VERSION "10.9.1"

NS_ :

BS_:

BU_: ADAS_Info AMP CPD DUMMY_DEBUG DUMMY_ECU EASC HUD MHU XGW_Info

BO_ 18 MHU_Climate_control: 8 CPD
  SG_ CPD_MHU_Climate_control : 7|2@0+ (1,0) [0|3] "" MHU

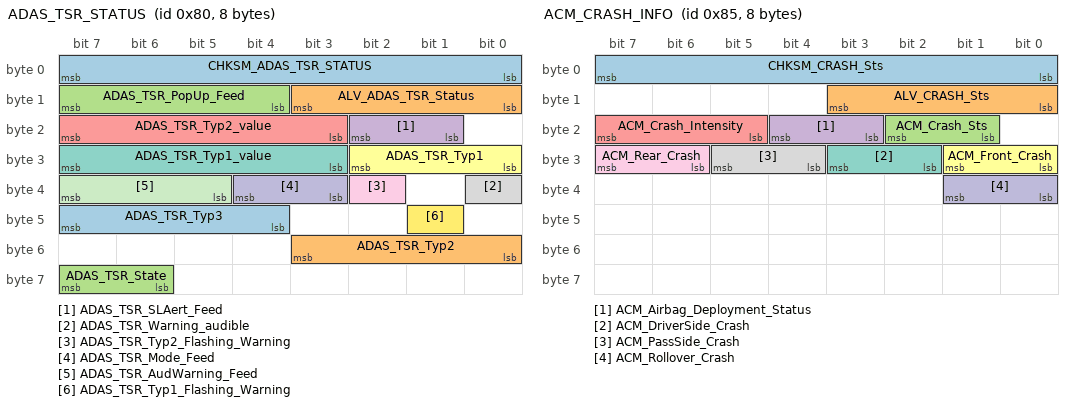
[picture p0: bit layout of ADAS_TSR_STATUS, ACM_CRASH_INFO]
BO_ 128 ADAS_TSR_STATUS: 8 ADAS_Info
  SG_ CHKSM_ADAS_TSR_STATUS : 7|8@0+ (1,0) [0|255] "" HUD,MHU
  SG_ ALV_ADAS_TSR_Status : 11|4@0+ (1,0) [0|14] "" HUD,MHU
  SG_ ADAS_TSR_PopUp_Feed : 15|4@0+ (1,0) [0|15] "-" MHU
  SG_ ADAS_TSR_SLAert_Feed : 18|2@0+ (1,0) [0|3] "-" HUD,MHU
  SG_ ADAS_TSR_Typ2_value : 23|5@0+ (1,0) [0|31] "-" HUD,MHU
  SG_ ADAS_TSR_Typ1 : 26|3@0+ (1,0) [0|7] "-" HUD,MHU
  SG_ ADAS_TSR_Typ1_value : 31|5@0+ (1,0) [0|31] "-" HUD,MHU
  SG_ ADAS_TSR_Warning_audible : 32|1@0+ (1,0) [0|1] "-" HUD,MHU
  SG_ ADAS_TSR_Typ2_Flashing_Warning : 34|1@0+ (1,0) [0|1] "-" HUD,MHU
  SG_ ADAS_TSR_Mode_Feed : 36|2@0+ (1,0) [0|3] "-" HUD,MHU
  SG_ ADAS_TSR_AudWarning_Feed : 39|3@0+ (1,0) [0|1] "-" HUD,MHU
  SG_ ADAS_TSR_Typ1_Flashing_Warning : 41|1@0+ (1,0) [0|1] "-" HUD,MHU
  SG_ ADAS_TSR_Typ3 : 47|4@0+ (1,0) [0|15] "-" HUD,MHU
  SG_ ADAS_TSR_Typ2 : 51|4@0+ (1,0) [0|15] "-" HUD,MHU
  SG_ ADAS_TSR_State : 63|2@0+ (1,0) [0|3] "-" HUD,MHU

BO_ 130 ADAS_CMP_MHU: 8 ADAS_Info
  SG_ CHKSM_ADAS_CMP_MHU : 7|8@0+ (1,0) [0|255] "" MHU
  SG_ ALV_ADAS_CMP_MHU : 11|4@0+ (1,0) [0|14] "" MHU
  SG_ ADAS_TakeOver_Request : 23|5@0+ (1,0) [0|31] "-" MHU
  SG_ ADAS_Sounds_Feed : 28|5@0+ (1,0) [0|31] "-" MHU
  SG_ SECCAN_ADAS_CMP_MHU : 63|8@0+ (1,0) [0|255] "" MHU

BO_ 133 ACM_CRASH_INFO: 8 XGW_Info
  SG_ CHKSM_CRASH_Sts : 7|8@0+ (1,0) [0|255] "" MHU
  SG_ ALV_CRASH_Sts : 11|4@0+ (1,0) [0|14] "" MHU
  SG_ ACM_Crash_Sts : 18|2@0+ (1,0) [0|3] "" MHU
  SG_ ACM_Airbag_Deployment_Status : 20|2@0+ (1,0) [0|3] "-" MHU
  SG_ ACM_Crash_Intensity : 23|3@0+ (1,0) [0|7] "" MHU
  SG_ ACM_Front_Crash : 25|2@0+ (1,0) [0|3] "-" MHU
  SG_ ACM_DriverSide_Crash : 27|2@0+ (1,0) [0|3] "" MHU
  SG_ ACM_PassSide_Crash : 29|2@0+ (1,0) [0|3] "-" MHU
  SG_ ACM_Rear_Crash : 31|2@0+ (1,0) [0|3] "-" MHU
  SG_ ACM_Rollover_Crash : 33|2@0+ (1,0) [0|3] "-" MHU

BO_ 134 ACM_CRASH_DELTA_V_INFO: 8 XGW_Info
 SG_ ACM_CrashDeltaV_PackID : 7|8@0+ (1,0) [1|9] ""  MHU
 SG_ ACM_DeltaVx_01 : 15|9@0+ (1,-250) [-250|250] "Km/h"  MHU
 SG_ ACM_DeltaVx_02 : 22|9@0+ (1,-250) [-250|250] "Km/h"  MHU
 SG_ ACM_DeltaVx_03 : 29|9@0+ (1,-250) [-250|250] "Km/h"  MHU
 SG_ ACM_DeltaVy_01 : 36|9@0+ (1,-250) [-250|250] "Km/h"  MHU
 SG_ ACM_DeltaVy_02 : 43|9@0+ (1,-250) [-250|250] "Km/h"  MHU
 SG_ ACM_DeltaVy_03 : 50|9@0+ (1,-250) [-250|250] "Km/h"  MHU

BO_ 147 IDB_MILEAGE: 4 XGW_Info
  SG_ CHKSM_MILEAGE : 7|8@0+ (1,0) [0|255] "" MHU
  SG_ ALIVE_MILEAGE : 11|4@0+ (1,0) [0|14] "" MHU
  SG_ Mileage : 23|16@0+ (1,0) [0|65535] "cm" MHU

BO_ 149 IDB_FUNCTION: 8 XGW_Info
  SG_ CHKSM_IDB_FUNCTION : 7|8@0+ (1,0) [0|255] "" MHU
  SG_ ALV_IDB_FUNCTION : 11|4@0+ (1,0) [0|14] "" MHU
  SG_ STAT_ABS : 13|2@0+ (1,0) [0|3] "" MHU
  SG_ AYC_Active : 17|2@0+ (1,0) [0|3] "Bit" MHU
  SG_ ASR_Active : 19|2@0+ (1,0) [0|3] "-" MHU
  SG_ STAT_DSC : 21|2@0+ (1,0) [0|3] "-" MHU
  SG_ DSC_Active : 23|2@0+ (1,0) [0|3] "" MHU
  SG_ HBA_ActiveSignal : 25|2@0+ (1,0) [0|3] "" MHU
  SG_ ARM_ActiveSignal : 27|2@0+ (1,0) [0|3] "-" MHU
  SG_ STAT_AutoHazardBlinking : 29|2@0+ (1,0) [0|3] "Bit" MHU
  SG_ MSR_Active : 31|2@0+ (1,0) [0|3] "-" MHU
  SG_ HSA_ActiveSignal : 33|2@0+ (1,0) [0|3] "" MHU
  SG_ EPBi_ECD_ActiveSignal : 35|2@0+ (1,0) [0|3] "" MHU
  SG_ TSM_Active : 37|2@0+ (1,0) [0|3] "-" MHU
  SG_ HAS_Available : 41|2@0+ (1,0) [0|3] "" MHU
  SG_ STAT_EBD : 43|2@0+ (1,0) [0|3] "" MHU
  SG_ EBD_Active : 45|2@0+ (1,0) [0|3] "" MHU
  SG_ ST_BRG_MSA : 55|4@0+ (1,0) [0|15] "" MHU

BO_ 150 MHU_IDB_Mode_Select: 2 MHU
  SG_ CHKSM_MHU_IDB_Mode_Select : 7|8@0+ (1,0) [0|255] "" XGW_Info
  SG_ ALV_MHU_IDB_Mode_Select : 11|4@0+ (1,0) [0|14] "" XGW_Info
  SG_ MHU_IDB_Mode_Select_Signal : 15|2@0+ (1,0) [0|3] "" XGW_Info

BO_ 200 ESC_FUNCTION: 8 XGW_Info
 SG_ CHKSM_ESC_FUNCTION : 7|8@0+ (1,0) [0|255] "" MHU
 SG_ ALV_ESC_FUNCTION : 11|4@0+ (1,0) [0|14] "" MHU
 SG_ AVH_ActiveStatus : 17|2@0+ (1,0) [0|3] "" MHU
 SG_ AVH_DispMSG : 19|2@0+ (1,0) [0|3] "" MHU
 SG_ AVH_LampReq : 21|2@0+ (1,0) [0|3] "" MHU

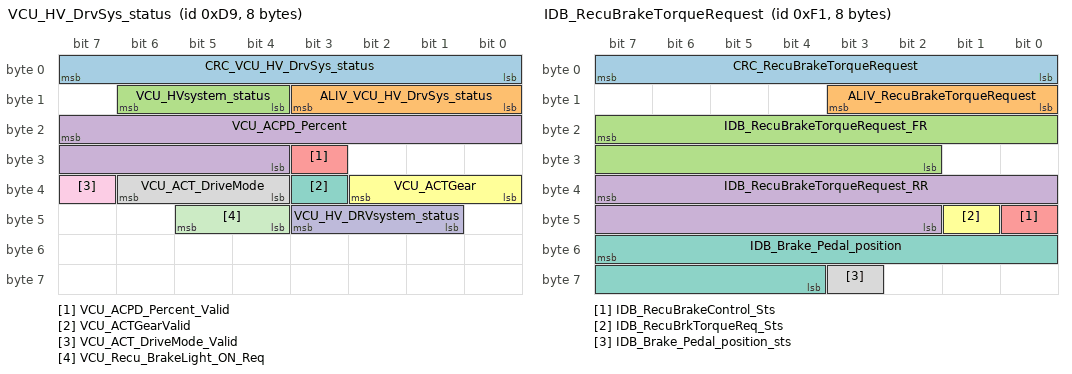
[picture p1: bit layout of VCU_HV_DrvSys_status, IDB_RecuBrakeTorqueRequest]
BO_ 217 VCU_HV_DrvSys_status: 8 XGW_Info
  SG_ CRC_VCU_HV_DrvSys_status : 7|8@0+ (1,0) [0|255] "" CPD,MHU
  SG_ ALIV_VCU_HV_DrvSys_status : 11|4@0+ (1,0) [0|14] "" CPD,MHU
  SG_ VCU_HVsystem_status : 14|3@0+ (1,0) [0|7] "-" CPD,MHU
  SG_ VCU_ACPD_Percent : 23|12@0+ (0.0625,0) [0|100] "%" CPD,MHU
  SG_ VCU_ACPD_Percent_Valid : 27|1@0+ (1,0) [0|1] "" CPD,MHU
  SG_ VCU_ACTGear : 34|3@0+ (1,0) [0|7] "" CPD,HUD,MHU
  SG_ VCU_ACTGearValid : 35|1@0+ (1,0) [0|1] "" CPD,HUD,MHU
  SG_ VCU_ACT_DriveMode : 38|3@0+ (1,0) [0|7] "" CPD,HUD,MHU
  SG_ VCU_ACT_DriveMode_Valid : 39|1@0+ (1,0) [0|1] "-" CPD,HUD,MHU
  SG_ VCU_HV_DRVsystem_status : 43|3@0+ (1,0) [0|7] "" CPD,MHU
  SG_ VCU_Recu_BrakeLight_ON_Req : 45|2@0+ (1,0) [0|3] "-" CPD,MHU

BO_ 241 IDB_RecuBrakeTorqueRequest: 8 XGW_Info
  SG_ CRC_RecuBrakeTorqueRequest : 7|8@0+ (1,0) [0|255] "" DUMMY_ECU,MHU
  SG_ ALIV_RecuBrakeTorqueRequest : 11|4@0+ (1,0) [0|14] "" DUMMY_ECU,MHU
  SG_ IDB_RecuBrakeTorqueRequest_FR : 23|14@0+ (1,0) [0|8000] "Nm" DUMMY_ECU
  SG_ IDB_RecuBrakeTorqueRequest_RR : 39|14@0+ (1,0) [0|8000] "Nm" DUMMY_ECU
  SG_ IDB_RecuBrakeControl_Sts : 40|1@0+ (1,0) [0|1] "" DUMMY_ECU
  SG_ IDB_RecuBrkTorqueReq_Sts : 41|1@0+ (1,0) [0|1] "" DUMMY_ECU
  SG_ IDB_Brake_Pedal_position : 55|12@0+ (0.0625,0) [0|100] "%" MHU
  SG_ IDB_Brake_Pedal_position_sts : 59|1@0+ (1,0) [0|1] "" MHU

BO_ 256 MHU_Vehicle_Info: 8 MHU
  SG_ CHKSM_MHU_VEH_INFO : 7|8@0+ (1,0) [0|255] "" ADAS_Info,HUD,XGW_Info
  SG_ ALV_MHU_VEH_INFO : 11|4@0+ (1,0) [0|14] "" ADAS_Info,HUD,XGW_Info
  SG_ MHU_UserProfileId : 23|4@0+ (1,0) [0|15] "-" HUD,XGW_Info
  SG_ MHU_Connectivity_Status : 47|3@0+ (1,0) [0|7] "" ADAS_Info,XGW_Info

BO_ 257 MHU_DMS_STATUS: 8 MHU
  SG_ DMS_Setting : 1|2@0+ (1,0) [0|3] "-" ADAS_Info
  SG_ DMS_Driver_registration_request : 3|2@0+ (1,0) [0|3] "-" ADAS_Info
  SG_ DMS_Driver_ID_request : 7|4@0+ (1,0) [0|15] "-" ADAS_Info
  SG_ DMS_Status : 11|2@0+ (1,0) [0|3] "-" ADAS_Info
  SG_ DMS_Image_processing : 15|3@0+ (1,0) [0|7] "-" ADAS_Info
  SG_ DMS_DriverConfirmDMSWarning : 23|1@0+ (1,0) [0|1] "" ADAS_Info
  SG_ SECCAN_DMS : 63|8@0+ (1,0) [0|255] "" ADAS_Info

BO_ 258 BCM_LOGICAL_CLAMP: 3 XGW_Info
  SG_ CHKSM_BCM_LOGICAL_CLAMP : 7|8@0+ (1,0) [0|255] "" HUD,MHU
  SG_ ALIVE_BCM_LOGICAL_CLAMP : 11|4@0+ (1,0) [0|14] "" HUD,MHU
  SG_ STAT_CL30s_Light_L : 13|2@0+ (1,0) [0|3] "" MHU
  SG_ STAT_CL30s_L : 15|2@0+ (1,0) [0|3] "Bit" HUD,MHU
  SG_ STAT_CL15Wup_L : 17|2@0+ (1,0) [0|3] "Bit" MHU
  SG_ STAT_CrankRelayHW_BCM : 19|2@0+ (1,0) [0|3] "Bit" MHU

BO_ 259 BCM_ENERGY_MANAGEMENT: 8 XGW_Info
  SG_ REQ_ConsumerControlSeatMassage : 13|2@0+ (1,0) [0|3] "" MHU
  SG_ REQ_ConsumerControlWirelessCharg : 15|2@0+ (1,0) [0|3] "-" MHU
  SG_ REQ_ConsumerControlAudioVolumeCo : 18|3@0+ (1,0) [0|7] "-" MHU
  SG_ REQ_ConsumerControlRearDefrost : 23|2@0+ (1,0) [0|3] "-" MHU
  SG_ REQ_ConsumerControlSeatHeatingRe : 31|8@0+ (1,0) [0|100] "%" MHU
  SG_ REQ_ConsumerControlSeatVentilati : 39|8@0+ (1,0) [0|100] "%" MHU
  SG_ REQ_ConsumerControlSeatHeatingFr : 47|8@0+ (1,0) [0|100] "%" MHU
  SG_ DriverIdealTimerCount : 55|8@0+ (5,0) [0|1275] "s" MHU
  SG_ REQ_ConsumerControlVentilationCl : 63|8@0+ (1,0) [0|100] "%" MHU

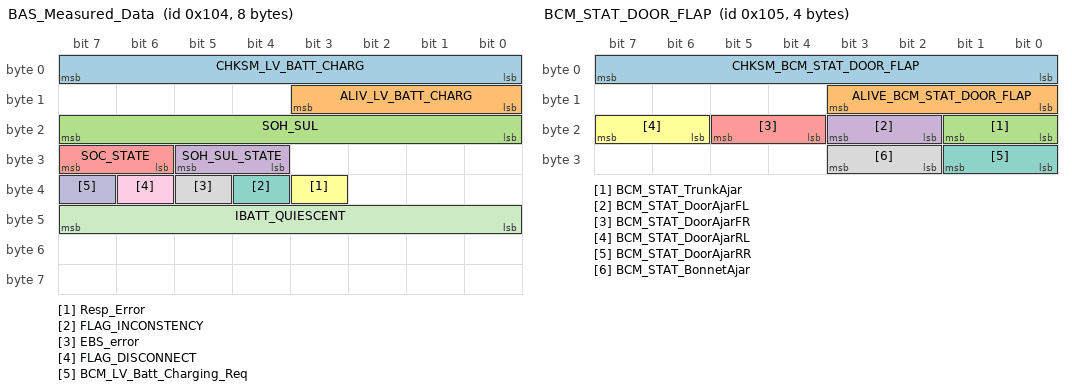
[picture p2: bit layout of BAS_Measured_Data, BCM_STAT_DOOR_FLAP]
BO_ 260 BAS_Measured_Data: 8 XGW_Info
  SG_ CHKSM_LV_BATT_CHARG : 7|8@0+ (1,0) [0|255] "" MHU
  SG_ ALIV_LV_BATT_CHARG : 11|4@0+ (1,0) [0|14] "" MHU
  SG_ SOH_SUL : 23|8@0+ (1,0) [0|100] "%" MHU
  SG_ SOH_SUL_STATE : 29|2@0+ (1,0) [0|3] "" MHU
  SG_ SOC_STATE : 31|2@0+ (1,0) [0|3] "%" MHU
  SG_ Resp_Error : 35|1@0+ (1,0) [0|1] "" MHU
  SG_ FLAG_INCONSTENCY : 36|1@0+ (1,0) [0|1] "%" MHU
  SG_ EBS_error : 37|1@0+ (1,0) [0|1] "" MHU
  SG_ FLAG_DISCONNECT : 38|1@0+ (1,0) [0|1] "" MHU
  SG_ BCM_LV_Batt_Charging_Req : 39|1@0+ (1,0) [0|1] "" MHU
  SG_ IBATT_QUIESCENT : 47|8@0+ (0.00390625,0) [0|0.984375] "" MHU

BO_ 261 BCM_STAT_DOOR_FLAP: 4 XGW_Info
  SG_ CHKSM_BCM_STAT_DOOR_FLAP : 7|8@0+ (1,0) [0|255] "" CPD,MHU
  SG_ ALIVE_BCM_STAT_DOOR_FLAP : 11|4@0+ (1,0) [0|14] "" CPD,MHU
  SG_ BCM_STAT_TrunkAjar : 17|2@0+ (1,0) [0|3] "Bit" CPD,MHU
  SG_ BCM_STAT_DoorAjarFL : 19|2@0+ (1,0) [0|3] "Bit" CPD,MHU
  SG_ BCM_STAT_DoorAjarFR : 21|2@0+ (1,0) [0|3] "Bit" CPD,MHU
  SG_ BCM_STAT_DoorAjarRL : 23|2@0+ (1,0) [0|3] "Bit" CPD,MHU
  SG_ BCM_STAT_DoorAjarRR : 25|2@0+ (1,0) [0|3] "Bit" CPD,MHU
  SG_ BCM_STAT_BonnetAjar : 27|2@0+ (1,0) [0|3] "Bit" CPD,MHU

BO_ 262 BCM_LIGHT: 8 XGW_Info
  SG_ CHKSM_BCM_LIGHT : 7|8@0+ (1,0) [0|255] "" HUD,MHU
  SG_ ALIVE_BCM_LIGHT : 11|4@0+ (1,0) [0|14] "" HUD,MHU
  SG_ BCM_DayRunningLampSts : 13|2@0+ (1,0) [0|3] "" HUD,MHU
  SG_ BCM_ReverseLightSts : 15|2@0+ (1,0) [0|3] "" HUD,MHU
  SG_ BCM_StopLightSts : 17|2@0+ (1,0) [0|3] "" HUD,MHU
  SG_ BCM_LicensePlateLightSts : 19|2@0+ (1,0) [0|3] "" HUD,MHU
  SG_ BCM_Fr_Dimming_dome_lampSts : 21|2@0+ (1,0) [0|3] "" HUD,MHU
  SG_ BCM_Rr_Dimming_dome_lampSts : 23|2@0+ (1,0) [0|3] "" HUD,MHU
  SG_ BCM_STAT_InteriorLight : 25|2@0+ (1,0) [0|3] "Bit" HUD,MHU
  SG_ BCM_STAT_LightActivation : 28|3@0+ (1,0) [0|7] "-" HUD,MHU
  SG_ BCM_HighBeamSts : 31|2@0+ (1,0) [0|3] "" HUD,MHU
  SG_ BCM_STAT_SwitchLightBrightness : 39|7@0+ (1,0) [0|100] "%" HUD,MHU
  SG_ BCM_LowBeamSts : 41|2@0+ (1,0) [0|3] "-" HUD,MHU
  SG_ BCM_RearFogLmpSts : 43|2@0+ (1,0) [0|3] "-" HUD,MHU
  SG_ BCM_FrntFogLmpSts : 45|2@0+ (1,0) [0|3] "" HUD,MHU
  SG_ BCM_PosLmpSts : 47|2@0+ (1,0) [0|3] "-" HUD,MHU
  SG_ BCM_HornSts : 53|2@0+ (1,0) [0|3] "" MHU
  SG_ BCM_TurnIndicatorSts : 55|2@0+ (1,0) [0|3] "" HUD,MHU

BO_ 263 BCM_STAT_CENTRAL_LOCK: 3 XGW_Info
  SG_ CHKSM_BCM_CENTRAL_LOCK : 7|8@0+ (1,0) [0|255] "" CPD,MHU
  SG_ ALV_BCM_CENTRAL_LOCK : 11|4@0+ (1,0) [0|14] "" CPD,MHU
  SG_ STAT_CDL_LED : 15|2@0+ (1,0) [0|3] "-" CPD,MHU
  SG_ STAT_DoorUnlockFL : 17|2@0+ (1,0) [0|3] "Bit" CPD,MHU
  SG_ STAT_ATWS : 20|3@0+ (1,0) [0|7] "Bit" CPD,MHU
  SG_ STAT_DoorLockFL : 23|2@0+ (1,0) [0|3] "Bit" CPD,MHU

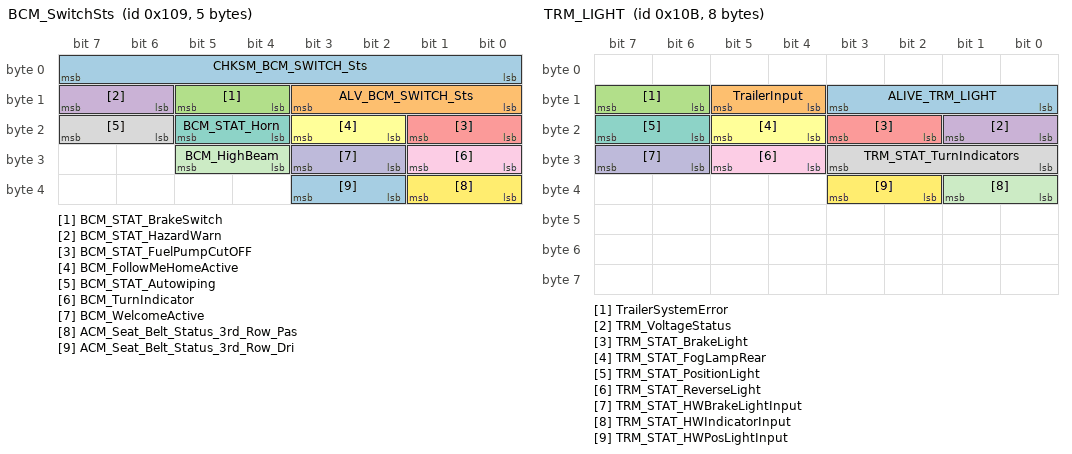
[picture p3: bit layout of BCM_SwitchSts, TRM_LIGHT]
BO_ 265 BCM_SwitchSts: 5 XGW_Info
  SG_ CHKSM_BCM_SWITCH_Sts : 7|8@0+ (1,0) [0|255] "" MHU
  SG_ ALV_BCM_SWITCH_Sts : 11|4@0+ (1,0) [0|14] "" MHU
  SG_ BCM_STAT_BrakeSwitch : 13|2@0+ (1,0) [0|3] "" MHU
  SG_ BCM_STAT_HazardWarn : 15|2@0+ (1,0) [0|3] "-" MHU
  SG_ BCM_STAT_FuelPumpCutOFF : 17|2@0+ (1,0) [0|3] "" MHU
  SG_ BCM_FollowMeHomeActive : 19|2@0+ (1,0) [0|3] "" MHU
  SG_ BCM_STAT_Horn : 21|2@0+ (1,0) [0|3] "-" MHU
  SG_ BCM_STAT_Autowiping : 23|2@0+ (1,0) [0|3] "" MHU
  SG_ BCM_TurnIndicator : 25|2@0+ (1,0) [0|3] "" MHU
  SG_ BCM_WelcomeActive : 27|2@0+ (1,0) [0|3] "-" MHU
  SG_ BCM_HighBeam : 29|2@0+ (1,0) [0|3] "" MHU
  SG_ ACM_Seat_Belt_Status_3rd_Row_Pas : 33|2@0+ (1,0) [0|3] "" MHU
  SG_ ACM_Seat_Belt_Status_3rd_Row_Dri : 35|2@0+ (1,0) [0|3] "-" MHU

BO_ 266 BCM_VOLTAGE: 8 XGW_Info
  SG_ CHKSM_BCM_VOLTAGE : 7|8@0+ (1,0) [0|255] "" ADAS_Info,AMP,CPD,EASC,HUD,MHU
  SG_ ALIVE_BCM_VOLTAGE : 11|4@0+ (1,0) [0|14] "" ADAS_Info,AMP,CPD,EASC,HUD,MHU
  SG_ LV_BatteryType : 13|2@0+ (1,0) [0|3] "Number" MHU
  SG_ UBatt : 23|14@0+ (0.0009777,3) [3|18] "V" ADAS_Info,AMP,CPD,EASC,HUD,MHU
  SG_ LV_Batt_Temp : 39|8@0+ (1,-40) [-40|105] "Degree C" ADAS_Info,AMP,CPD,EASC,HUD,MHU
  SG_ LV_SOC : 47|8@0+ (1,0) [0|100] "%" ADAS_Info,AMP,CPD,EASC,HUD,MHU
  SG_ LV_Batt_Current : 55|16@0+ (0.03125,-1536) [-1536|511.90625] "A" ADAS_Info,AMP,CPD,EASC,HUD,MHU

BO_ 267 TRM_LIGHT: 8 XGW_Info
  SG_ ALIVE_TRM_LIGHT : 11|4@0+ (1,0) [0|14] "" MHU
  SG_ TrailerInput : 13|2@0+ (1,0) [0|3] "" MHU
  SG_ TrailerSystemError : 15|2@0+ (1,0) [0|3] "" MHU
  SG_ TRM_VoltageStatus : 17|2@0+ (1,0) [0|3] "" MHU
  SG_ TRM_STAT_BrakeLight : 19|2@0+ (1,0) [0|3] "" MHU
  SG_ TRM_STAT_FogLampRear : 21|2@0+ (1,0) [0|3] "" MHU
  SG_ TRM_STAT_PositionLight : 23|2@0+ (1,0) [0|3] "" MHU
  SG_ TRM_STAT_TurnIndicators : 27|4@0+ (1,0) [0|15] "" MHU
  SG_ TRM_STAT_ReverseLight : 29|2@0+ (1,0) [0|3] "" MHU
  SG_ TRM_STAT_HWBrakeLightInput : 31|2@0+ (1,0) [0|3] "" MHU
  SG_ TRM_STAT_HWIndicatorInput : 33|2@0+ (1,0) [0|3] "" MHU
  SG_ TRM_STAT_HWPosLightInput : 35|2@0+ (1,0) [0|3] "" MHU

BO_ 268 BCM_RemoteCtrlSts: 8 XGW_Info
  SG_ Checksum_0x10C : 7|8@0+ (1,0) [0|255] "" MHU
  SG_ Rolling_Counter_0x10C : 11|4@0+ (1,0) [0|14] "" MHU
  SG_ BCM_TboxAuthStatus : 23|2@0+ (1,0) [0|3] "-" MHU
  SG_ BCM_RandomNum32bit : 31|32@0+ (1,0) [0|4294967295] "-" MHU

BO_ 269 MHU_BCM_DoorsCtrl: 8 MHU
  SG_ MHU_APM_ReqWindow : 3|2@0+ (1,0) [0|3] "-" XGW_Info
  SG_ MHU_BCM_RemoteDoorCtrl : 5|2@0+ (1,0) [0|3] "-" XGW_Info
  SG_ MHU_BCM_reqTrunk : 7|2@0+ (1,0) [0|3] "-" XGW_Info
  SG_ MHU_BCM_reqFrunk : 9|2@0+ (1,0) [0|3] "-" XGW_Info
  SG_ MHU_BCM_ReqSunroof : 23|8@0+ (1,0) [0|255] "%" XGW_Info
  SG_ TBOX_AuthCode_0x10D : 55|16@0+ (1,0) [0|65535] "-" XGW_Info

BO_ 270 BCM_ENTRY_CONTROL: 3 XGW_Info
  SG_ RemoteAccessKey : 7|4@0+ (1,0) [0|15] "-" CPD,MHU
  SG_ PassiveAccessTrunk : 9|2@0+ (1,0) [0|3] "-" CPD,MHU
  SG_ ComfortOpen : 11|2@0+ (1,0) [0|3] "-" CPD,MHU
  SG_ PassiveAccessDoor : 13|2@0+ (1,0) [0|3] "-" CPD,MHU
  SG_ FksOpen : 15|2@0+ (1,0) [0|3] "" CPD,MHU

BO_ 271 MHU_BCM_HornLightControl: 8 MHU
  SG_ MHU_SetHornOnOff : 3|2@0+ (1,0) [0|3] "-" XGW_Info
  SG_ MHU_SetLowBeam : 5|2@0+ (1,0) [0|3] "" XGW_Info
  SG_ MHU_SetHighBeam : 7|2@0+ (1,0) [0|3] "" XGW_Info
  SG_ TBOX_AuthCode_0x10F : 55|16@0+ (1,0) [0|65535] "-" XGW_Info

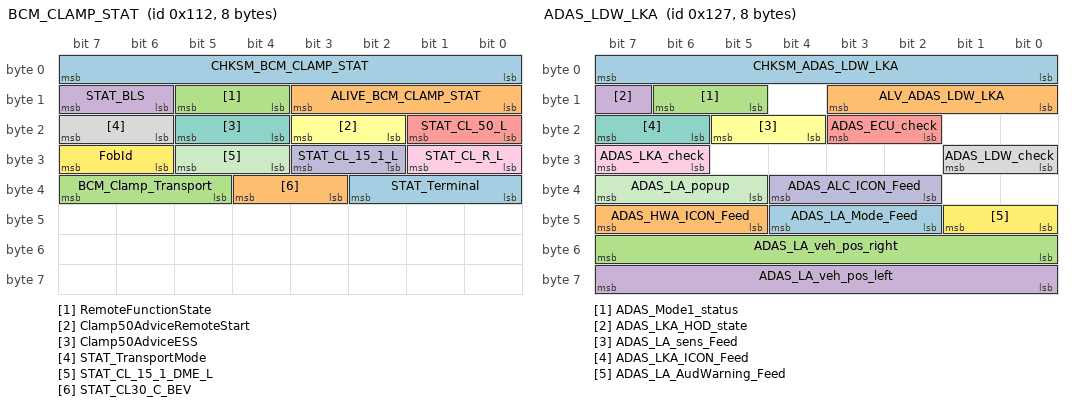
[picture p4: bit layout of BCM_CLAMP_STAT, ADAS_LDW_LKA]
BO_ 274 BCM_CLAMP_STAT: 8 XGW_Info
  SG_ CHKSM_BCM_CLAMP_STAT : 7|8@0+ (1,0) [0|255] "" ADAS_Info,AMP,EASC,HUD,MHU
  SG_ ALIVE_BCM_CLAMP_STAT : 11|4@0+ (1,0) [0|14] "" ADAS_Info,AMP,EASC,HUD,MHU
  SG_ RemoteFunctionState : 13|2@0+ (1,0) [0|3] "" ADAS_Info,AMP,EASC,HUD,MHU
  SG_ STAT_BLS : 15|2@0+ (1,0) [0|3] "-" ADAS_Info,AMP,EASC,HUD,MHU
  SG_ STAT_CL_50_L : 17|2@0+ (1,0) [0|3] "" ADAS_Info,AMP,EASC,HUD,MHU
  SG_ Clamp50AdviceRemoteStart : 19|2@0+ (1,0) [0|3] "-" ADAS_Info,AMP,EASC,HUD,MHU
  SG_ Clamp50AdviceESS : 21|2@0+ (1,0) [0|3] "-" ADAS_Info,AMP,EASC,HUD,MHU
  SG_ STAT_TransportMode : 23|2@0+ (1,0) [0|3] "" MHU
  SG_ STAT_CL_R_L : 25|2@0+ (1,0) [0|3] "" ADAS_Info,AMP,EASC,HUD,MHU
  SG_ STAT_CL_15_1_L : 27|2@0+ (1,0) [0|3] "-" ADAS_Info,AMP,EASC,HUD,MHU
  SG_ STAT_CL_15_1_DME_L : 29|2@0+ (1,0) [0|3] "" ADAS_Info,AMP,EASC,HUD,MHU
  SG_ FobId : 31|2@0+ (1,0) [0|3] "Bit" ADAS_Info,AMP,EASC,HUD,MHU
  SG_ STAT_Terminal : 34|3@0+ (1,0) [0|7] "Bit" ADAS_Info,AMP,CPD,EASC,HUD,MHU
  SG_ STAT_CL30_C_BEV : 36|2@0+ (1,0) [0|3] "Bit" ADAS_Info,AMP,EASC,HUD,MHU
  SG_ BCM_Clamp_Transport : 39|3@0+ (1,0) [0|7] "" ADAS_Info,AMP,EASC,HUD,MHU

BO_ 276 BCM_LVBAT_Data: 8 XGW_Info
  SG_ CHKSM_LVBAT_DATA : 7|8@0+ (1,0) [0|255] ""  MHU
  SG_ ALIV_LVBAT_DATA : 11|4@0+ (1,0) [0|14] ""  MHU
  SG_ LV_ErrorSts : 14|3@0+ (1,0) [0|7] ""  MHU
  SG_ LV_MinCellVolt : 23|8@0+ (0.015625,1) [1|5] "V"  MHU
  SG_ LV_MaxCellVolt : 31|8@0+ (0.015625,1) [1|5] "V"  MHU
  SG_ LV_MinCellTemp : 39|8@0+ (1,-40) [-40|215] "Degree C"  MHU
  SG_ LV_MaxCellTemp : 47|8@0+ (1,-40) [-40|215] "Degree C"  MHU
  SG_ LV_Discharger_Err : 48|1@0+ (1,0) [0|1] ""  MHU
  SG_ LV_Discharger_Sts : 49|1@0+ (1,0) [0|1] ""  MHU
  SG_ LV_Charger_Err : 50|1@0+ (1,0) [0|1] ""  MHU
  SG_ LV_Charger_Sts : 51|1@0+ (1,0) [0|1] ""  MHU
  SG_ LV_OverVoltage : 52|1@0+ (1,0) [0|1] ""  MHU
  SG_ LV_UnderVoltage : 53|1@0+ (1,0) [0|1] ""  MHU
  SG_ LV_OverCurrent : 54|1@0+ (1,0) [0|1] ""  MHU
  SG_ LV_UnderTemp : 55|1@0+ (1,0) [0|1] ""  MHU
  SG_ LV_OverTemp : 56|1@0+ (1,0) [0|1] ""  MHU
  SG_ LV_OverCharge : 57|1@0+ (1,0) [0|1] ""  MHU
  SG_ LV_OverDischarge : 58|1@0+ (1,0) [0|1] ""  MHU
  SG_ LV_CellBalance_Sts : 59|1@0+ (1,0) [0|1] ""  MHU
  SG_ LV_CellBalance_Error : 60|1@0+ (1,0) [0|1] ""  MHU
  SG_ LV_ThermalRunaway : 61|1@0+ (1,0) [0|1] ""  MHU
  SG_ LV_WarmupRequest : 63|2@0+ (1,0) [0|3] "" MHU

BO_ 277 BCM_Childlock: 8 XGW_Info
  SG_ BCM_ChildLock_Feedback : 7|2@0+ (1,0) [0|3] "" MHU

BO_ 282 MHU_ServiceMode_Setting: 8 MHU
  SG_ MHU_SET_WiperServicePositionMod : 5|2@0+ (1,0) [0|3] "" XGW_Info
  SG_ MHU_Read_KeyFobOnCenterConsole : 7|2@0+ (1,0) [0|3] "" XGW_Info

BO_ 283 MHU_BCM_RemoteClampCtrl: 8 MHU
  SG_ TBOX_STAT_TerminalReq : 7|3@0+ (1,0) [0|7] "-" XGW_Info
  SG_ TBOX_AuthCode_0x11B : 55|16@0+ (1,0) [0|65535] "" XGW_Info

BO_ 284 MHU_BCM_FOTAClampCtrl: 8 MHU
  SG_ TBOX_FOTA_STAT_TerminalReq : 7|3@0+ (1,0) [0|7] "-" XGW_Info

BO_ 288 BMS_AllowChargeCurr: 8 XGW_Info
  SG_ Checksum_0x126 : 7|8@0+ (1,0) [0|255] "" MHU
  SG_ Rolling_Counter_0x126 : 11|4@0+ (1,0) [0|14] "" MHU
  SG_ BMS_AllowChgCurr : 23|16@0+ (0.1,0) [0|1500] "A" MHU
  SG_ BMS_AllowChgCurrPeak : 39|16@0+ (0.1,0) [0|1500] "A" DUMMY_ECU
  SG_ SECCAN_BMS_AllowChargeCurr : 63|8@0+ (1,0) [0|255] "" DUMMY_ECU

BO_ 291 VCU_ACCharging_Info: 8 XGW_Info
  SG_ CHKSM_ACChargingInfo : 7|8@0+ (1,0) [0|255] "" MHU
  SG_ ALIVE_ACChargingInfo : 11|4@0+ (1,0) [0|14] "" MHU
  SG_ ACCharging_MaxChargingPower : 23|10@0+ (0.1,0) [0|102.2] "kW" MHU
  SG_ CurrentACChargingPower : 39|16@0+ (0.1,0) [0|6553.5] "kW" MHU
  SG_ ACCharging_MaxCurrent : 55|16@0+ (0.1,0) [0|3276.7] "A" MHU

BO_ 292 VCU_DCCharging_Info: 8 XGW_Info
  SG_ CHKSM_DCChargingInfo : 7|8@0+ (1,0) [0|255] "" MHU
  SG_ ALIVE_DCChargingInfo : 11|4@0+ (1,0) [0|14] "" MHU
  SG_ DCCharging_MaxChargingPower : 23|16@0+ (0.1,0) [0|6553.5] "kW" MHU
  SG_ CurrentDCChargingPower : 39|16@0+ (0.1,0) [0|6553.5] "kW" MHU
  SG_ DCCharging_MaxCurrent : 55|16@0+ (0.1,0) [0|3276.7] "A" MHU

BO_ 293 BMS_AllowDischargeCurr: 8 XGW_Info
  SG_ Checksum_0x125 : 7|8@0+ (1,0) [0|255] "" MHU
  SG_ Rolling_Counter_0x125 : 11|4@0+ (1,0) [0|14] "" MHU
  SG_ BMS_AllowDischgCurr : 23|16@0+ (0.1,0) [0|1500] "A" MHU
  SG_ BMS_AllowDischgCurrPeak : 39|16@0+ (0.1,0) [0|1500] "A" DUMMY_ECU
  SG_ SECCAN_BMS_AllowDischargeCurr : 63|8@0+ (1,0) [0|255] "" DUMMY_ECU

BO_ 294 MHU_ISA_Speed: 1 MHU
  SG_ MHU_ISA_SpeedLimitCon_Percent : 3|3@0+ (1,0) [0|7] "-" ADAS_Info
  SG_ MHU_ISA_Speed_Setting : 7|4@0+ (1,0) [0|15] "-" ADAS_Info

BO_ 295 ADAS_LDW_LKA: 8 ADAS_Info
  SG_ CHKSM_ADAS_LDW_LKA : 7|8@0+ (1,0) [0|255] "" HUD,MHU
  SG_ ALV_ADAS_LDW_LKA : 11|4@0+ (1,0) [0|14] "" HUD,MHU
  SG_ ADAS_Mode1_status : 14|2@0+ (1,0) [0|3] "-" HUD,MHU
  SG_ ADAS_LKA_HOD_state : 15|1@0+ (1,0) [0|1] "-" HUD,MHU
  SG_ ADAS_ECU_check : 19|2@0+ (1,0) [0|3] "-" HUD,MHU
  SG_ ADAS_LA_sens_Feed : 21|2@0+ (1,0) [0|3] "-" HUD,MHU
  SG_ ADAS_LKA_ICON_Feed : 23|2@0+ (1,0) [0|3] "-" HUD,MHU
  SG_ ADAS_LDW_check : 25|2@0+ (1,0) [0|3] "-" HUD,MHU
  SG_ ADAS_LKA_check : 31|2@0+ (1,0) [0|3] "-" HUD,MHU
  SG_ ADAS_ALC_ICON_Feed : 36|3@0+ (1,0) [0|7] "-" HUD,MHU
  SG_ ADAS_LA_popup : 39|3@0+ (1,0) [0|7] "-" HUD,MHU
  SG_ ADAS_LA_AudWarning_Feed : 41|2@0+ (1,0) [0|3] "-" HUD,MHU
  SG_ ADAS_LA_Mode_Feed : 44|3@0+ (1,0) [0|7] "-" HUD,MHU
  SG_ ADAS_HWA_ICON_Feed : 47|3@0+ (1,0) [0|7] "-" HUD,MHU
  SG_ ADAS_LA_veh_pos_right : 55|8@0- (0.1,0) [-12.8|12.7] "m" HUD,MHU
  SG_ ADAS_LA_veh_pos_left : 63|8@0- (0.1,0) [-12.8|12.7] "m" HUD,MHU

BO_ 296 ADAS_FCW_RCTA: 8 ADAS_Info
  SG_ CHKSM_ADAS_FCW_RCTA : 7|8@0+ (1,0) [0|255] "" HUD,MHU
  SG_ ALV_ADAS_FCW_RCTA : 11|4@0+ (1,0) [0|14] "" HUD,MHU
  SG_ ADAS_RCTA_IndLeft : 13|2@0+ (1,0) [0|3] "-" HUD,MHU
  SG_ ADAS_RCTA_IndRight : 15|2@0+ (1,0) [0|3] "-" HUD,MHU
  SG_ ADAS_RCTA_SndWarn : 17|2@0+ (1,0) [0|3] "-" HUD,MHU
  SG_ ADAS_IA_check : 18|1@0+ (1,0) [0|1] "-" HUD,MHU
  SG_ ADAS_RCTA_state : 21|3@0+ (1,0) [0|7] "-" HUD,MHU
  SG_ ADAS_RCTA_sens_Feed : 23|2@0+ (1,0) [0|3] "-" HUD,MHU
  SG_ ADAS_IA_Left_warning : 25|2@0+ (1,0) [0|3] "-" HUD,MHU
  SG_ ADAS_FCW_Mode_Feed : 26|1@0+ (1,0) [0|1] "-" HUD,MHU
  SG_ ADAS_FCW_Sens_Feed : 28|2@0+ (1,0) [0|3] "-" HUD,MHU
  SG_ ADAS_FCW_state : 31|2@0+ (1,0) [0|3] "-" HUD,MHU
  SG_ ADAS_IA_state : 34|3@0+ (1,0) [0|7] "-" HUD,MHU
  SG_ ADAS_FCW_check : 36|2@0+ (1,0) [0|3] "-" HUD,MHU
  SG_ ADAS_IA_Right_warning : 38|2@0+ (1,0) [0|3] "-" HUD,MHU
  SG_ ADAS_IA_Mode_Feed : 39|1@0+ (1,0) [0|1] "-" HUD,MHU
  SG_ ADAS_RCTA_check : 42|2@0+ (1,0) [0|3] "-" HUD,MHU
  SG_ ADAS_RCTA_Mode_Feed : 43|1@0+ (1,0) [0|1] "-" HUD,MHU
  SG_ ADAS_FCW_warning : 47|2@0+ (1,0) [0|3] "-" HUD,MHU
  SG_ ADAS_LA_LeftLaneColor_Feed : 50|3@0+ (1,0) [0|7] "-" HUD,MHU
  SG_ ADAS_LA_RightLaneColor_Feed : 53|3@0+ (1,0) [0|7] "-" HUD,MHU

BO_ 297 MHU_LOCALSETTING: 8 MHU
  SG_ CHKSM_MHU_LocalSetting : 7|8@0+ (1,0) [0|255] "" ADAS_Info,HUD
  SG_ ALIVE_MHU_LocalSetting : 11|4@0+ (1,0) [0|14] "" ADAS_Info,HUD
  SG_ MHU_SETTING_DMSWarning : 47|2@0+ (1,0) [0|3] "" ADAS_Info,HUD
  SG_ MHU_STAT_SelectedCountry : 55|10@0+ (1,0) [0|1023] "" ADAS_Info,HUD

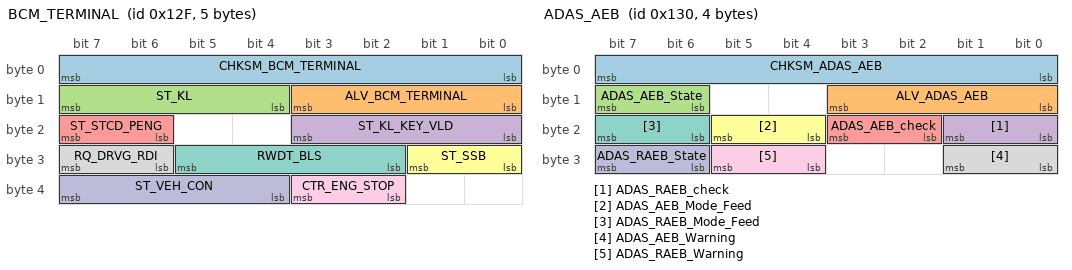
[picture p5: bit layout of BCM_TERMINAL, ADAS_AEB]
BO_ 303 BCM_TERMINAL: 5 XGW_Info
  SG_ CHKSM_BCM_TERMINAL : 7|8@0+ (1,0) [0|255] "" EASC,HUD,MHU
  SG_ ALV_BCM_TERMINAL : 11|4@0+ (1,0) [0|14] "" EASC,HUD,MHU
  SG_ ST_KL : 15|4@0+ (1,0) [0|15] "-" HUD,MHU
  SG_ ST_KL_KEY_VLD : 19|4@0+ (1,0) [0|15] "" HUD,MHU
  SG_ ST_STCD_PENG : 23|2@0+ (1,0) [0|3] "" HUD,MHU
  SG_ ST_SSB : 25|2@0+ (1,0) [0|3] "-" HUD,MHU
  SG_ RWDT_BLS : 29|4@0+ (1,0) [0|15] "-" HUD,MHU
  SG_ RQ_DRVG_RDI : 31|2@0+ (1,0) [0|3] "" HUD,MHU
  SG_ CTR_ENG_STOP : 35|2@0+ (1,0) [0|3] "Bit" HUD,MHU
  SG_ ST_VEH_CON : 39|4@0+ (1,0) [0|15] "-" EASC,HUD

BO_ 304 ADAS_AEB: 4 ADAS_Info
  SG_ CHKSM_ADAS_AEB : 7|8@0+ (1,0) [0|255] "" HUD,MHU
  SG_ ALV_ADAS_AEB : 11|4@0+ (1,0) [0|14] "" HUD,MHU
  SG_ ADAS_AEB_State : 15|2@0+ (1,0) [0|3] "-" HUD,MHU
  SG_ ADAS_RAEB_check : 17|2@0+ (1,0) [0|3] "-" HUD,MHU
  SG_ ADAS_AEB_check : 19|2@0+ (1,0) [0|3] "-" HUD,MHU
  SG_ ADAS_AEB_Mode_Feed : 21|2@0+ (1,0) [0|3] "-" HUD,MHU
  SG_ ADAS_RAEB_Mode_Feed : 23|2@0+ (1,0) [0|3] "-" HUD,MHU
  SG_ ADAS_AEB_Warning : 25|2@0+ (1,0) [0|3] "-" HUD,MHU
  SG_ ADAS_RAEB_Warning : 29|2@0+ (1,0) [0|3] "-" HUD,MHU
  SG_ ADAS_RAEB_State : 31|2@0+ (1,0) [0|3] "-" HUD,MHU

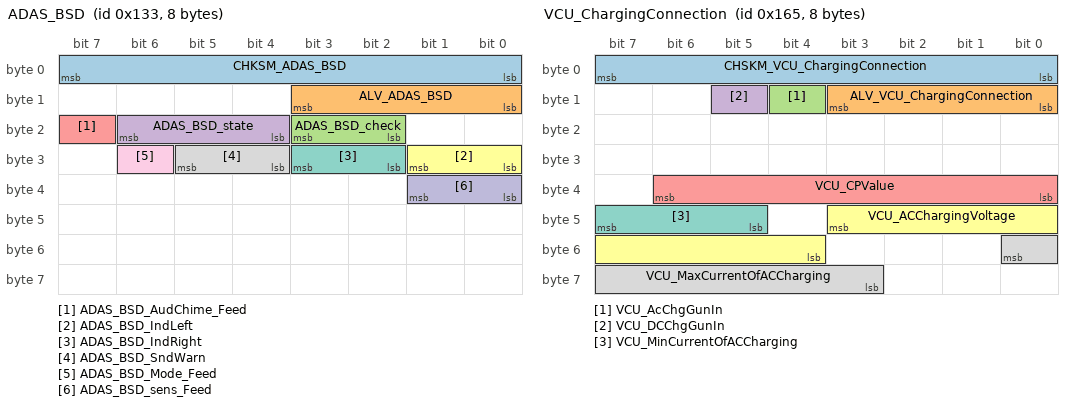
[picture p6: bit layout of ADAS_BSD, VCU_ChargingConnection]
BO_ 307 ADAS_BSD: 8 ADAS_Info
  SG_ CHKSM_ADAS_BSD : 7|8@0+ (1,0) [0|255] "" HUD,MHU
  SG_ ALV_ADAS_BSD : 11|4@0+ (1,0) [0|14] "" HUD,MHU
  SG_ ADAS_BSD_check : 19|2@0+ (1,0) [0|3] "-" HUD,MHU
  SG_ ADAS_BSD_state : 22|3@0+ (1,0) [0|7] "-" HUD,MHU
  SG_ ADAS_BSD_AudChime_Feed : 23|1@0+ (1,0) [0|1] "-" HUD,MHU
  SG_ ADAS_BSD_IndLeft : 25|2@0+ (1,0) [0|3] "-" HUD,MHU
  SG_ ADAS_BSD_IndRight : 27|2@0+ (1,0) [0|3] "-" HUD,MHU
  SG_ ADAS_BSD_SndWarn : 29|2@0+ (1,0) [0|3] "-" HUD,MHU
  SG_ ADAS_BSD_Mode_Feed : 30|1@0+ (1,0) [0|1] "-" HUD,MHU
  SG_ ADAS_BSD_sens_Feed : 33|2@0+ (1,0) [0|3] "-" HUD,MHU

BO_ 308 ADAS_Speed_Display: 8 ADAS_Info
  SG_ CHKSM_ADAS_Speed_Display : 7|8@0+ (1,0) [0|255] "" HUD,MHU
  SG_ ALV_ADAS_Speed_Display : 11|4@0+ (1,0) [0|14] "" HUD,MHU
  SG_ ADAS_ISA_SpeedLimitCnt_Spd_Feed : 15|4@0+ (1,0) [0|15] "-" HUD,MHU
  SG_ ADAS_ISA_SpeedLimitCnt_Per_Feed : 18|3@0+ (1,0) [0|7] "-" HUD,MHU
  SG_ ADAS_far_lane_info : 20|2@0+ (1,0) [0|3] "-" HUD,MHU

BO_ 310 MHU_PnC_triggerMsg: 8 MHU
  SG_ PnC_activation : 7|2@0+ (1,0) [0|3] "" XGW_Info
  SG_ PnCandEIM_Switch : 9|2@0+ (1,0) [0|3] "" XGW_Info
  SG_ PnC_trigger1 : 11|2@0+ (1,0) [0|3] "" XGW_Info
  SG_ PnC_trigger2 : 15|4@0+ (1,0) [0|15] "" XGW_Info
  SG_ PnC_Cert_Del : 18|3@0+ (1,0) [0|7] "" XGW_Info
  SG_ PnC_feature_enable : 20|2@0+ (1,0) [0|3] "" XGW_Info

BO_ 311 VCU_PnC_ErrorMsg: 8 XGW_Info
  SG_ OK_OldSessionJoined : 1|2@0+ (1,0) [0|3] "" MHU
  SG_ OK_NewSessionEstablished : 3|2@0+ (1,0) [0|3] "" MHU
  SG_ OK_CertificateExpireSoon : 5|2@0+ (1,0) [0|3] "" MHU
  SG_ PnC_OK : 7|2@0+ (1,0) [0|3] "" MHU
  SG_ Failed_CertificateNoAllowAtEVSE : 9|2@0+ (1,0) [0|3] "" MHU
  SG_ Failed_ContactorError : 11|2@0+ (1,0) [0|3] "" MHU
  SG_ Failed_NoChargeServiceSelectd : 13|2@0+ (1,0) [0|3] "" MHU
  SG_ PnC_Failed : 15|2@0+ (1,0) [0|3] "" MHU
  SG_ Failed_ServiceIDInvalid : 17|2@0+ (1,0) [0|3] "" MHU
  SG_ Falied_UnknownSession : 19|2@0+ (1,0) [0|3] "" MHU
  SG_ Failed_SignatureError : 21|2@0+ (1,0) [0|3] "" MHU
  SG_ Failed_SequenceError : 23|2@0+ (1,0) [0|3] "" MHU
  SG_ Failed_CertChainError : 25|2@0+ (1,0) [0|3] "" MHU
  SG_ Failed_NoCertificateAvailable : 27|2@0+ (1,0) [0|3] "" MHU
  SG_ Failed_CertificateRevoked : 29|2@0+ (1,0) [0|3] "" MHU
  SG_ Failed_PaymentSelectionInvalid : 31|2@0+ (1,0) [0|3] "" MHU
  SG_ Failed_WrongChargeParameter : 33|2@0+ (1,0) [0|3] "" MHU
  SG_ Failed_WrongEnergyTranferMode : 35|2@0+ (1,0) [0|3] "" MHU
  SG_ Failed_ChallengeInvalid : 37|2@0+ (1,0) [0|3] "" MHU
  SG_ Failed_ContractCancelled : 39|2@0+ (1,0) [0|3] "" MHU
  SG_ Failed_MeteringSignatureNotValid : 41|2@0+ (1,0) [0|3] "" MHU
  SG_ Failed_PowerDeliverNotApplied : 43|2@0+ (1,0) [0|3] "" MHU
  SG_ Failed_TarrifSelectionInvalid : 45|2@0+ (1,0) [0|3] "" MHU
  SG_ Failed_ChargingProfileInvalid : 47|2@0+ (1,0) [0|3] "" MHU
  SG_ Error_message_4 : 49|2@0+ (1,0) [0|3] "" MHU
  SG_ Error_message_3 : 51|2@0+ (1,0) [0|3] "" MHU
  SG_ Error_message_1 : 53|2@0+ (1,0) [0|3] "" MHU
  SG_ Error_message_2 : 55|2@0+ (1,0) [0|3] "" MHU
  SG_ PnC_ChargeSessionEnded : 57|2@0+ (1,0) [0|3] "" MHU
  SG_ PnC_Status : 59|2@0+ (1,0) [0|3] "" MHU
  SG_ PnC_Contract_Status : 61|2@0+ (1,0) [0|3] "" MHU
  SG_ Error_message_5 : 63|2@0+ (1,0) [0|3] "" MHU

BO_ 312 ADAS_AVM_Sts: 8 ADAS_Info
  SG_ CHKSM_ADAS_AVM_Sts : 7|8@0+ (1,0) [0|255] "" MHU
  SG_ ALV_ADAS_AVM_Sts : 11|4@0+ (1,0) [0|14] "" MHU
  SG_ AVM_AutoDsplSts : 23|1@0+ (1,0) [0|1] "" MHU
  SG_ AVM_auxiliarylineSts : 40|1@0+ (1,0) [0|1] "-" MHU
  SG_ AVM_ShowAVMFdbck : 49|2@0+ (1,0) [0|3] "-" MHU
  SG_ AVM_Sts : 63|3@0+ (1,0) [0|7] "-" MHU

BO_ 313 APA_SENSOR: 8 ADAS_Info
  SG_ APA_SensorFaultStsSRR : 4|1@0+ (1,0) [0|1] "-" MHU
  SG_ APA_SensorFaultStsSRL : 5|1@0+ (1,0) [0|1] "-" MHU
  SG_ APA_SensorFaultStsSFR : 6|1@0+ (1,0) [0|1] "-" MHU
  SG_ APA_SensorFaultStsSFL : 7|1@0+ (1,0) [0|1] "-" MHU
  SG_ SECCAN_APA_Snsr : 63|8@0+ (1,0) [0|255] "" MHU

BO_ 317 VCU_PnC_ErrorMsg_2: 8 XGW_Info
  SG_ SessionPaymentType : 7|2@0+ (1,0) [0|3] "" MHU

BO_ 318 ADAS_APA_SLOT1INFO1: 8 ADAS_Info
  SG_ APA_slot_ID_1_P0_X : 7|14@0+ (0.01,-80) [-80|83.3] "-" MHU
  SG_ APA_slot_ID_1_P0_Y : 23|14@0+ (0.01,-80) [-80|83.3] "-" MHU
  SG_ APA_slot_ID_1_P1_X : 39|14@0+ (0.01,-80) [-80|83.3] "-" MHU
  SG_ APA_slot_ID_1_P1_Y : 55|14@0+ (0.01,-80) [-80|83.3] "-" MHU

BO_ 319 ADAS_APA_SLOT1INFO2: 8 ADAS_Info
  SG_ APA_slot_ID_1_P2_X : 7|14@0+ (0.01,-80) [-80|83.3] "-" MHU
  SG_ APA_slot_ID_1_P2_Y : 23|14@0+ (0.01,-80) [-80|83.3] "-" MHU
  SG_ APA_slot_ID_1_P3_X : 39|14@0+ (0.01,-80) [-80|83.3] "-" MHU
  SG_ APA_slot_ID_1_P3_Y : 55|14@0+ (0.01,-80) [-80|83.3] "-" MHU

BO_ 320 ADAS_APA_SLOT1INFO3: 8 ADAS_Info
  SG_ APA_ParkingSlotType1 : 9|2@0+ (1,0) [0|3] "-" MHU
  SG_ APA_slot_1 : 39|8@0+ (1,0) [0|255] "-" MHU
  SG_ SECCAN_APA_Slot1Info : 63|8@0+ (1,0) [0|255] "" MHU

BO_ 321 ADAS_APA_SLOT2INFO1: 8 ADAS_Info
  SG_ APA_slot_ID_2_P0_X : 7|14@0+ (0.01,-80) [-80|83.3] "-" MHU
  SG_ APA_slot_ID_2_P0_Y : 23|14@0+ (0.01,-80) [-80|83.3] "-" MHU
  SG_ APA_slot_ID_2_P1_X : 39|14@0+ (0.01,-80) [-80|83.3] "-" MHU
  SG_ APA_slot_ID_2_P1_Y : 55|14@0+ (0.01,-80) [-80|83.3] "-" MHU

BO_ 322 ADAS_APA_SLOT2INFO2: 8 ADAS_Info
  SG_ APA_slot_ID_2_P2_X : 7|14@0+ (0.01,-80) [-80|83.3] "-" MHU
  SG_ APA_slot_ID_2_P2_Y : 23|14@0+ (0.01,-80) [-80|83.3] "-" MHU
  SG_ APA_slot_ID_2_P3_X : 39|14@0+ (0.01,-80) [-80|83.3] "-" MHU
  SG_ APA_slot_ID_2_P3_Y : 55|14@0+ (0.01,-80) [-80|83.3] "-" MHU

BO_ 323 ADAS_APA_SLOT2INFO3: 8 ADAS_Info
  SG_ APA_ParkingSlotType2 : 9|2@0+ (1,0) [0|3] "-" MHU
  SG_ APA_slot_2 : 39|8@0+ (1,0) [0|255] "-" MHU
  SG_ SECCAN_APA_Slot2Info : 63|8@0+ (1,0) [0|255] "" MHU

BO_ 324 ADAS_APA_SLOT3INFO1: 8 ADAS_Info
  SG_ APA_slot_ID_3_P0_X : 7|14@0+ (0.01,-80) [-80|83.3] "-" MHU
  SG_ APA_slot_ID_3_P0_Y : 23|14@0+ (0.01,-80) [-80|83.3] "-" MHU
  SG_ APA_slot_ID_3_P1_X : 39|14@0+ (0.01,-80) [-80|83.3] "-" MHU
  SG_ APA_slot_ID_3_P1_Y : 55|14@0+ (0.01,-80) [-80|83.3] "-" MHU

BO_ 325 ADAS_APA_SLOT3INFO2: 8 ADAS_Info
  SG_ APA_slot_ID_3_P2_X : 7|14@0+ (0.01,-80) [-80|83.3] "-" MHU
  SG_ APA_slot_ID_3_P2_Y : 23|14@0+ (0.01,-80) [-80|83.3] "-" MHU
  SG_ APA_slot_ID_3_P3_X : 39|14@0+ (0.01,-80) [-80|83.3] "-" MHU
  SG_ APA_slot_ID_3_P3_Y : 55|14@0+ (0.01,-80) [-80|83.3] "-" MHU

BO_ 326 ADAS_APA_SLOT3INFO3: 8 ADAS_Info
  SG_ APA_slot_3 : 39|8@0+ (1,0) [0|255] "-" MHU
  SG_ APA_ParkingSlotType3 : 52|2@0+ (1,0) [0|3] "-" MHU
  SG_ SECCAN_APA_Slot3Info : 63|8@0+ (1,0) [0|255] "" MHU

BO_ 327 ADAS_APA_SLOT4INFO1: 8 ADAS_Info
  SG_ APA_slot_ID_4_P0_X : 7|14@0+ (0.01,-80) [-80|83.3] "-" MHU
  SG_ APA_slot_ID_4_P0_Y : 23|14@0+ (0.01,-80) [-80|83.3] "-" MHU
  SG_ APA_slot_ID_4_P1_X : 39|14@0+ (0.01,-80) [-80|83.3] "-" MHU
  SG_ APA_slot_ID_4_P1_Y : 55|14@0+ (0.01,-80) [-80|83.3] "-" MHU

BO_ 328 ADAS_APA_SLOT4INFO2: 8 ADAS_Info
  SG_ APA_slot_ID_4_P2_X : 7|14@0+ (0.01,-80) [-80|83.3] "-" MHU
  SG_ APA_slot_ID_4_P2_Y : 23|14@0+ (0.01,-80) [-80|83.3] "-" MHU
  SG_ APA_slot_ID_4_P3_X : 39|14@0+ (0.01,-80) [-80|83.3] "-" MHU
  SG_ APA_slot_ID_4_P3_Y : 55|14@0+ (0.01,-80) [-80|83.3] "-" MHU

BO_ 329 ADAS_APA_SLOT4INFO3: 8 ADAS_Info
  SG_ APA_ParkingSlotType4 : 9|2@0+ (1,0) [0|3] "-" MHU
  SG_ APA_slot_4 : 39|8@0+ (1,0) [0|255] "-" MHU
  SG_ SECCAN_APA_Slot4Info : 63|8@0+ (1,0) [0|255] "" MHU

BO_ 330 ADAS_APA_SLOT5INFO1: 8 ADAS_Info
  SG_ APA_slot_ID_5_P0_X : 7|14@0+ (0.01,-80) [-80|83.3] "-" MHU
  SG_ APA_slot_ID_5_P0_Y : 23|14@0+ (0.01,-80) [-80|83.3] "-" MHU
  SG_ APA_slot_ID_5_P1_X : 39|14@0+ (0.01,-80) [-80|83.3] "-" MHU
  SG_ APA_slot_ID_5_P1_Y : 55|14@0+ (0.01,-80) [-80|83.3] "-" MHU

BO_ 331 ADAS_APA_SLOT5INFO2: 8 ADAS_Info
  SG_ APA_slot_ID_5_P2_X : 7|14@0+ (0.01,-80) [-80|83.3] "-" MHU
  SG_ APA_slot_ID_5_P2_Y : 23|14@0+ (0.01,-80) [-80|83.3] "-" MHU
  SG_ APA_slot_ID_5_P3_X : 39|14@0+ (0.01,-80) [-80|83.3] "-" MHU
  SG_ APA_slot_ID_5_P3_Y : 55|14@0+ (0.01,-80) [-80|83.3] "-" MHU

BO_ 332 ADAS_APA_SLOT5INFO3: 8 ADAS_Info
  SG_ APA_ParkingSlotType5 : 9|2@0+ (1,0) [0|3] "-" MHU
  SG_ APA_slot_5 : 39|8@0+ (1,0) [0|255] "-" MHU
  SG_ SECCAN_APA_Slot5Info : 63|8@0+ (1,0) [0|255] "" MHU

BO_ 333 ADAS_APA_SLOT6INFO1: 8 ADAS_Info
  SG_ APA_slot_ID_6_P0_X : 7|14@0+ (0.01,-80) [-80|83.3] "-" MHU
  SG_ APA_slot_ID_6_P0_Y : 23|14@0+ (0.01,-80) [-80|83.3] "-" MHU
  SG_ APA_slot_ID_6_P1_X : 39|14@0+ (0.01,-80) [-80|83.3] "-" MHU
  SG_ APA_slot_ID_6_P1_Y : 55|14@0+ (0.01,-80) [-80|83.3] "-" MHU

BO_ 334 ADAS_APA_SLOT6INFO2: 8 ADAS_Info
  SG_ APA_slot_ID_6_P2_X : 7|14@0+ (0.01,-80) [-80|83.3] "-" MHU
  SG_ APA_slot_ID_6_P2_Y : 23|14@0+ (0.01,-80) [-80|83.3] "-" MHU
  SG_ APA_slot_ID_6_P3_X : 39|14@0+ (0.01,-80) [-80|83.3] "-" MHU
  SG_ APA_slot_ID_6_P3_Y : 55|14@0+ (0.01,-80) [-80|83.3] "-" MHU

BO_ 335 ADAS_APA_SLOT6INFO3: 8 ADAS_Info
  SG_ APA_ParkingSlotType6 : 9|2@0+ (1,0) [0|3] "-" MHU
  SG_ APA_slot_6 : 39|8@0+ (1,0) [0|255] "-" MHU
  SG_ SECCAN_APA_Slot6Info : 63|8@0+ (1,0) [0|255] "" MHU

BO_ 357 VCU_ChargingConnection: 8 XGW_Info
  SG_ CHSKM_VCU_ChargingConnection : 7|8@0+ (1,0) [0|255] "" MHU
  SG_ ALV_VCU_ChargingConnection : 11|4@0+ (1,0) [0|14] "" MHU
  SG_ VCU_AcChgGunIn : 12|1@0+ (1,0) [0|1] "-" MHU
  SG_ VCU_DCChgGunIn : 13|1@0+ (1,0) [0|1] "-" MHU
  SG_ VCU_CPValue : 38|7@0+ (1,0) [0|100] "%" MHU
  SG_ VCU_ACChargingVoltage : 43|8@0+ (1,0) [0|255] "V" MHU
  SG_ VCU_MinCurrentOfACCharging : 47|3@0+ (1,0) [0|7] "A" MHU
  SG_ VCU_MaxCurrentOfACCharging : 48|6@0+ (1,0) [0|63] "A" MHU

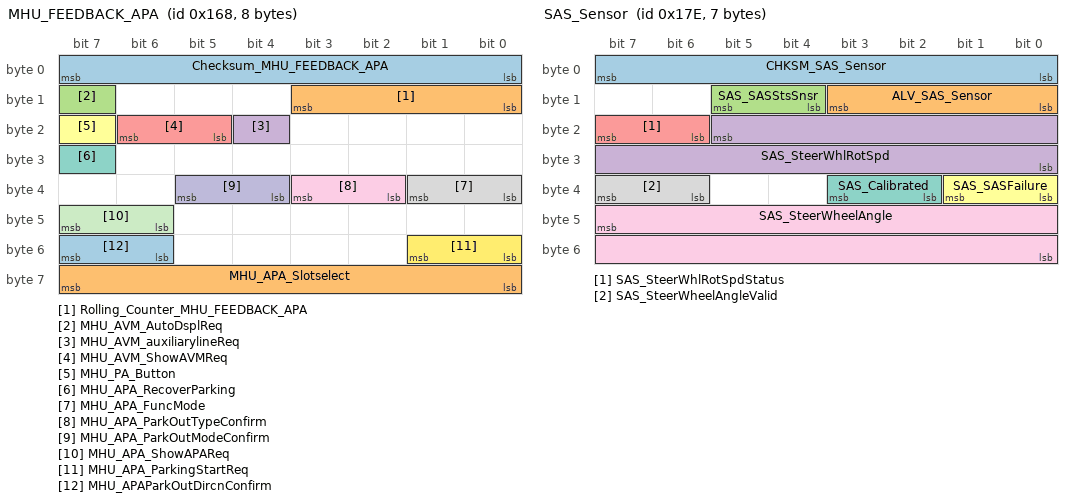
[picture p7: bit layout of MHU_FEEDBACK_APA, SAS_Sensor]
BO_ 360 MHU_FEEDBACK_APA: 8 MHU
  SG_ Checksum_MHU_FEEDBACK_APA : 7|8@0+ (1,0) [0|255] "" ADAS_Info
  SG_ Rolling_Counter_MHU_FEEDBACK_APA : 11|4@0+ (1,0) [0|14] "" ADAS_Info
  SG_ MHU_AVM_AutoDsplReq : 15|1@0+ (1,0) [0|1] "" ADAS_Info
  SG_ MHU_AVM_auxiliarylineReq : 20|1@0+ (1,0) [0|1] "-" ADAS_Info
  SG_ MHU_AVM_ShowAVMReq : 22|2@0+ (1,0) [0|3] "-" ADAS_Info
  SG_ MHU_PA_Button : 23|1@0+ (1,0) [0|1] "-" ADAS_Info
  SG_ MHU_APA_RecoverParking : 31|1@0+ (1,0) [0|1] "-" ADAS_Info
  SG_ MHU_APA_FuncMode : 33|2@0+ (1,0) [0|3] "-" ADAS_Info
  SG_ MHU_APA_ParkOutTypeConfirm : 35|2@0+ (1,0) [0|3] "-" ADAS_Info
  SG_ MHU_APA_ParkOutModeConfirm : 37|2@0+ (1,0) [0|3] "-" ADAS_Info
  SG_ MHU_APA_ShowAPAReq : 47|2@0+ (1,0) [0|3] "-" ADAS_Info
  SG_ MHU_APA_ParkingStartReq : 49|2@0+ (1,0) [0|3] "-" ADAS_Info
  SG_ MHU_APAParkOutDircnConfirm : 55|2@0+ (1,0) [0|3] "-" ADAS_Info
  SG_ MHU_APA_Slotselect : 63|8@0+ (1,0) [0|255] "-" ADAS_Info

BO_ 372 BMS_CurMeas: 8 XGW_Info
  SG_ CHSKM_BMS_CurMeas : 7|8@0+ (1,0) [0|255] "" MHU
  SG_ ALV_BMS_CurMeas : 11|4@0+ (1,0) [0|14] "" MHU
  SG_ BMS_PackCur_MEAS : 23|16@0+ (0.1,-3276.8) [-3276.8|3276.7] "A" MHU

BO_ 374 BMS_HVMeas1: 8 XGW_Info
  SG_ Checksum_0x176 : 7|8@0+ (1,0) [0|255] "" MHU
  SG_ Rolling_Counter_0x176 : 11|4@0+ (1,0) [0|14] "" MHU
  SG_ BMS_HVPackVol_MEAS : 23|16@0+ (0.1,0) [0|800] "V" MHU
  SG_ BMS_HVLinkVol_MEAS : 39|16@0+ (0.1,0) [0|800] "V" MHU

BO_ 376 YSS_LongAcc: 8 XGW_Info
  SG_ CHKSM_YSS_LongAcc : 7|8@0+ (1,0) [0|255] "" MHU
  SG_ ALV_YSS_LongAcc : 11|4@0+ (1,0) [0|14] "" MHU
  SG_ YSS_LONG_ACCUNFILTERED_QUAL : 15|4@0+ (1,0) [0|15] "" MHU
  SG_ YSS_LONG_ACC_UNFILTERED : 23|16@0+ (0.002,-65.532) [-65.532|65.532] "m/s2" MHU
  SG_ YSS_LONG_ACC_QUAL : 35|4@0+ (1,0) [0|15] "" MHU
  SG_ YSS_LONG_ACC : 47|16@0+ (0.002,-65.532) [-65.532|65.532] "m/s2" MHU

BO_ 377 YSS_LateralAcc: 8 XGW_Info
  SG_ CHKSM_YSS_LateralAcc : 7|8@0+ (1,0) [0|255] "" MHU
  SG_ ALV_YSS_LateralAcc : 11|4@0+ (1,0) [0|14] "" MHU
  SG_ YSS_LAT_ACCUNFILTERED_QUAL : 15|4@0+ (1,0) [0|15] "" MHU
  SG_ YSS_LAT_ACC_UNFILTERED : 23|16@0+ (0.002,-65.532) [-65.532|65.532] "m/s2" MHU
  SG_ YSS_LAT_ACC_QUAL : 35|4@0+ (1,0) [0|15] "" MHU
  SG_ YSS_LAT_ACC : 47|16@0+ (0.002,-65.532) [-65.532|65.532] "m/s2" MHU

BO_ 382 SAS_Sensor: 7 XGW_Info
  SG_ CHKSM_SAS_Sensor : 7|8@0+ (1,0) [0|255] "" HUD,MHU
  SG_ ALV_SAS_Sensor : 11|4@0+ (1,0) [0|14] "" HUD,MHU
  SG_ SAS_SASStsSnsr : 13|2@0+ (1,0) [0|1] "-" HUD,MHU
  SG_ SAS_SteerWhlRotSpd : 21|14@0+ (0.125,-1024) [-1024|1023.875] "degree/s" HUD,MHU
  SG_ SAS_SteerWhlRotSpdStatus : 23|2@0+ (1,0) [0|1] "" HUD,MHU
  SG_ SAS_SASFailure : 33|2@0+ (1,0) [0|1] "" HUD,MHU
  SG_ SAS_Calibrated : 35|2@0+ (1,0) [0|1] "" HUD,MHU
  SG_ SAS_SteerWheelAngleValid : 39|2@0+ (1,0) [0|1] "" HUD,MHU
  SG_ SAS_SteerWheelAngle : 47|16@0+ (0.0238,-780) [-780|779.7] "deg" HUD,MHU

BO_ 385 VCU_Debug: 8 XGW_Info
 SG_ VCU_Debug1 : 7|8@0+ (1,0) [0|255] ""  MHU
 SG_ VCU_Debug2 : 15|8@0+ (1,0) [0|255] ""  MHU
 SG_ VCU_Debug3 : 23|8@0+ (1,0) [0|255] ""  MHU
 SG_ VCU_Debug4 : 27|5@0+ (1,0) [0|31] ""  MHU

BO_ 386 VCU_FS_A: 8 XGW_Info
  SG_ VCU_FS_A_1 : 0|1@0+ (1,0) [0|1] "" MHU
  SG_ VCU_FS_A_2 : 1|1@0+ (1,0) [0|1] "" MHU
  SG_ VCU_FS_A_3 : 2|1@0+ (1,0) [0|1] "" MHU
  SG_ VCU_FS_A_4 : 3|1@0+ (1,0) [0|1] "" MHU
  SG_ VCU_FS_A_5 : 4|1@0+ (1,0) [0|1] "" MHU
  SG_ VCU_FS_A_6 : 5|1@0+ (1,0) [0|1] "" MHU
  SG_ VCU_FS_A_7 : 6|1@0+ (1,0) [0|1] "" MHU
  SG_ VCU_FS_A_8 : 7|1@0+ (1,0) [0|1] "" MHU
  SG_ VCU_FS_A_9 : 8|1@0+ (1,0) [0|1] "" MHU
  SG_ VCU_FS_A_10 : 9|1@0+ (1,0) [0|1] "" MHU
  SG_ VCU_FS_A_11 : 10|1@0+ (1,0) [0|1] "" MHU
  SG_ VCU_FS_A_12 : 11|1@0+ (1,0) [0|1] "" MHU
  SG_ VCU_FS_A_13 : 12|1@0+ (1,0) [0|1] "" MHU
  SG_ VCU_FS_A_14 : 13|1@0+ (1,0) [0|1] "" MHU
  SG_ VCU_FS_A_15 : 14|1@0+ (1,0) [0|1] "" MHU
  SG_ VCU_FS_A_16 : 15|1@0+ (1,0) [0|1] "" MHU
  SG_ VCU_FS_A_17 : 16|1@0+ (1,0) [0|1] "" MHU
  SG_ VCU_FS_A_18 : 17|1@0+ (1,0) [0|1] "" MHU
  SG_ VCU_FS_A_19 : 18|1@0+ (1,0) [0|1] "" MHU
  SG_ VCU_FS_A_20 : 19|1@0+ (1,0) [0|1] "" MHU
  SG_ VCU_FS_A_21 : 20|1@0+ (1,0) [0|1] "" MHU
  SG_ VCU_FS_A_22 : 21|1@0+ (1,0) [0|1] "" MHU
  SG_ VCU_FS_A_23 : 22|1@0+ (1,0) [0|1] "" MHU
  SG_ VCU_FS_A_24 : 23|1@0+ (1,0) [0|1] "" MHU
  SG_ VCU_FS_A_25 : 24|1@0+ (1,0) [0|1] "" MHU
  SG_ VCU_FS_A_26 : 25|1@0+ (1,0) [0|1] "" MHU
  SG_ VCU_FS_A_27 : 26|1@0+ (1,0) [0|1] "" MHU
  SG_ VCU_FS_A_28 : 27|1@0+ (1,0) [0|1] "" MHU
  SG_ VCU_FS_A_29 : 28|1@0+ (1,0) [0|1] "" MHU
  SG_ VCU_FS_A_30 : 29|1@0+ (1,0) [0|1] "" MHU
  SG_ VCU_FS_A_31 : 30|1@0+ (1,0) [0|1] "" MHU
  SG_ VCU_FS_A_32 : 31|1@0+ (1,0) [0|1] "" MHU
  SG_ VCU_FS_A_33 : 32|1@0+ (1,0) [0|1] "" MHU
  SG_ VCU_FS_A_34 : 33|1@0+ (1,0) [0|1] "" MHU
  SG_ VCU_FS_A_35 : 34|1@0+ (1,0) [0|1] "" MHU
  SG_ VCU_FS_A_36 : 35|1@0+ (1,0) [0|1] "" MHU
  SG_ VCU_FS_A_37 : 36|1@0+ (1,0) [0|1] "" MHU
  SG_ VCU_FS_A_38 : 37|1@0+ (1,0) [0|1] "" MHU
  SG_ VCU_FS_A_39 : 38|1@0+ (1,0) [0|1] "" MHU
  SG_ VCU_FS_A_40 : 39|1@0+ (1,0) [0|1] "" MHU
  SG_ VCU_FS_A_41 : 40|1@0+ (1,0) [0|1] "" MHU
  SG_ VCU_FS_A_42 : 41|1@0+ (1,0) [0|1] "" MHU
  SG_ VCU_FS_A_43 : 42|1@0+ (1,0) [0|1] "" MHU
  SG_ VCU_FS_A_44 : 43|1@0+ (1,0) [0|1] "" MHU
  SG_ VCU_FS_A_45 : 44|1@0+ (1,0) [0|1] "" MHU
  SG_ VCU_FS_A_46 : 45|1@0+ (1,0) [0|1] "" MHU
  SG_ VCU_FS_A_47 : 46|1@0+ (1,0) [0|1] "" MHU
  SG_ VCU_FS_A_48 : 47|1@0+ (1,0) [0|1] "" MHU
  SG_ VCU_FS_A_49 : 48|1@0+ (1,0) [0|1] "" MHU
  SG_ VCU_FS_A_50 : 49|1@0+ (1,0) [0|1] "" MHU
  SG_ VCU_FS_A_51 : 50|1@0+ (1,0) [0|1] "" MHU
  SG_ VCU_FS_A_52 : 51|1@0+ (1,0) [0|1] "" MHU
  SG_ VCU_FS_A_53 : 52|1@0+ (1,0) [0|1] "" MHU
  SG_ VCU_FS_A_54 : 53|1@0+ (1,0) [0|1] "" MHU
  SG_ VCU_FS_A_55 : 54|1@0+ (1,0) [0|1] "" MHU
  SG_ VCU_FS_A_56 : 55|1@0+ (1,0) [0|1] "" MHU
  SG_ VCU_FS_A_57 : 56|1@0+ (1,0) [0|1] "" MHU
  SG_ VCU_FS_A_58 : 57|1@0+ (1,0) [0|1] "" MHU
  SG_ VCU_FS_A_59 : 58|1@0+ (1,0) [0|1] "" MHU
  SG_ VCU_FS_A_60 : 59|1@0+ (1,0) [0|1] "" MHU
  SG_ VCU_FS_A_61 : 60|1@0+ (1,0) [0|1] "" MHU
  SG_ VCU_FS_A_62 : 61|1@0+ (1,0) [0|1] "" MHU
  SG_ VCU_FS_A_63 : 62|1@0+ (1,0) [0|1] "" MHU
  SG_ VCU_FS_A_64 : 63|1@0+ (1,0) [0|1] "" MHU

BO_ 387 VCU_FS_B: 8 XGW_Info
  SG_ VCU_FS_B_1 : 0|1@0+ (1,0) [0|1] "" MHU
  SG_ VCU_FS_B_2 : 1|1@0+ (1,0) [0|1] "" MHU
  SG_ VCU_FS_B_3 : 2|1@0+ (1,0) [0|1] "" MHU
  SG_ VCU_FS_B_4 : 3|1@0+ (1,0) [0|1] "" MHU
  SG_ VCU_FS_B_5 : 4|1@0+ (1,0) [0|1] "" MHU
  SG_ VCU_FS_B_6 : 5|1@0+ (1,0) [0|1] "" MHU
  SG_ VCU_FS_B_7 : 6|1@0+ (1,0) [0|1] "" MHU
  SG_ VCU_FS_B_8 : 7|1@0+ (1,0) [0|1] "" MHU
  SG_ VCU_FS_B_9 : 8|1@0+ (1,0) [0|1] "" MHU
  SG_ VCU_FS_B_10 : 9|1@0+ (1,0) [0|1] "" MHU
  SG_ VCU_FS_B_11 : 10|1@0+ (1,0) [0|1] "" MHU
  SG_ VCU_FS_B_12 : 11|1@0+ (1,0) [0|1] "" MHU
  SG_ VCU_FS_B_13 : 12|1@0+ (1,0) [0|1] "" MHU
  SG_ VCU_FS_B_14 : 13|1@0+ (1,0) [0|1] "" MHU
  SG_ VCU_FS_B_15 : 14|1@0+ (1,0) [0|1] "" MHU
  SG_ VCU_FS_B_16 : 15|1@0+ (1,0) [0|1] "" MHU
  SG_ VCU_FS_B_17 : 16|1@0+ (1,0) [0|1] "" MHU
  SG_ VCU_FS_B_18 : 17|1@0+ (1,0) [0|1] "" MHU
  SG_ VCU_FS_B_19 : 18|1@0+ (1,0) [0|1] "" MHU
  SG_ VCU_FS_B_20 : 19|1@0+ (1,0) [0|1] "" MHU
  SG_ VCU_FS_B_21 : 20|1@0+ (1,0) [0|1] "" MHU
  SG_ VCU_FS_B_22 : 21|1@0+ (1,0) [0|1] "" MHU
  SG_ VCU_FS_B_23 : 22|1@0+ (1,0) [0|1] "" MHU
  SG_ VCU_FS_B_24 : 23|1@0+ (1,0) [0|1] "" MHU
  SG_ VCU_FS_B_25 : 24|1@0+ (1,0) [0|1] "" MHU
  SG_ VCU_FS_B_26 : 25|1@0+ (1,0) [0|1] "" MHU
  SG_ VCU_FS_B_27 : 26|1@0+ (1,0) [0|1] "" MHU
  SG_ VCU_FS_B_28 : 27|1@0+ (1,0) [0|1] "" MHU
  SG_ VCU_FS_B_29 : 28|1@0+ (1,0) [0|1] "" MHU
  SG_ VCU_FS_B_30 : 29|1@0+ (1,0) [0|1] "" MHU
  SG_ VCU_FS_B_31 : 30|1@0+ (1,0) [0|1] "" MHU
  SG_ VCU_FS_B_32 : 31|1@0+ (1,0) [0|1] "" MHU
  SG_ VCU_FS_B_33 : 32|1@0+ (1,0) [0|1] "" MHU
  SG_ VCU_FS_B_34 : 33|1@0+ (1,0) [0|1] "" MHU
  SG_ VCU_FS_B_35 : 34|1@0+ (1,0) [0|1] "" MHU
  SG_ VCU_FS_B_36 : 35|1@0+ (1,0) [0|1] "" MHU
  SG_ VCU_FS_B_37 : 36|1@0+ (1,0) [0|1] "" MHU
  SG_ VCU_FS_B_38 : 37|1@0+ (1,0) [0|1] "" MHU
  SG_ VCU_FS_B_39 : 38|1@0+ (1,0) [0|1] "" MHU
  SG_ VCU_FS_B_40 : 39|1@0+ (1,0) [0|1] "" MHU
  SG_ VCU_FS_B_41 : 40|1@0+ (1,0) [0|1] "" MHU
  SG_ VCU_FS_B_42 : 41|1@0+ (1,0) [0|1] "" MHU
  SG_ VCU_FS_B_43 : 42|1@0+ (1,0) [0|1] "" MHU
  SG_ VCU_FS_B_44 : 43|1@0+ (1,0) [0|1] "" MHU
  SG_ VCU_FS_B_45 : 44|1@0+ (1,0) [0|1] "" MHU
  SG_ VCU_FS_B_46 : 45|1@0+ (1,0) [0|1] "" MHU
  SG_ VCU_FS_B_47 : 46|1@0+ (1,0) [0|1] "" MHU
  SG_ VCU_FS_B_48 : 47|1@0+ (1,0) [0|1] "" MHU
  SG_ VCU_FS_B_49 : 48|1@0+ (1,0) [0|1] "" MHU
  SG_ VCU_FS_B_50 : 49|1@0+ (1,0) [0|1] "" MHU
  SG_ VCU_FS_B_51 : 50|1@0+ (1,0) [0|1] "" MHU
  SG_ VCU_FS_B_52 : 51|1@0+ (1,0) [0|1] "" MHU
  SG_ VCU_FS_B_53 : 52|1@0+ (1,0) [0|1] "" MHU
  SG_ VCU_FS_B_54 : 53|1@0+ (1,0) [0|1] "" MHU
  SG_ VCU_FS_B_55 : 54|1@0+ (1,0) [0|1] "" MHU
  SG_ VCU_FS_B_56 : 55|1@0+ (1,0) [0|1] "" MHU
  SG_ VCU_FS_B_57 : 56|1@0+ (1,0) [0|1] "" MHU
  SG_ VCU_FS_B_58 : 57|1@0+ (1,0) [0|1] "" MHU
  SG_ VCU_FS_B_59 : 58|1@0+ (1,0) [0|1] "" MHU
  SG_ VCU_FS_B_60 : 59|1@0+ (1,0) [0|1] "" MHU
  SG_ VCU_FS_B_61 : 60|1@0+ (1,0) [0|1] "" MHU
  SG_ VCU_FS_B_62 : 61|1@0+ (1,0) [0|1] "" MHU
  SG_ VCU_FS_B_63 : 62|1@0+ (1,0) [0|1] "" MHU
  SG_ VCU_FS_B_64 : 63|1@0+ (1,0) [0|1] "" MHU

BO_ 389 VCU_FS_C: 8 XGW_Info
 SG_ VCU_FS_C_1 : 0|1@0+ (1,0) [0|1] ""  MHU
 SG_ VCU_FS_C_2 : 1|1@0+ (1,0) [0|1] ""  MHU
 SG_ VCU_FS_C_3 : 2|1@0+ (1,0) [0|1] ""  MHU
 SG_ VCU_FS_C_4 : 3|1@0+ (1,0) [0|1] ""  MHU
 SG_ VCU_FS_C_5 : 4|1@0+ (1,0) [0|1] ""  MHU
 SG_ VCU_FS_C_6 : 5|1@0+ (1,0) [0|1] ""  MHU
 SG_ VCU_FS_C_7 : 6|1@0+ (1,0) [0|1] ""  MHU
 SG_ VCU_FS_C_8 : 7|1@0+ (1,0) [0|1] ""  MHU
 SG_ VCU_FS_C_9 : 8|1@0+ (1,0) [0|1] ""  MHU
 SG_ VCU_FS_C_10 : 9|1@0+ (1,0) [0|1] ""  MHU
 SG_ VCU_FS_C_11 : 10|1@0+ (1,0) [0|1] ""  MHU
 SG_ VCU_FS_C_12 : 11|1@0+ (1,0) [0|1] ""  MHU
 SG_ VCU_FS_C_13 : 12|1@0+ (1,0) [0|1] ""  MHU
 SG_ VCU_FS_C_14 : 13|1@0+ (1,0) [0|1] ""  MHU
 SG_ VCU_FS_C_15 : 14|1@0+ (1,0) [0|1] ""  MHU
 SG_ VCU_FS_C_16 : 15|1@0+ (1,0) [0|1] ""  MHU
 SG_ VCU_FS_C_17 : 16|1@0+ (1,0) [0|1] ""  MHU
 SG_ VCU_FS_C_18 : 17|1@0+ (1,0) [0|1] ""  MHU
 SG_ VCU_FS_C_19 : 18|1@0+ (1,0) [0|1] ""  MHU
 SG_ VCU_FS_C_20 : 19|1@0+ (1,0) [0|1] ""  MHU
 SG_ VCU_FS_C_21 : 20|1@0+ (1,0) [0|1] ""  MHU
 SG_ VCU_FS_C_22 : 21|1@0+ (1,0) [0|1] ""  MHU
 SG_ VCU_FS_C_23 : 22|1@0+ (1,0) [0|1] ""  MHU
 SG_ VCU_FS_C_24 : 23|1@0+ (1,0) [0|1] ""  MHU
 SG_ VCU_FS_C_25 : 24|1@0+ (1,0) [0|1] ""  MHU
 SG_ VCU_FS_C_26 : 25|1@0+ (1,0) [0|1] ""  MHU
 SG_ VCU_FS_C_27 : 26|1@0+ (1,0) [0|1] ""  MHU
 SG_ VCU_FS_C_28 : 27|1@0+ (1,0) [0|1] ""  MHU
 SG_ VCU_FS_C_29 : 28|1@0+ (1,0) [0|1] ""  MHU
 SG_ VCU_FS_C_30 : 29|1@0+ (1,0) [0|1] ""  MHU
 SG_ VCU_FS_C_31 : 30|1@0+ (1,0) [0|1] ""  MHU
 SG_ VCU_FS_C_32 : 31|1@0+ (1,0) [0|1] ""  MHU
 SG_ VCU_FS_C_33 : 32|1@0+ (1,0) [0|1] ""  MHU
 SG_ VCU_FS_C_34 : 33|1@0+ (1,0) [0|1] ""  MHU
 SG_ VCU_FS_C_35 : 34|1@0+ (1,0) [0|1] ""  MHU
 SG_ VCU_FS_C_36 : 35|1@0+ (1,0) [0|1] ""  MHU
 SG_ VCU_FS_C_37 : 36|1@0+ (1,0) [0|1] ""  MHU
 SG_ VCU_FS_C_38 : 37|1@0+ (1,0) [0|1] ""  MHU
 SG_ VCU_FS_C_39 : 38|1@0+ (1,0) [0|1] ""  MHU
 SG_ VCU_FS_C_40 : 39|1@0+ (1,0) [0|1] ""  MHU
 SG_ VCU_FS_C_41 : 40|1@0+ (1,0) [0|1] ""  MHU
 SG_ VCU_FS_C_42 : 41|1@0+ (1,0) [0|1] ""  MHU
 SG_ VCU_FS_C_43 : 42|1@0+ (1,0) [0|1] ""  MHU
 SG_ VCU_FS_C_44 : 43|1@0+ (1,0) [0|1] ""  MHU
 SG_ VCU_FS_C_45 : 44|1@0+ (1,0) [0|1] ""  MHU
 SG_ VCU_FS_C_46 : 45|1@0+ (1,0) [0|1] ""  MHU
 SG_ VCU_FS_C_47 : 46|1@0+ (1,0) [0|1] ""  MHU
 SG_ VCU_FS_C_48 : 47|1@0+ (1,0) [0|1] ""  MHU
 SG_ VCU_FS_C_49 : 48|1@0+ (1,0) [0|1] ""  MHU
 SG_ VCU_FS_C_50 : 49|1@0+ (1,0) [0|1] ""  MHU
 SG_ VCU_FS_C_51 : 50|1@0+ (1,0) [0|1] ""  MHU
 SG_ VCU_FS_C_52 : 51|1@0+ (1,0) [0|1] ""  MHU
 SG_ VCU_FS_C_53 : 52|1@0+ (1,0) [0|1] ""  MHU
 SG_ VCU_FS_C_54 : 53|1@0+ (1,0) [0|1] ""  MHU
 SG_ VCU_FS_C_55 : 54|1@0+ (1,0) [0|1] ""  MHU
 SG_ VCU_FS_C_56 : 55|1@0+ (1,0) [0|1] ""  MHU
 SG_ VCU_FS_C_57 : 56|1@0+ (1,0) [0|1] ""  MHU
 SG_ VCU_FS_C_58 : 57|1@0+ (1,0) [0|1] ""  MHU
 SG_ VCU_FS_C_59 : 58|1@0+ (1,0) [0|1] ""  MHU
 SG_ VCU_FS_C_60 : 59|1@0+ (1,0) [0|1] ""  MHU
 SG_ VCU_FS_C_61 : 60|1@0+ (1,0) [0|1] ""  MHU
 SG_ VCU_FS_C_62 : 61|1@0+ (1,0) [0|1] ""  MHU
 SG_ VCU_FS_C_63 : 62|1@0+ (1,0) [0|1] ""  MHU
 SG_ VCU_FS_C_64 : 63|1@0+ (1,0) [0|1] ""  MHU

BO_ 409 VCU_Sts1: 8 XGW_Info
  SG_ CHSKM_VCU_Sts1 : 7|8@0+ (1,0) [0|255] "" MHU
  SG_ ALV_VCU_Sts1 : 11|4@0+ (1,0) [0|14] "" MHU
  SG_ VCU_BMS_HVOnOff_REQ : 19|2@0+ (1,0) [0|1] "" MHU

BO_ 417 IDB_V_VEH: 5 XGW_Info
  SG_ CHSKM_V_VEH : 7|8@0+ (1,0) [0|255] "" MHU
  SG_ ALIV_V_VEH : 11|4@0+ (1,0) [0|14] "" MHU
  SG_ V_VEH_COG : 23|16@0+ (0.015625,0) [0|350] "km/h" MHU
  SG_ DVCO_VEH : 35|3@0+ (1,0) [0|7] "" MHU
  SG_ QU_V_VEH_COG : 39|4@0+ (1,0) [0|15] "" MHU

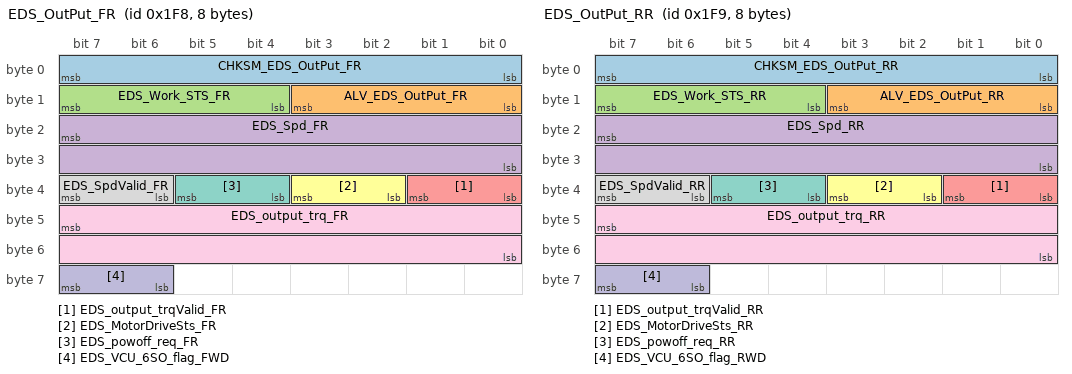
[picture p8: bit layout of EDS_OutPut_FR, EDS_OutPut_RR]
BO_ 504 EDS_OutPut_FR: 8 XGW_Info
  SG_ CHKSM_EDS_OutPut_FR : 7|8@0+ (1,0) [0|255] "" ADAS_Info,AMP,CPD,EASC,HUD,MHU
  SG_ ALV_EDS_OutPut_FR : 11|4@0+ (1,0) [0|14] "" ADAS_Info,AMP,CPD,EASC,HUD,MHU
  SG_ EDS_Work_STS_FR : 15|4@0+ (1,0) [0|15] "-" ADAS_Info,AMP,CPD,EASC,HUD,MHU
  SG_ EDS_Spd_FR : 23|16@0+ (1,-20000) [-20000|20000] "rpm" ADAS_Info,AMP,CPD,EASC,HUD,MHU
  SG_ EDS_output_trqValid_FR : 33|2@0+ (1,0) [0|1] "" ADAS_Info,AMP,CPD,EASC,HUD,MHU
  SG_ EDS_MotorDriveSts_FR : 35|2@0+ (1,0) [0|3] "" ADAS_Info,AMP,CPD,EASC,HUD,MHU
  SG_ EDS_powoff_req_FR : 37|2@0+ (1,0) [0|1] "" ADAS_Info,AMP,CPD,EASC,HUD,MHU
  SG_ EDS_SpdValid_FR : 39|2@0+ (1,0) [0|1] "" ADAS_Info,AMP,CPD,EASC,HUD,MHU
  SG_ EDS_output_trq_FR : 47|16@0+ (1,-2000) [-2000|2000] "Nm" ADAS_Info,AMP,CPD,EASC,HUD,MHU
  SG_ EDS_VCU_6SO_flag_FWD : 63|2@0+ (1,0) [0|1] "" ADAS_Info,AMP,CPD,EASC,HUD,MHU

BO_ 505 EDS_OutPut_RR: 8 XGW_Info
  SG_ CHKSM_EDS_OutPut_RR : 7|8@0+ (1,0) [0|255] "" ADAS_Info,AMP,CPD,EASC,HUD,MHU
  SG_ ALV_EDS_OutPut_RR : 11|4@0+ (1,0) [0|14] "" ADAS_Info,AMP,CPD,EASC,HUD,MHU
  SG_ EDS_Work_STS_RR : 15|4@0+ (1,0) [0|15] "-" ADAS_Info,AMP,CPD,EASC,HUD,MHU
  SG_ EDS_Spd_RR : 23|16@0+ (1,-20000) [-20000|20000] "rpm" ADAS_Info,AMP,CPD,EASC,HUD,MHU
  SG_ EDS_output_trqValid_RR : 33|2@0+ (1,0) [0|1] "" ADAS_Info,AMP,CPD,EASC,HUD,MHU
  SG_ EDS_MotorDriveSts_RR : 35|2@0+ (1,0) [0|3] "" ADAS_Info,AMP,CPD,EASC,HUD,MHU
  SG_ EDS_powoff_req_RR : 37|2@0+ (1,0) [0|1] "" ADAS_Info,AMP,CPD,EASC,HUD,MHU
  SG_ EDS_SpdValid_RR : 39|2@0+ (1,0) [0|1] "" ADAS_Info,AMP,CPD,EASC,HUD,MHU
  SG_ EDS_output_trq_RR : 47|16@0+ (1,-2000) [-2000|2000] "Nm" ADAS_Info,AMP,CPD,EASC,HUD,MHU
  SG_ EDS_VCU_6SO_flag_RWD : 63|2@0+ (1,0) [0|1] "-" ADAS_Info,AMP,CPD,EASC,HUD,MHU

BO_ 506 MHU_DRIVER_INFO: 8 MHU
  SG_ MHU_TouchEvtTyp : 7|3@0+ (1,0) [0|7] "-" ADAS_Info
  SG_ SECCAN_Drvr_Info : 15|8@0+ (1,0) [0|255] "" ADAS_Info
  SG_ MHU_XGestureSpd : 23|8@0+ (1,0) [0|255] "-" ADAS_Info
  SG_ MHU_YGestureSpd : 31|8@0+ (1,0) [0|255] "-" ADAS_Info
  SG_ MHU_Ycoordinate : 39|16@0+ (1,0) [0|65535] "-" ADAS_Info
  SG_ MHU_Xcoordinate : 55|16@0+ (1,0) [0|65535] "-" ADAS_Info

BO_ 515 Camera_rightlane: 8 ADAS_Info
  SG_ CHKSM_Camera_rightlane : 7|8@0+ (1,0) [0|255] "" MHU
  SG_ ALV_Camera_rightlane : 11|4@0+ (1,0) [0|14] "" MHU
  SG_ R1_LINE_TYPE : 43|2@0+ (1,0) [0|3] "-" MHU
  SG_ R0_LINE_TYPE : 47|2@0+ (1,0) [0|3] "-" MHU
  SG_ SECCAN_Camera_rightlane : 63|8@0+ (1,0) [0|255] "" MHU

BO_ 516 Camera_leftlane: 8 ADAS_Info
  SG_ CHKSM_Camera_leftlane : 7|8@0+ (1,0) [0|255] "" MHU
  SG_ ALV_Camera_leftlane : 11|4@0+ (1,0) [0|14] "" MHU
  SG_ L1_LINE_TYPE : 43|2@0+ (1,0) [0|3] "-" MHU
  SG_ L0_LINE_TYPE : 47|2@0+ (1,0) [0|3] "-" MHU
  SG_ SECCAN_Camera_leftlane : 63|8@0+ (1,0) [0|255] "" MHU

BO_ 517 BMS_VolMeas1: 8 XGW_Info
  SG_ Checksum_0x205 : 7|8@0+ (1,0) [0|255] "" MHU
  SG_ Rolling_Counter_0x205 : 11|4@0+ (1,0) [0|14] "" MHU
  SG_ BMS_CellNumMinCellVol : 23|8@0+ (1,0) [0|255] "" MHU
  SG_ BMS_CellNumMaxCellVol : 31|8@0+ (1,0) [0|255] "" MHU
  SG_ BMS_MinCellVol : 36|13@0+ (0.001,0) [0|6] "V" MHU
  SG_ BMS_MaxCellVol : 52|13@0+ (0.001,0) [0|6] "V" MHU

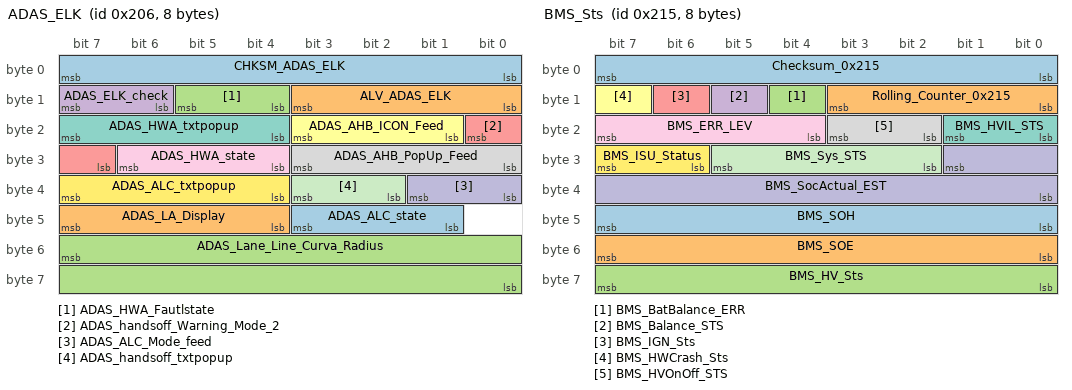
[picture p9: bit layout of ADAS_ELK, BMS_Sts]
BO_ 518 ADAS_ELK: 8 ADAS_Info
  SG_ CHKSM_ADAS_ELK : 7|8@0+ (1,0) [0|255] "" HUD,MHU
  SG_ ALV_ADAS_ELK : 11|4@0+ (1,0) [0|14] "" HUD,MHU
  SG_ ADAS_HWA_Fautlstate : 13|2@0+ (1,0) [0|3] "-" HUD,MHU
  SG_ ADAS_ELK_check : 15|2@0+ (1,0) [0|3] "-" HUD,MHU
  SG_ ADAS_handsoff_Warning_Mode_2 : 16|2@0+ (1,0) [0|3] "-" HUD,MHU
  SG_ ADAS_AHB_ICON_Feed : 19|3@0+ (1,0) [0|7] "-" HUD,MHU
  SG_ ADAS_HWA_txtpopup : 23|4@0+ (1,0) [0|15] "-" HUD,MHU
  SG_ ADAS_AHB_PopUp_Feed : 27|4@0+ (1,0) [0|15] "-" HUD,MHU
  SG_ ADAS_HWA_state : 30|3@0+ (1,0) [0|7] "-" HUD,MHU
  SG_ ADAS_ALC_Mode_feed : 33|2@0+ (1,0) [0|3] "-" HUD,MHU
  SG_ ADAS_handsoff_txtpopup : 35|2@0+ (1,0) [0|3] "-" HUD,MHU
  SG_ ADAS_ALC_txtpopup : 39|4@0+ (1,0) [0|15] "-" HUD,MHU
  SG_ ADAS_ALC_state : 43|3@0+ (1,0) [0|7] "-" HUD,MHU
  SG_ ADAS_LA_Display : 47|4@0+ (1,0) [0|15] "-" HUD,MHU
  SG_ ADAS_Lane_Line_Curva_Radius : 55|16@0- (1,0) [-32768|32767] "m" HUD,MHU

BO_ 519 BCM_SunroofSts: 8 XGW_Info
  SG_ SR_Undervoltage_Fault_Sts : 0|1@0+ (1,0) [0|1] "" MHU
  SG_ SR_Overvoltage_Fault_Sts : 1|1@0+ (1,0) [0|1] "" MHU
  SG_ SR_SLEEP_RQ : 2|1@0+ (1,0) [0|1] "-" MHU
  SG_ SR_Position : 5|3@0+ (1,0) [0|7] "" CPD,MHU
  SG_ SR_Motor_Running_Sts : 7|2@0+ (1,0) [0|3] "" MHU
  SG_ SR_MotorReverse_Fault_Sts : 8|1@0+ (1,0) [0|1] "" MHU
  SG_ SR_Hall_Fault_Sts : 9|1@0+ (1,0) [0|1] "" MHU
  SG_ SR_Normalisation_Sts : 10|1@0+ (1,0) [0|1] "" MHU
  SG_ SR_Relay_Fault : 11|1@0+ (1,0) [0|1] "" MHU
  SG_ SR_Commu_Fault_Sts : 12|1@0+ (1,0) [0|1] "" MHU
  SG_ SR_Initialisation_Status : 13|1@0+ (1,0) [0|1] "" MHU
  SG_ SR_Ctrl_Result : 15|2@0+ (1,0) [0|3] "" MHU
  SG_ SR_ThermalProtection_Fault_Sts : 16|1@0+ (1,0) [0|1] "-" MHU
  SG_ SR_Posit_Percentage : 23|7@0+ (1,0) [0|100] "%" CPD,MHU
  SG_ SR_Operation_Stat : 27|4@0+ (1,0) [0|8] "-" MHU
  SG_ SR_Error_RSP : 28|1@0+ (1,0) [0|1] "" MHU
  SG_ BCM_AutoSunroof_Sts : 30|2@0+ (1,0) [0|3] ""  MHU

BO_ 520 BCM_SunshadeSts: 8 XGW_Info
  SG_ SS_MotorReverse_Fault_Status : 0|1@0+ (1,0) [0|1] "" MHU
  SG_ SS_Motor_Running_Status : 2|2@0+ (1,0) [0|3] "" MHU
  SG_ SS_Position : 5|3@0+ (1,0) [0|7] "" MHU
  SG_ SS_SLEEP_RQ : 6|1@0+ (1,0) [0|1] "-" MHU
  SG_ SS_Undervoltage_Fault_Status : 7|1@0+ (1,0) [0|1] "" MHU
  SG_ SS_Ctrl_Result : 9|2@0+ (1,0) [0|3] "" MHU
  SG_ SS_Overvoltage_Fault_Status : 10|1@0+ (1,0) [0|1] "" MHU
  SG_ SS_Relay_Fault : 11|1@0+ (1,0) [0|1] "" MHU
  SG_ SS_Normalisation_Status : 12|1@0+ (1,0) [0|1] "" MHU
  SG_ SS_Hall_Fault_Status : 13|1@0+ (1,0) [0|1] "" MHU
  SG_ SS_Commu_Fault_Status : 14|1@0+ (1,0) [0|1] "" MHU
  SG_ SS_Initialisation_Status : 15|1@0+ (1,0) [0|1] "" MHU
  SG_ SS_Posit_Percentage : 22|7@0+ (1,0) [0|100] "%" MHU
  SG_ SS_ThermalProtection_Flt_Sts : 23|1@0+ (1,0) [0|1] "" MHU
  SG_ SS_Operation_State : 31|3@0+ (1,0) [0|7] "" MHU
  SG_ SECCAN_SunshadeSts : 55|8@0+ (1,0) [0|255] "" MHU
  SG_ SS_Error_RSP : 63|1@0+ (1,0) [0|1] "" MHU

BO_ 522 ETG_STATUS: 8 XGW_Info
  SG_ ETG_Lift_Gate_Status : 2|3@0+ (1,0) [0|7] "-" MHU
  SG_ ETG_Power_Latch_Status : 5|3@0+ (1,0) [0|7] "-" MHU
  SG_ ETG_Latch_Segment : 7|2@0+ (1,0) [0|3] "" MHU
  SG_ ETG_Opening_Percentage : 15|8@0+ (1,0) [0|100] "%" MHU
  SG_ ETG_DSW_Status : 16|1@0+ (1,0) [0|1] "" MHU
  SG_ ETG_GSW_Status : 17|1@0+ (1,0) [0|1] "" MHU
  SG_ ETG_LTS_Status : 18|1@0+ (1,0) [0|1] "-" MHU
  SG_ ETG_RTS_Status : 19|1@0+ (1,0) [0|1] "-" MHU
  SG_ ETG_HAL_Status : 20|1@0+ (1,0) [0|1] "-" MHU
  SG_ ETG_FUL_Status : 21|1@0+ (1,0) [0|1] "-" MHU
  SG_ ETG_AJR_Status : 22|1@0+ (1,0) [0|1] "" MHU
  SG_ ETG_NTL_Status : 23|1@0+ (1,0) [0|1] "-" MHU
  SG_ ETG_ERR_Voltage : 25|2@0+ (1,0) [0|3] "-" MHU
  SG_ ETG_ERR_Left_Motor : 27|2@0+ (1,0) [0|3] "" MHU
  SG_ ETG_ERR_Right_Motor : 29|2@0+ (1,0) [0|3] "-" MHU
  SG_ ETG_ERR_Latch : 31|2@0+ (1,0) [0|3] "-" MHU
  SG_ ETG_ERR_Hall : 33|2@0+ (1,0) [0|3] "" MHU
  SG_ ETG_Lift_Motor_Stall : 34|1@0+ (1,0) [0|1] "" MHU
  SG_ ETG_Lift_Motor_AntiPinch : 35|1@0+ (1,0) [0|1] "-" MHU
  SG_ ETG_Lift_Motor_Thermal : 36|1@0+ (1,0) [0|1] "" MHU
  SG_ ETG_Power_Latch_Thermal : 37|1@0+ (1,0) [0|1] "-" MHU
  SG_ ETG_Abuse_Protection : 38|1@0+ (1,0) [0|1] "" MHU

BO_ 523 BCM_FKS_STATUS: 2 XGW_Info
  SG_ FKS_RespError : 0|1@0+ (1,0) [0|1] "-" MHU
  SG_ FKS_OpenReq : 2|2@0+ (1,0) [0|3] "" MHU
  SG_ FKS_HWError : 3|1@0+ (1,0) [0|1] "-" MHU
  SG_ FKS_AntennaError : 5|2@0+ (1,0) [0|3] "-" MHU
  SG_ FKS_OverVolDected : 6|1@0+ (1,0) [0|1] "-" MHU
  SG_ FKS_UnderVolDected : 7|1@0+ (1,0) [0|1] "-" MHU
  SG_ FKS_activate_deactivate : 10|2@0+ (1,0) [0|3] "-" MHU

BO_ 524 IC_ODO: 8 MHU
  SG_ CHKSM_IC_ODO : 7|8@0+ (1,0) [0|255] "" HUD,XGW_Info
  SG_ ALIV_IC_ODO : 11|4@0+ (1,0) [0|14] "" HUD,XGW_Info
  SG_ MHU_Odometer_IC : 23|20@0+ (1,0) [0|999999] "km" HUD,XGW_Info

BO_ 525 IDB_STATUS: 8 XGW_Info
  SG_ CHKSM_IDB_STATUS : 7|8@0+ (1,0) [0|255] "" ADAS_Info,AMP,CPD,EASC,HUD,MHU
  SG_ ALV_IDB_STATUS : 11|4@0+ (1,0) [0|14] "" ADAS_Info,AMP,CPD,EASC,HUD,MHU
  SG_ ESPTransRequestType : 13|2@0+ (1,0) [0|3] "" ADAS_Info,AMP,CPD,EASC,HUD,MHU
  SG_ ABSFault : 14|1@0+ (1,0) [0|1] "" ADAS_Info,AMP,CPD,EASC,HUD,MHU
  SG_ ABSActive : 15|1@0+ (1,0) [0|1] "" ADAS_Info,AMP,CPD,EASC,HUD,MHU
  SG_ VehicleSpd : 23|13@0+ (0.05625,0) [0|300] "km/h" ADAS_Info,AMP,CPD,EASC,HUD,MHU
  SG_ ESC_VehicleStandstill : 24|1@0+ (1,0) [0|1] "" ADAS_Info,AMP,CPD,EASC,HUD,MHU
  SG_ MCPressureSts : 25|1@0+ (1,0) [0|1] "" ADAS_Info,AMP,CPD,EASC,HUD,MHU
  SG_ VehicleSpdSts : 26|1@0+ (1,0) [0|1] "" ADAS_Info,AMP,CPD,EASC,HUD,MHU
  SG_ MCPressure : 39|8@0+ (2,-42.5) [-42.5|465.5] "bar" ADAS_Info,AMP,CPD,EASC,HUD,MHU
  SG_ ESC_Braking_effort : 40|1@0+ (1,0) [0|1] "" ADAS_Info,AMP,CPD,EASC,HUD,MHU
  SG_ BRAKE_LightonRequestEPBi : 42|2@0+ (1,0) [0|3] "" ADAS_Info,AMP,CPD,EASC,HUD,MHU
  SG_ VDCActive : 43|1@0+ (1,0) [0|1] "" ADAS_Info,AMP,CPD,EASC,HUD,MHU
  SG_ TCSActive : 44|1@0+ (1,0) [0|1] "" ADAS_Info,AMP,CPD,EASC,HUD,MHU
  SG_ TCSAvailable : 45|1@0+ (1,0) [0|1] "" ADAS_Info,AMP,CPD,EASC,HUD,MHU
  SG_ IDBActive : 46|1@0+ (1,0) [0|1] "" ADAS_Info,AMP,CPD,EASC,HUD,MHU
  SG_ IDBFault : 47|1@0+ (1,0) [0|1] "" ADAS_Info,AMP,CPD,EASC,HUD,MHU
  SG_ ESC_VehicleHoldStat : 51|2@0+ (1,0) [0|3] "" ADAS_Info,AMP,CPD,EASC,HUD,MHU
  SG_ IDB_Power_Stage : 55|4@0+ (1,0) [0|15] "" ADAS_Info,AMP,CPD,EASC,HUD,MHU
  SG_ ESC_BrakeReleasedFailsafe : 56|1@0+ (1,0) [0|1] "" ADAS_Info,AMP,CPD,EASC,HUD,MHU

BO_ 526 BMS_FaultInfo: 8 XGW_Info
 SG_ BMS_faultnumber : 7|64@0+ (1,0) [0|1.84467E+019] ""  MHU

BO_ 531 VCU_POD_reqDCDC: 8 XGW_Info
  SG_ CHSKM_VCU_POD_reqDCDC : 7|8@0+ (1,0) [0|255] "" MHU
  SG_ ALV_VCU_POD_reqDCDC : 11|4@0+ (1,0) [0|14] "" MHU
  SG_ VCU_enableDCDC : 13|2@0+ (1,0) [0|3] "" MHU
  SG_ VCU_vDCDCRequest : 23|16@0+ (0.0625,0) [9|16] "V" MHU
  SG_ VCU_iDCDCRequest_lim : 39|16@0+ (0.0625,0) [0|300] "A" MHU

BO_ 532 BMS_Sts_0x214: 8 XGW_Info
  SG_ Checksum_0x214 : 7|8@0+ (1,0) [0|255] "" MHU
  SG_ Rolling_Counter_0x214 : 11|4@0+ (1,0) [0|14] "" MHU
  SG_ BMS_Display_SOC : 21|10@0+ (0.1,0) [0|100] "%" MHU
  SG_ BMS_SOCE : 27|14@0+ (0.01,0) [0|100] "%" MHU

BO_ 533 BMS_Sts: 8 XGW_Info
  SG_ Checksum_0x215 : 7|8@0+ (1,0) [0|255] "" HUD,MHU
  SG_ Rolling_Counter_0x215 : 11|4@0+ (1,0) [0|14] "" HUD,MHU
  SG_ BMS_BatBalance_ERR : 12|1@0+ (1,0) [0|1] "" HUD,MHU
  SG_ BMS_Balance_STS : 13|1@0+ (1,0) [0|1] "" HUD,MHU
  SG_ BMS_IGN_Sts : 14|1@0+ (1,0) [0|1] "" HUD,MHU
  SG_ BMS_HWCrash_Sts : 15|1@0+ (1,0) [0|1] "" HUD,MHU
  SG_ BMS_HVIL_STS : 17|2@0+ (1,0) [0|3] "" HUD,MHU
  SG_ BMS_HVOnOff_STS : 19|2@0+ (1,0) [0|3] "" HUD,MHU
  SG_ BMS_ERR_LEV : 23|4@0+ (1,0) [0|7] "-" HUD,MHU
  SG_ BMS_SocActual_EST : 25|10@0+ (0.1,0) [0|100] "%" HUD,MHU
  SG_ BMS_Sys_STS : 29|4@0+ (1,0) [0|15] "" HUD,MHU
  SG_ BMS_ISU_Status : 31|2@0+ (1,0) [0|3] "" HUD,MHU
  SG_ BMS_SOH : 47|8@0+ (0.5,0) [0|100] "%" HUD,MHU
  SG_ BMS_SOE : 55|8@0+ (0.5,0) [0|100] "%" HUD,MHU
  SG_ BMS_HV_Sts : 63|8@0+ (1,0) [0|255] "" HUD,MHU

BO_ 534 BMS_ChgParamReq: 8 XGW_Info
  SG_ Checksum_0x216 : 7|8@0+ (1,0) [0|255] "" MHU
  SG_ Rolling_Counter_0x216 : 11|4@0+ (1,0) [0|14] "" MHU
  SG_ BMS_RemainChargeTime : 21|14@0+ (1,0) [0|16383] "min" MHU
  SG_ BMS_ChgVoltage_REQ : 37|14@0+ (0.1,0) [0|800] "V" MHU
  SG_ BMS_ChgCurrent_REQ : 55|16@0+ (0.1,0) [0|1500] "A" MHU

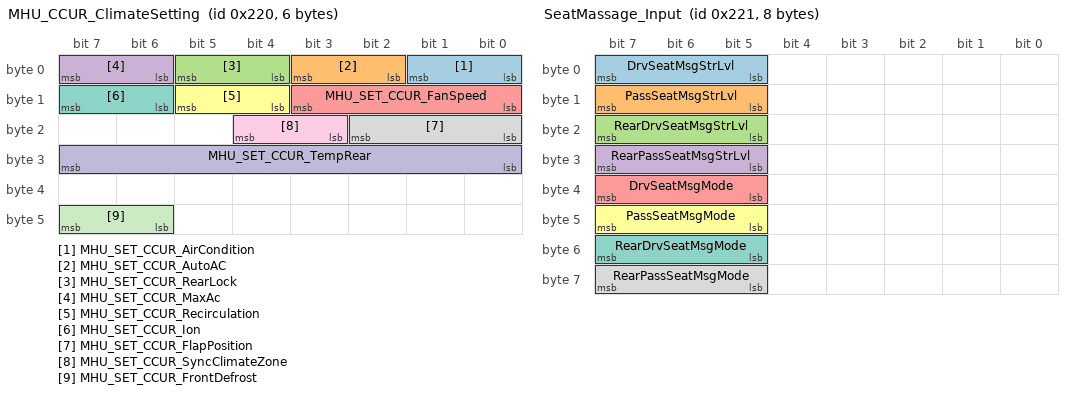
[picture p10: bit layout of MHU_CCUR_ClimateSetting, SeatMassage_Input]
BO_ 544 MHU_CCUR_ClimateSetting: 6 MHU
  SG_ MHU_SET_CCUR_AirCondition : 1|2@0+ (1,0) [0|3] "-" XGW_Info
  SG_ MHU_SET_CCUR_AutoAC : 3|2@0+ (1,0) [0|3] "-" XGW_Info
  SG_ MHU_SET_CCUR_RearLock : 5|2@0+ (1,0) [0|3] "-" XGW_Info
  SG_ MHU_SET_CCUR_MaxAc : 7|2@0+ (1,0) [0|3] "" XGW_Info
  SG_ MHU_SET_CCUR_FanSpeed : 11|4@0+ (1,0) [0|7] "-" XGW_Info
  SG_ MHU_SET_CCUR_Recirculation : 13|2@0+ (1,0) [0|3] "-" XGW_Info
  SG_ MHU_SET_CCUR_Ion : 15|2@0+ (1,0) [0|3] "" XGW_Info
  SG_ MHU_SET_CCUR_FlapPosition : 18|3@0+ (1,0) [0|7] "-" XGW_Info
  SG_ MHU_SET_CCUR_SyncClimateZone : 20|2@0+ (1,0) [0|3] "-" XGW_Info
  SG_ MHU_SET_CCUR_TempRear : 31|8@0+ (0.5,0) [16|32] "Degree C" XGW_Info
  SG_ MHU_SET_CCUR_FrontDefrost : 47|2@0+ (1,0) [0|3] "" XGW_Info

BO_ 545 SeatMassage_Input: 8 MHU
  SG_ DrvSeatMsgStrLvl : 7|3@0+ (1,0) [0|7] "" XGW_Info
  SG_ PassSeatMsgStrLvl : 15|3@0+ (1,0) [0|7] "" XGW_Info
  SG_ RearDrvSeatMsgStrLvl : 23|3@0+ (1,0) [0|7] "-" XGW_Info
  SG_ RearPassSeatMsgStrLvl : 31|3@0+ (1,0) [0|7] "" XGW_Info
  SG_ DrvSeatMsgMode : 39|3@0+ (1,0) [0|7] "" XGW_Info
  SG_ PassSeatMsgMode : 47|3@0+ (1,0) [0|7] "" XGW_Info
  SG_ RearDrvSeatMsgMode : 55|3@0+ (1,0) [0|7] "" XGW_Info
  SG_ RearPassSeatMsgMode : 63|3@0+ (1,0) [0|7] "-" XGW_Info

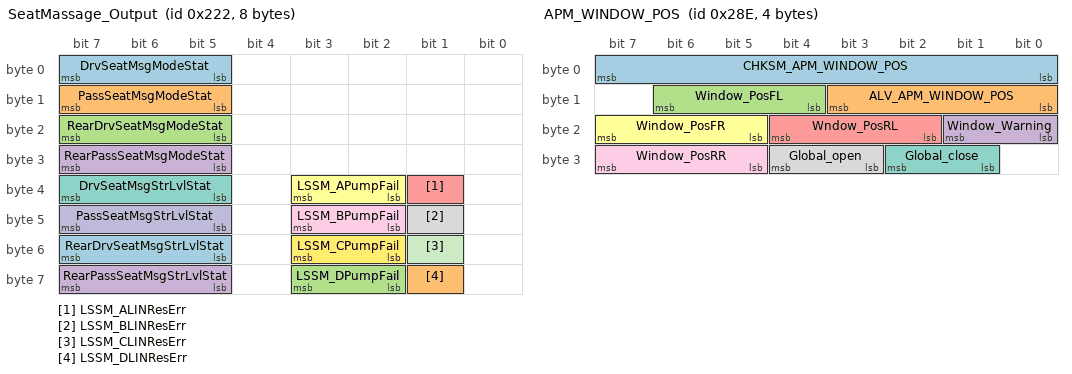
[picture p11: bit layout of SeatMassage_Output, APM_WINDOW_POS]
BO_ 546 SeatMassage_Output: 8 XGW_Info
  SG_ DrvSeatMsgModeStat : 7|3@0+ (1,0) [0|7] "" MHU
  SG_ PassSeatMsgModeStat : 15|3@0+ (1,0) [0|7] "" MHU
  SG_ RearDrvSeatMsgModeStat : 23|3@0+ (1,0) [0|7] "" MHU
  SG_ RearPassSeatMsgModeStat : 31|3@0+ (1,0) [0|7] "" MHU
  SG_ LSSM_ALINResErr : 33|1@0+ (1,0) [0|1] "" MHU
  SG_ LSSM_APumpFail : 35|2@0+ (1,0) [0|3] "" MHU
  SG_ DrvSeatMsgStrLvlStat : 39|3@0+ (1,0) [0|7] "" MHU
  SG_ LSSM_BLINResErr : 41|1@0+ (1,0) [0|1] "" MHU
  SG_ LSSM_BPumpFail : 43|2@0+ (1,0) [0|3] "" MHU
  SG_ PassSeatMsgStrLvlStat : 47|3@0+ (1,0) [0|7] "-" MHU
  SG_ LSSM_CLINResErr : 49|1@0+ (1,0) [0|1] "" MHU
  SG_ LSSM_CPumpFail : 51|2@0+ (1,0) [0|3] "-" MHU
  SG_ RearDrvSeatMsgStrLvlStat : 55|3@0+ (1,0) [0|7] "-" MHU
  SG_ LSSM_DLINResErr : 57|1@0+ (1,0) [0|1] "" MHU
  SG_ LSSM_DPumpFail : 59|2@0+ (1,0) [0|3] "-" MHU
  SG_ RearPassSeatMsgStrLvlStat : 63|3@0+ (1,0) [0|7] "" MHU

BO_ 549 BMS_FaultMgr_0x225: 8 XGW_Info
  SG_ Checksum_0x225 : 7|8@0+ (1,0) [0|255] "" MHU
  SG_ Rolling_Counter_0x225 : 11|4@0+ (1,0) [0|14] "" MHU
  SG_ CDM_bAcvCanComStblMon : 12|1@0+ (1,0) [0|1] "" MHU
  SG_ FRMo_bErrHvbatStReqExtMon : 13|1@0+ (1,0) [0|1] "" MHU
  SG_ FRMo_bErrChrgnAllwdExtMon : 14|1@0+ (1,0) [0|1] "" MHU
  SG_ FRMo_bErrVehCrashStExtMon : 15|1@0+ (1,0) [0|1] "" MHU
  SG_ CDM_bErrComctnLossCanMon : 16|1@0+ (1,0) [0|1] "" MHU
  SG_ CTCMon_bErrCtctrSopcMon : 17|1@0+ (1,0) [0|1] "" MHU
  SG_ CTCMon_bInvldCtctrHisdIFbMon : 18|1@0+ (1,0) [0|1] "" MHU
  SG_ CTCMon_bInvldCtctrLosdUFbMon : 19|1@0+ (1,0) [0|1] "" MHU
  SG_ CTM_bErrCellTDifMaxMon : 20|1@0+ (1,0) [0|1] "" MHU
  SG_ CTM_bErrCellTMaxMon : 21|1@0+ (1,0) [0|1] "" MHU
  SG_ CTM_bErrCellTMinMon : 22|1@0+ (1,0) [0|1] "" MHU
  SG_ CTM_bErrThrwyPredMon : 23|1@0+ (1,0) [0|1] "" MHU
  SG_ CUM_bErrCellUDifMaxMon : 24|1@0+ (1,0) [0|1] "" MHU
  SG_ CUM_bErrCellUMaxMon : 25|1@0+ (1,0) [0|1] "" MHU
  SG_ CUM_bErrCellUMinMon : 26|1@0+ (1,0) [0|1] "" MHU
  SG_ CUM_bErrCellUProtnMaxNvMon : 27|1@0+ (1,0) [0|1] "" MHU
  SG_ CUM_bErrCellUProtnMinNvMon : 28|1@0+ (1,0) [0|1] "" MHU
  SG_ CUM_bErrPackUImplyMon : 29|1@0+ (1,0) [0|1] "" MHU
  SG_ EHPMon_bRdyHvilMon : 30|1@0+ (1,0) [0|1] "" MHU
  SG_ EHPMon_bErrWlddNegNvMon : 31|1@0+ (1,0) [0|1] "" MHU
  SG_ EHPMon_bErrWlddPosNvMon : 32|1@0+ (1,0) [0|1] "" MHU
  SG_ EHPMon_bErrWlddPrechNvMon : 33|1@0+ (1,0) [0|1] "" MHU
  SG_ EHPMon_bErrHvilMon : 34|1@0+ (1,0) [0|1] "" MHU
  SG_ EHPMon_bErrHvilShoMon : 35|1@0+ (1,0) [0|1] "" MHU
  SG_ EHPMon_bErrPackIslnRNvMon : 36|1@0+ (1,0) [0|1] "" MHU
  SG_ EHPMon_bErrVehCrashNvMon : 37|1@0+ (1,0) [0|1] "" MHU
  SG_ EHPMon_bErrVehIslnRNvMon : 38|1@0+ (1,0) [0|1] "" MHU
  SG_ FRMo_bErrMemStorgNvMon : 39|1@0+ (1,0) [0|1] "" MHU
  SG_ L1IM_bErrClmp30MaxMonInp : 40|1@0+ (1,0) [0|1] "" MHU
  SG_ L1IM_bErrClmp30MinMonInp : 41|1@0+ (1,0) [0|1] "" MHU
  SG_ L1IM_bErrCtctrDtrtMonInp : 42|1@0+ (1,0) [0|1] "" MHU
  SG_ L1IM_bErrUActImplyMonInp : 43|1@0+ (1,0) [0|1] "" MHU
  SG_ MCCM_bAcvMdulCtlrStsMon : 44|1@0+ (1,0) [0|1] "" MHU
  SG_ MCCM_bErrLntecSngFltMon : 45|1@0+ (1,0) [0|1] "" MHU
  SG_ MCCM_bErrLntecLtntFltMon : 46|1@0+ (1,0) [0|1] "" MHU
  SG_ MCCM_bErrMdulCellSnsrCfgMon : 47|1@0+ (1,0) [0|1] "" MHU
  SG_ MCCM_bErrMdulCtlrComMon : 48|1@0+ (1,0) [0|1] "" MHU
  SG_ MCCM_bErrSnsrTEltlMon : 49|1@0+ (1,0) [0|1] "" MHU
  SG_ MCCM_bWarnSnsrTEltlMon : 50|1@0+ (1,0) [0|1] "" MHU
  SG_ PCM_bRdySnsrIMon : 51|1@0+ (1,0) [0|1] "" MHU
  SG_ PCM_bErrPackEFlowMaxLimMon : 52|1@0+ (1,0) [0|1] "" MHU
  SG_ PCM_bErrPackIChDchaMaxLimMon : 53|1@0+ (1,0) [0|1] "" MHU
  SG_ PCM_bErrSnsrIImplyMon : 54|1@0+ (1,0) [0|1] "" MHU
  SG_ FRMo_bErrSnsrI1ExtMon : 55|1@0+ (1,0) [0|1] "" MHU
  SG_ PCM_bInvldSnsrI1Mon : 56|1@0+ (1,0) [0|1] "" MHU
  SG_ PCM_bInvldSnsrI2Mon : 57|1@0+ (1,0) [0|1] "" MHU
  SG_ FRMo_bErrSopcLvl3Mon : 58|1@0+ (1,0) [0|1] "" MHU
  SG_ BMS_FRMo_Reserved_1 : 59|1@0+ (1,0) [0|1] "" MHU
  SG_ BMS_FRMo_Reserved_2 : 60|1@0+ (1,0) [0|1] "" MHU
  SG_ BMS_FRMo_Reserved_3 : 61|1@0+ (1,0) [0|1] "" MHU
  SG_ BMS_FRMo_Reserved_4 : 62|1@0+ (1,0) [0|1] "" MHU
  SG_ BMS_FRMo_Reserved_5 : 63|1@0+ (1,0) [0|1] "" MHU

BO_ 561 DoorFLStatus: 8 XGW_Info
  SG_ NDoorFLOutsideHandleFailure : 26|3@0+ (1,0) [0|7] "" MHU
  SG_ NDoorLatchFLFailure : 55|6@0+ (1,0) [0|63] "" MHU

BO_ 565 TRM_STATUS: 3 XGW_Info
  SG_ CHKSM_TRM_STATUS : 7|8@0+ (1,0) [0|255] "" HUD,MHU
  SG_ ALIVE_TRM_STATUS : 11|4@0+ (1,0) [0|14] "" HUD,MHU
  SG_ TowingDetected : 21|2@0+ (1,0) [0|3] "" HUD,MHU
  SG_ TrailerDetected : 23|2@0+ (1,0) [0|3] "" HUD,MHU

BO_ 569 DoorRRStatus: 8 XGW_Info
  SG_ NDoorRROutsideHandleFailure : 26|3@0+ (1,0) [0|7] "" MHU
  SG_ NDoorLatchRRFailure : 55|6@0+ (1,0) [0|63] "" MHU

BO_ 581 BMS_CellTemp: 8 XGW_Info
  SG_ Checksum_0x245 : 7|8@0+ (1,0) [0|255] "" MHU
  SG_ Rolling_Counter_0x245 : 11|4@0+ (1,0) [0|14] "" MHU
  SG_ BMS_ProbeNumMaxCellTemp : 21|6@0+ (1,0) [0|63] "" MHU
  SG_ BMS_MinCellTemp : 31|8@0+ (1,-40) [-40|215] "°C" MHU
  SG_ BMS_ProbeNumMinCellTemp : 37|6@0+ (1,0) [0|63] "" MHU
  SG_ BMS_PackTemp : 47|8@0+ (1,-40) [-40|215] "°C" MHU
  SG_ BMS_MaxCellTemp : 55|8@0+ (1,-40) [-40|215] "°C" MHU
  SG_ BMS_MaxMinDiffCellTemp : 63|8@0+ (1,-40) [-40|215] "°C" MHU

BO_ 584 DoorFRStatus: 8 XGW_Info
  SG_ NDoorFROutsideHandleFailure : 26|3@0+ (1,0) [0|7] "" MHU
  SG_ NDoorLatchFRFailure : 55|6@0+ (1,0) [0|63] "" MHU

BO_ 585 BMS_CoolntInletOutletTmp: 8 XGW_Info
  SG_ CHSKM_BMS_CoolntInletOutletTmp : 7|8@0+ (1,0) [0|255] "" MHU
  SG_ ALV_BMS_CoolntInletOutletTmp : 11|4@0+ (1,0) [0|14] "" MHU
  SG_ BMS_CoolantInletTemp : 23|8@0+ (1,-40) [-40|215] "°C" MHU
  SG_ BMS_CoolantOutletTemp : 31|8@0+ (1,-40) [-40|215] "°C" MHU
  SG_ BMS_BDUTemp1 : 39|8@0+ (1,-40) [-40|215] "°C" MHU
  SG_ BMS_BDUTemp2 : 47|8@0+ (1,-40) [-40|215] "°C" DUMMY_ECU

BO_ 588 BMS_VCU_THMReq: 8 XGW_Info
  SG_ CHSKM_BMS_VCU_THMReq : 7|8@0+ (1,0) [0|255] "" MHU
  SG_ ALV_BMS_VCU_THMReq : 11|4@0+ (1,0) [0|14] "" MHU
  SG_ BMS_FlowRate_Req : 23|8@0+ (1,0) [0|50] "l/min" DUMMY_ECU
  SG_ BMS_CoolPwrDemand : 31|12@0+ (0.1,0) [0|10] "kW" MHU
  SG_ BMS_HeatPwrDemand : 35|12@0+ (0.1,0) [0|10] "kW" DUMMY_ECU
  SG_ BMS_VCU_PTCOnOff_Req : 48|1@0+ (1,0) [0|1] "" DUMMY_ECU
  SG_ BMS_VCU_ValveOnOff_Req : 49|1@0+ (1,0) [0|1] "" DUMMY_ECU
  SG_ BMS_PreHeatCoolReq : 51|2@0+ (1,0) [0|3] "" MHU

BO_ 596 IDB_AVL_RPM_WHL_REAR: 8 XGW_Info
  SG_ CRC_AVL_RPM_WHL_REAR : 7|8@0+ (1,0) [0|255] "" MHU
  SG_ ALIV_AVL_RPM_WHL_REAR : 11|4@0+ (1,0) [0|14] "" MHU
  SG_ AVL_RPM_WHL_RLH : 23|16@0+ (0.0156,-511.9844) [-400|400] "rad/s" MHU
  SG_ AVL_RPM_WHL_RRH : 39|16@0+ (0.0156,-511.9844) [-400|400] "rad/s" MHU
  SG_ QU_AVL_RPM_WHL_RLH : 55|4@0+ (1,0) [0|15] "Bit" MHU
  SG_ QU_AVL_RPM_WHL_RRH : 63|4@0+ (1,0) [0|15] "Bit" MHU

BO_ 597 IDB_AVL_RPM_WHL_FRONT: 8 XGW_Info
  SG_ CRC_AVL_RPM_WHL_FRONT : 7|8@0+ (1,0) [0|255] "" MHU
  SG_ ALIV_AVL_RPM_WHL_FRONT : 11|4@0+ (1,0) [0|14] "" MHU
  SG_ AVL_RPM_WHL_FLH : 23|16@0+ (0.0156,-511.9844) [-400|400] "rad/s" MHU
  SG_ AVL_RPM_WHL_FRH : 39|16@0+ (0.0156,-511.9844) [-400|400] "rad/s" MHU
  SG_ QU_AVL_RPM_WHL_FLH : 55|4@0+ (1,0) [0|15] "Bit" MHU
  SG_ QU_AVL_RPM_WHL_FRH : 63|4@0+ (1,0) [0|15] "Bit" MHU

BO_ 641 DoorRLStatus: 8 XGW_Info
  SG_ NDoorRLOutsideHandleFailure : 26|3@0+ (1,0) [0|7] "" MHU
  SG_ NDoorLatchRLFailure : 55|6@0+ (1,0) [0|63] "" MHU

BO_ 649 IDB_ACC_LONG_LAT_YAW: 8 XGW_Info
  SG_ CHKSM_IDB_ZF2 : 7|8@0+ (1,0) [0|255] "" MHU
  SG_ ALIVE_IDB_ZF2 : 11|4@0+ (1,0) [0|14] "" MHU
  SG_ AxOutStatus : 15|3@0+ (1,0) [0|7] "" MHU
  SG_ QU_VYAW_VEH : 19|4@0+ (1,0) [0|15] "" MHU
  SG_ AyOutStatus : 23|3@0+ (1,0) [0|7] "" MHU
  SG_ AcceleratorY : 31|12@0+ (0.02713,-21.5928) [-21.593|21.5928] "m/s^2" MHU
  SG_ AcceleratorX : 35|12@0+ (0.02713,-21.5928) [-21.593|21.5928] "m/s^2" MHU
  SG_ VYAW_VEH : 55|16@0+ (0.005,-163.84) [-163.84|163.83] "°/s" MHU

BO_ 654 APM_WINDOW_POS: 4 XGW_Info
  SG_ CHKSM_APM_WINDOW_POS : 7|8@0+ (1,0) [0|255] "" CPD,MHU
  SG_ ALV_APM_WINDOW_POS : 11|4@0+ (1,0) [0|14] "" CPD,MHU
  SG_ Window_PosFL : 14|3@0+ (1,0) [0|7] "-" CPD,MHU
  SG_ Window_Warning : 17|2@0+ (1,0) [0|3] "" CPD,MHU
  SG_ Wndow_PosRL : 20|3@0+ (1,0) [0|7] "" CPD,MHU
  SG_ Window_PosFR : 23|3@0+ (1,0) [0|7] "" CPD,MHU
  SG_ Global_close : 26|2@0+ (1,0) [0|3] "" CPD,MHU
  SG_ Global_open : 28|2@0+ (1,0) [0|3] "" CPD,MHU
  SG_ Window_PosRR : 31|3@0+ (1,0) [0|7] "-" CPD,MHU

BO_ 676 SVC_EHC_EHC_2: 8 XGW_Info
  SG_ ID2 M : 0|8@1+ (1,0) [0|0] "" DUMMY_ECU,MHU
  SG_ ECU_ID_WUPREG m39 : 8|8@1+ (1,0) [0|127] "" DUMMY_ECU
  SG_ ID_FN_INQY m1 : 8|16@1+ (1,0) [0|0] "" DUMMY_ECU
  SG_ ID_FN_RQ_BUS m12 : 8|16@1+ (1,0) [0|0] "" DUMMY_ECU
  SG_ NO_CC_MESS_EXT m65 : 8|16@1+ (1,0) [0|65534] "" DUMMY_ECU
  SG_ NO_CC_MESS_STD m64 : 8|16@1+ (1,0) [0|65534] "" MHU,DUMMY_ECU
  SG_ WACA m39 : 16|8@1+ (1,0) [0|0] "" DUMMY_ECU
  SG_ ID_RQ_BUS m12 : 24|8@1+ (1,0) [0|0] "" DUMMY_ECU
  SG_ ST_CC_MESS_EXT m65 : 24|2@1+ (1,0) [0|0] "" DUMMY_ECU
  SG_ ST_CC_MESS_STD m64 : 24|2@1+ (1,0) [0|0] "" MHU
  SG_ TRANF_CC_MESS_EXT m65 : 26|4@1+ (1,0) [0|14] "" DUMMY_ECU
  SG_ TRANF_CC_MESS_STD m64 : 26|4@1+ (1,0) [0|14] "" MHU
  SG_ ST_IDC_CCLK_CC_MESS_EXT m65 : 30|2@1+ (1,0) [0|0] "" DUMMY_ECU
  SG_ ST_IDC_CCLK_CC_MESS_STD m64 : 30|2@1+ (1,0) [0|0] "" MHU
  SG_ NO_FRM_CC_MESS_EXT m65 : 32|4@1+ (1,0) [0|14] "" DUMMY_ECU
  SG_ ST_RQ_BUS m12 : 32|4@1+ (1,0) [0|0] "" DUMMY_ECU
  SG_ QUAN_FRM_CC_MESS_EXT m65 : 36|4@1+ (1,0) [0|14] "" DUMMY_ECU
  SG_ ST_LAW_RQ m12 : 36|4@1+ (1,0) [0|0] "" DUMMY_ECU
  SG_ DUR_FLLUPT m12 : 40|8@1+ (1,0) [0|254] "min" DUMMY_ECU
  SG_ UTDT_CC_MESS m65 : 40|24@1+ (1,0) [0|0] "" DUMMY_ECU

BO_ 714 IC_SENSOR: 8 MHU
  SG_ CHKSM_IC_SENSOR : 7|8@0+ (1,0) [0|255] "" ADAS_Info,AMP,CPD,EASC,HUD,XGW_Info
  SG_ ALV_IC_SENSOR : 11|4@0+ (1,0) [0|14] "" ADAS_Info,AMP,CPD,EASC,HUD,XGW_Info
  SG_ MHU_STAT_AmbientTempRaw : 23|8@0+ (0.5,-40) [-40|85] "°C" ADAS_Info,AMP,CPD,EASC,HUD,XGW_Info
  SG_ MHU_STAT_FuelLevel : 31|8@0+ (1,0) [0|100] "l" ADAS_Info,AMP,CPD,EASC,HUD,XGW_Info
  SG_ MHU_STAT_AmbientTemp : 39|8@0+ (0.5,-40) [-40|85] "Degree C" ADAS_Info,AMP,CPD,EASC,HUD,XGW_Info
  SG_ MHU_STAT_CoolantLevelStatus : 47|2@0+ (1,0) [0|3] "-" ADAS_Info,AMP,CPD,EASC,HUD,XGW_Info

BO_ 753 IC_STAT_AIRBAG: 1 MHU
  SG_ MHU_STAT_AirbagWarnLamp : 1|2@0+ (1,0) [0|3] "" XGW_Info

BO_ 760 MHU_DATE_TIME: 8 MHU
  SG_ DISP_HR : 7|8@0+ (1,0) [0|23] "h" ADAS_Info,AMP,CPD,EASC,HUD,XGW_Info
  SG_ DISP_MN : 15|8@0+ (1,0) [0|59] "min" ADAS_Info,AMP,CPD,EASC,HUD,XGW_Info
  SG_ DISP_SEC : 23|8@0+ (1,0) [0|59] "s" ADAS_Info,AMP,CPD,EASC,HUD,XGW_Info
  SG_ DISP_DATE_DAY : 31|8@0+ (1,0) [1|31] "Day" ADAS_Info,AMP,CPD,EASC,HUD,XGW_Info
  SG_ DISP_DATE_MON : 35|4@0+ (1,0) [1|12] "Month" ADAS_Info,AMP,CPD,EASC,HUD,XGW_Info
  SG_ DISP_DATE_WDAY : 39|4@0+ (1,0) [0|15] "" ADAS_Info,AMP,CPD,EASC,HUD,XGW_Info
  SG_ DISP_DATE_YR : 47|16@0+ (1,0) [1|65534] "Year" ADAS_Info,AMP,CPD,EASC,HUD,XGW_Info
  SG_ ST_DISP_CTI_DATE : 63|4@0+ (1,0) [0|15] "" AMP,CPD,EASC,HUD,XGW_Info

BO_ 761 MHU_DATE_TIME_UTC: 8 MHU
  SG_ DISP_HR_UTC : 7|8@0+ (1,0) [0|23] "h" XGW_Info
  SG_ DISP_MN_UTC : 15|8@0+ (1,0) [0|59] "min" XGW_Info
  SG_ DISP_SEC_UTC : 23|8@0+ (1,0) [0|59] "s" XGW_Info
  SG_ DISP_DATE_DAY_UTC : 31|8@0+ (1,0) [1|31] "Day" XGW_Info
  SG_ DISP_DATE_MON_UTC : 35|4@0+ (1,0) [1|12] "Month" XGW_Info
  SG_ DISP_DATE_YR_UTC : 47|16@0+ (1,0) [1|65534] "Year" XGW_Info

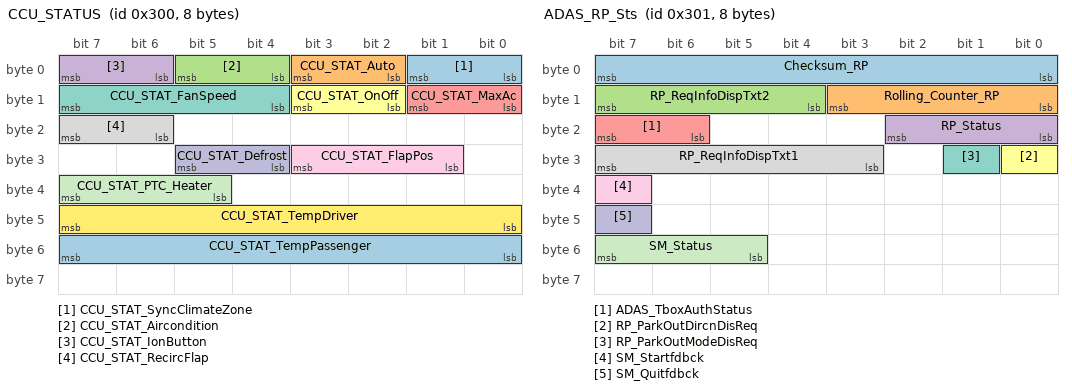
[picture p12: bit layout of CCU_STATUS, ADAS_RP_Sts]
BO_ 768 CCU_STATUS: 8 XGW_Info
  SG_ CCU_STAT_SyncClimateZone : 1|2@0+ (1,0) [0|3] "" MHU
  SG_ CCU_STAT_Auto : 3|2@0+ (1,0) [0|3] "-" MHU
  SG_ CCU_STAT_Aircondition : 5|2@0+ (1,0) [0|3] "" MHU
  SG_ CCU_STAT_IonButton : 7|2@0+ (1,0) [0|3] "" MHU
  SG_ CCU_STAT_MaxAc : 9|2@0+ (1,0) [0|3] "" MHU
  SG_ CCU_STAT_OnOff : 11|2@0+ (1,0) [0|3] "Bit" MHU
  SG_ CCU_STAT_FanSpeed : 15|4@0+ (1,0) [0|15] "" MHU
  SG_ CCU_STAT_RecircFlap : 23|2@0+ (1,0) [0|3] "" MHU
  SG_ CCU_STAT_FlapPos : 27|3@0+ (1,0) [0|7] "" MHU
  SG_ CCU_STAT_Defrost : 29|2@0+ (1,0) [0|3] "-" MHU
  SG_ CCU_STAT_PTC_Heater : 39|3@0+ (1,0) [0|7] "-" MHU
  SG_ CCU_STAT_TempDriver : 47|8@0+ (0.5,0) [16|32] "Degree C" MHU
  SG_ CCU_STAT_TempPassenger : 55|8@0+ (0.5,0) [16|32] "Degree C" MHU

BO_ 769 ADAS_RP_Sts: 8 ADAS_Info
  SG_ Checksum_RP : 7|8@0+ (1,0) [0|255] "" MHU
  SG_ Rolling_Counter_RP : 11|4@0+ (1,0) [0|14] "" MHU
  SG_ RP_ReqInfoDispTxt2 : 15|4@0+ (1,0) [0|15] "-" MHU
  SG_ RP_Status : 18|3@0+ (1,0) [0|7] "-" MHU
  SG_ ADAS_TboxAuthStatus : 23|2@0+ (1,0) [0|3] "-" MHU
  SG_ RP_ParkOutDircnDisReq : 24|1@0+ (1,0) [0|1] "-" MHU
  SG_ RP_ParkOutModeDisReq : 25|1@0+ (1,0) [0|1] "-" MHU
  SG_ RP_ReqInfoDispTxt1 : 31|5@0+ (1,0) [0|31] "-" MHU
  SG_ SM_Startfdbck : 39|1@0+ (1,0) [0|1] "" MHU
  SG_ SM_Quitfdbck : 47|1@0+ (1,0) [0|1] "" MHU
  SG_ SM_Status : 55|3@0+ (1,0) [0|7] "" MHU

BO_ 770 CCU_TEMP_PRESSURE: 6 XGW_Info
  SG_ CHKSM_CCU_TEMP_PRESSURE : 7|8@0+ (1,0) [0|255] "" ADAS_Info,AMP,CPD,EASC,HUD,MHU
  SG_ ALV_CCU_TEMP_PRESSURE : 11|4@0+ (1,0) [0|14] "" ADAS_Info,AMP,CPD,EASC,HUD,MHU
  SG_ CCU_Pressure_AC : 23|6@0+ (1,0) [0|62] "bar" ADAS_Info,AMP,CPD,EASC,HUD,MHU
  SG_ CCU_InteriorTemp : 31|8@0+ (0.5,-40) [-40|85] "Degree C" ADAS_Info,AMP,CPD,EASC,HUD,MHU
  SG_ CCU_TempEx_AC : 39|8@0+ (0.5,-40) [-40|85] "Degree C" ADAS_Info,AMP,CPD,EASC,HUD,MHU
  SG_ CCU_EvaporatorTemp : 47|8@0+ (0.5,-40) [-40|85] "Degree C" ADAS_Info,AMP,CPD,EASC,HUD,MHU

BO_ 771 ADAS_DMS_STATUS: 8 ADAS_Info
  SG_ CHKSM_ADAS_DMS_STATUS : 7|8@0+ (1,0) [0|255] "" MHU
  SG_ ALV_ADAS_DMS_STATUS : 11|4@0+ (1,0) [0|14] "" MHU
  SG_ ADAS_DMS_Thief_image_sendrequest : 15|2@0+ (1,0) [0|3] "-" MHU
  SG_ ADAS_DMS_Status_feed : 18|3@0+ (1,0) [0|7] "-" MHU
  SG_ ADAS_DMS_Confidence_score : 20|2@0+ (1,0) [0|3] "-" MHU
  SG_ ADAS_DMS_Driver_registration : 23|3@0+ (1,0) [0|7] "-" MHU
  SG_ SECCAN_ADAS_DMS_STATUS : 63|8@0+ (1,0) [0|255] "" MHU

BO_ 773 BMS_Insulation: 8 XGW_Info
  SG_ CHSKM_BMS_Insulation : 7|8@0+ (1,0) [0|255] "" MHU
  SG_ ALV_BMS_Insulation : 11|4@0+ (1,0) [0|14] "" MHU
  SG_ BMS_VCU_Insulation_Mon_Sts : 15|1@0+ (1,0) [0|1] "" DUMMY_ECU
  SG_ BMS_PackInsuRes : 23|16@0+ (1,0) [0|60000] "kOhm" MHU

BO_ 775 CPD_OUTPUT: 3 CPD
  SG_ CHKSM_CPD_Output_1 : 7|8@0+ (1,0) [0|255] "" MHU,XGW_Info
  SG_ ALV_CPD_Output_1 : 11|4@0+ (1,0) [0|14] "" MHU,XGW_Info
  SG_ OUT_Alert_TO_BCM : 14|3@0+ (1,0) [0|7] "-" XGW_Info,MHU
  SG_ CPD_State_information : 20|3@0+ (1,0) [0|7] "-" MHU,XGW_Info
  SG_ OUT_Alert_TO_MHU : 23|3@0+ (1,0) [0|7] "-" MHU,XGW_Info

BO_ 776 MHU_CPD_Confirm: 8 MHU
  SG_ MHU_CPD_Setting : 4|3@0+ (1,0) [0|7] "-" CPD
  SG_ MHU_CPD_Confirmation_On_HMI : 7|3@0+ (1,0) [0|7] "-" CPD

BO_ 777 ADAS_Immo_MHU: 8 ADAS_Info
  SG_ ADAS_Immo_MHU_Byte_0 : 7|8@0+ (1,0) [0|255] "-" MHU
  SG_ ADAS_Immo_MHU_Byte_1 : 15|8@0+ (1,0) [0|255] "-" MHU
  SG_ ADAS_Immo_MHU_Byte_2 : 23|8@0+ (1,0) [0|255] "-" MHU
  SG_ ADAS_Immo_MHU_Byte_3 : 31|8@0+ (1,0) [0|255] "-" MHU
  SG_ ADAS_Immo_MHU_Byte_4 : 39|8@0+ (1,0) [0|255] "-" MHU
  SG_ ADAS_Immo_MHU_Byte_5 : 47|8@0+ (1,0) [0|255] "-" MHU
  SG_ ADAS_Immo_MHU_Byte_6 : 55|8@0+ (1,0) [0|255] "-" MHU
  SG_ ADAS_Immo_MHU_Byte_7 : 63|8@0+ (1,0) [0|255] "-" MHU

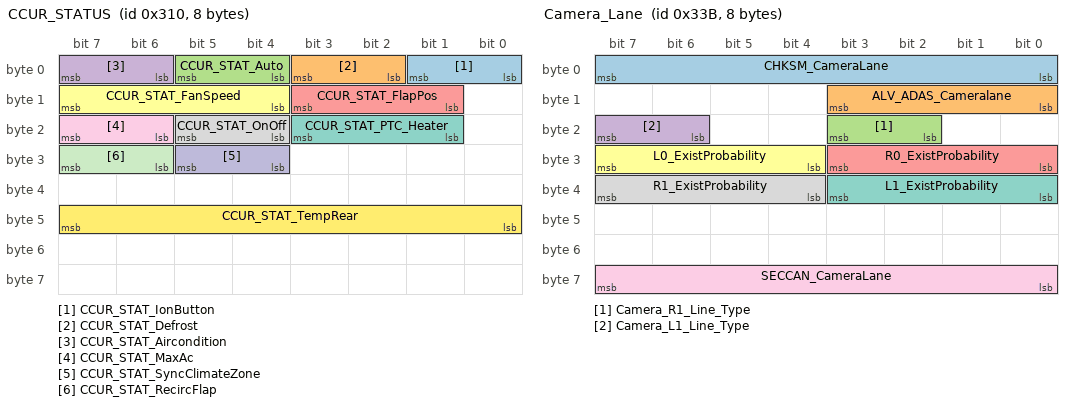
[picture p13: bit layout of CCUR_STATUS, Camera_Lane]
BO_ 784 CCUR_STATUS: 8 XGW_Info
  SG_ CCUR_STAT_IonButton : 1|2@0+ (1,0) [0|3] "-" MHU
  SG_ CCUR_STAT_Defrost : 3|2@0+ (1,0) [0|3] "" MHU
  SG_ CCUR_STAT_Auto : 5|2@0+ (1,0) [0|3] "" MHU
  SG_ CCUR_STAT_Aircondition : 7|2@0+ (1,0) [0|3] "-" MHU
  SG_ CCUR_STAT_FlapPos : 11|3@0+ (1,0) [0|7] "-" MHU
  SG_ CCUR_STAT_FanSpeed : 15|4@0+ (1,0) [0|15] "-" MHU
  SG_ CCUR_STAT_PTC_Heater : 19|3@0+ (1,0) [0|7] "" MHU
  SG_ CCUR_STAT_OnOff : 21|2@0+ (1,0) [0|3] "Bit" MHU
  SG_ CCUR_STAT_MaxAc : 23|2@0+ (1,0) [0|3] "" MHU
  SG_ CCUR_STAT_SyncClimateZone : 29|2@0+ (1,0) [0|3] "-" MHU
  SG_ CCUR_STAT_RecircFlap : 31|2@0+ (1,0) [0|3] "-" MHU
  SG_ CCUR_STAT_TempRear : 47|8@0+ (0.5,0) [16|32] "Degree C" MHU

BO_ 787 POD_StatusCharger1: 8 XGW_Info
  SG_ CHSKM_POD_StatusCharger1 : 7|8@0+ (1,0) [0|255] "" MHU
  SG_ ALV_POD_StatusCharger1 : 11|4@0+ (1,0) [0|14] "" MHU
  SG_ POD_statusOBC : 15|3@0+ (1,0) [0|7] "" MHU
  SG_ POD_OBC_Max_Current_Out : 23|8@0+ (1,0) [0|64] "A" MHU
  SG_ POD_iDCOut : 31|8@0+ (1,0) [0|64] "A" MHU
  SG_ POD_vDCOut : 39|16@0+ (0.0625,0) [0|512] "V" MHU

BO_ 803 POD_StatusCharger2: 8 XGW_Info
  SG_ CHSKM_POD_StatusCharger2 : 7|8@0+ (1,0) [0|255] "" MHU
  SG_ ALV_POD_StatusCharger2 : 11|4@0+ (1,0) [0|14] "" MHU
  SG_ POD_phaseACInput : 15|2@0+ (1,0) [0|3] "" MHU
  SG_ POD_iACInput : 23|16@0+ (0.0625,0) [0|60] "A" MHU
  SG_ POD_vACInput : 39|16@0+ (0.0625,0) [0|512] "V" MHU

BO_ 804 HOD_Heating: 2 MHU
  SG_ Steering_HeatingControl : 7|2@0+ (1,0) [0|3] "" XGW_Info

BO_ 805 STWH_Feedback: 2 XGW_Info
  SG_ Steering_HeatingControlFdbk : 7|2@0+ (1,0) [0|3] "-" MHU

BO_ 806 POD_StatusDCDC1: 8 XGW_Info
  SG_ CHSKM_POD_StatusDCDC1 : 7|8@0+ (1,0) [0|255] "" MHU
  SG_ ALV_POD_StatusDCDC1 : 11|4@0+ (1,0) [0|14] "" MHU
  SG_ POD_statusDCDC : 14|3@0+ (1,0) [0|7] "" MHU
  SG_ POD_DCDC_Max_Current_Out : 23|8@0+ (1,0) [0|250] "A" MHU

BO_ 807 POD_StatusFC: 8 XGW_Info
  SG_ CHKSM_POD_StatusFC : 7|8@0+ (1,0) [0|255] "" MHU
  SG_ ALV_POD_StatusFC : 11|4@0+ (1,0) [0|14] "" MHU
  SG_ POD_vFC : 23|16@0+ (0.0625,0) [0|512] "V" MHU
  SG_ POD_statusFCContactors : 47|3@0+ (1,0) [0|7] "" MHU

BO_ 808 IC_RELATIVIME: 6 MHU
  SG_ T_SEC_COU_REL : 7|32@0+ (1,0) [0|4294967294] "s" XGW_Info
  SG_ T_DAY_COU_ABSL : 39|16@0+ (1,0) [0|65534] "Day" XGW_Info

BO_ 809 BCM_ODO: 8 XGW_Info
  SG_ CRC_BCM_ODO : 7|8@0+ (1,0) [0|255] "" MHU
  SG_ ALIV_BCM_ODO : 11|4@0+ (1,0) [0|14] "" MHU
  SG_ Odometer_BCM : 23|20@0+ (1,0) [0|999999] "km" MHU
  SG_ SECCAN_BCM_ODO : 63|8@0+ (1,0) [0|255] "" MHU

BO_ 816 IC_MILEAGE: 8 XGW_Info
  SG_ MILE_KM : 7|24@0+ (1,0) [0|999999] "km" ADAS_Info,AMP,CPD,EASC,HUD,MHU
  SG_ FLLV_FUTA : 31|8@0+ (1,0) [0|254] "l" ADAS_Info,AMP,CPD,EASC,HUD,MHU
  SG_ RNG : 51|12@0+ (1,0) [0|4094] "km" ADAS_Info,AMP,CPD,EASC,HUD,MHU
  SG_ ST_FLLV_FUTA_SPAR : 55|2@0+ (1,0) [0|3] "" ADAS_Info,AMP,CPD,EASC,HUD,MHU

BO_ 818 BMS_PackInfo: 8 XGW_Info
 SG_ Checksum_0x332 : 7|8@0+ (1,0) [0|255] "" MHU
 SG_ Rolling_Counter_0x332 : 11|4@0+ (1,0) [0|14] "" MHU
 SG_ BMS_PackCNom : 23|16@0+ (0.1,0) [0|6553.5] "kWh" MHU
 SG_ BMS_PackTemp_0x332 : 39|8@0+ (1,-40) [-40|215] "Degree C" MHU

BO_ 827 Camera_Lane: 8 ADAS_Info
  SG_ CHKSM_CameraLane : 7|8@0+ (1,0) [0|255] "" MHU
  SG_ ALV_ADAS_Cameralane : 11|4@0+ (1,0) [0|14] "" MHU
  SG_ Camera_R1_Line_Type : 19|2@0+ (1,0) [0|3] "-" MHU
  SG_ Camera_L1_Line_Type : 23|2@0+ (1,0) [0|3] "-" MHU
  SG_ R0_ExistProbability : 27|4@0+ (0.1,0) [0|1] "-" MHU
  SG_ L0_ExistProbability : 31|4@0+ (0.1,0) [0|1] "-" MHU
  SG_ L1_ExistProbability : 35|4@0+ (0.1,0) [0|1] "-" MHU
  SG_ R1_ExistProbability : 39|4@0+ (0.1,0) [0|1] "-" MHU
  SG_ SECCAN_CameraLane : 63|8@0+ (1,0) [0|255] "" MHU

BO_ 833 Camera_Object01: 8 ADAS_Info
  SG_ SECCAN_Cam_OBJ_1 : 7|8@0+ (1,0) [0|255] "" MHU
  SG_ ADAS_OBJ01_Class : 18|3@0+ (1,0) [0|7] "-" MHU
  SG_ ADAS_OBJ01_LgtDis : 29|14@0+ (0.025,-10) [-10|399.575] "-" MHU
  SG_ ADAS_OBJ01_ID : 47|8@0+ (1,0) [0|255] "-" MHU
  SG_ ADAS_OBJ01_LatDis : 49|10@0+ (0.0293,-15.0146) [-15.0146|14.9593] "-" MHU
  SG_ ADAS_OBJ01_Lane : 55|3@0+ (1,0) [0|7] "-" MHU

BO_ 835 Camera_Object02: 8 ADAS_Info
  SG_ SECCAN_Cam_OBJ_2 : 7|8@0+ (1,0) [0|255] "" MHU
  SG_ ADAS_OBJ02_Class : 18|3@0+ (1,0) [0|7] "-" MHU
  SG_ ADAS_OBJ02_LgtDis : 29|14@0+ (0.025,-10) [-10|399.575] "-" MHU
  SG_ ADAS_OBJ02_ID : 47|8@0+ (1,0) [0|255] "-" MHU
  SG_ ADAS_OBJ02_LatDis : 49|10@0+ (0.0293,-15.0146) [-15.0146|14.985] "-" MHU
  SG_ ADAS_OBJ02_Lane : 55|3@0+ (1,0) [0|7] "-" MHU

BO_ 838 POD_StatusDCDC2: 8 XGW_Info
  SG_ CHSKM_POD_StatusDCDC2 : 7|8@0+ (1,0) [0|255] "" MHU
  SG_ ALV_POD_StatusDCDC2 : 11|4@0+ (1,0) [0|14] "" MHU
  SG_ POD_vDCInput : 23|16@0+ (0.0625,0) [0|512] "V" MHU
  SG_ POD_iDCDCOutput : 39|16@0+ (0.0625,0) [0|300] "A" MHU
  SG_ POD_vDCDCOutput : 55|16@0+ (0.0625,0) [0|18] "V" MHU

BO_ 840 EDS_Sts_FR: 8 XGW_Info
  SG_ EDS_HVIL_STS_FWD : 25|2@0+ (1,0) [0|3] "" MHU

BO_ 841 EDS_R_Sts_RR: 8 XGW_Info
  SG_ EDS_HVIL_STS_RWD : 25|2@0+ (1,0) [0|3] "" MHU

BO_ 842 Camera_Object03: 8 ADAS_Info
  SG_ SECCAN_Cam_OBJ_3 : 7|8@0+ (1,0) [0|255] "" MHU
  SG_ ADAS_OBJ03_Class : 18|3@0+ (1,0) [0|7] "-" MHU
  SG_ ADAS_OBJ03_LgtDis : 29|14@0+ (0.025,-10) [-10|399.575] "-" MHU
  SG_ ADAS_OBJ03_ID : 47|8@0+ (1,0) [0|255] "-" MHU
  SG_ ADAS_OBJ03_LatDis : 49|10@0+ (0.0293,-15.0146) [-15.0146|14.985] "-" MHU
  SG_ ADAS_OBJ03_Lane : 55|3@0+ (1,0) [0|7] "-" MHU

BO_ 844 Camera_Object04: 8 ADAS_Info
  SG_ SECCAN_Cam_OBJ_4 : 7|8@0+ (1,0) [0|255] "" MHU
  SG_ ADAS_OBJ04_Class : 18|3@0+ (1,0) [0|7] "-" MHU
  SG_ ADAS_OBJ04_LgtDis : 29|14@0+ (0.025,-10) [-10|399.575] "-" MHU
  SG_ ADAS_OBJ04_ID : 47|8@0+ (1,0) [0|255] "-" MHU
  SG_ ADAS_OBJ04_LatDis : 49|10@0+ (0.0293,-15.0146) [-15.0146|14.985] "-" MHU
  SG_ ADAS_OBJ04_Lane : 55|3@0+ (1,0) [0|7] "-" MHU

BO_ 845 Camera_Object05: 8 ADAS_Info
  SG_ SECCAN_Cam_OBJ_5 : 7|8@0+ (1,0) [0|255] "" MHU
  SG_ ADAS_OBJ05_Class : 18|3@0+ (1,0) [0|7] "-" MHU
  SG_ ADAS_OBJ05_LgtDis : 29|14@0+ (0.025,-10) [-10|399.575] "-" MHU
  SG_ ADAS_OBJ05_ID : 47|8@0+ (1,0) [0|255] "-" MHU
  SG_ ADAS_OBJ05_LatDis : 49|10@0+ (0.0293,-15.0146) [-15.0146|14.985] "-" MHU
  SG_ ADAS_OBJ05_Lane : 55|3@0+ (1,0) [0|7] "-" MHU

BO_ 846 Camera_Object06: 8 ADAS_Info
  SG_ SECCAN_Cam_OBJ_6 : 7|8@0+ (1,0) [0|255] "" MHU
  SG_ ADAS_OBJ06_Class : 18|3@0+ (1,0) [0|7] "-" MHU
  SG_ ADAS_OBJ06_LgtDis : 29|14@0+ (0.025,-10) [-10|399.575] "-" MHU
  SG_ ADAS_OBJ06_ID : 47|8@0+ (1,0) [0|255] "-" MHU
  SG_ ADAS_OBJ06_LatDis : 49|10@0+ (0.0293,-15.0146) [-15.0146|14.985] "-" MHU
  SG_ ADAS_OBJ06_Lane : 55|3@0+ (1,0) [0|7] "-" MHU

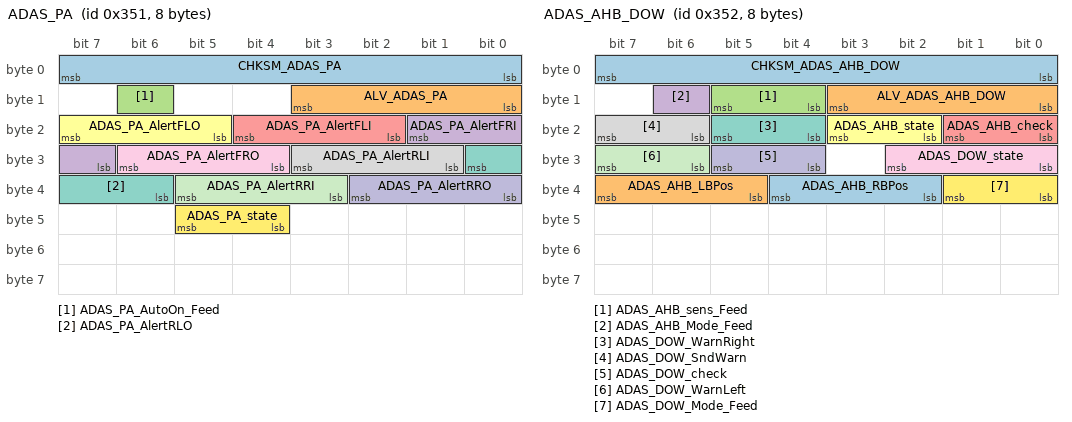
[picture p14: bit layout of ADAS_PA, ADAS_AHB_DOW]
BO_ 849 ADAS_PA: 8 ADAS_Info
  SG_ CHKSM_ADAS_PA : 7|8@0+ (1,0) [0|255] "" HUD,MHU
  SG_ ALV_ADAS_PA : 11|4@0+ (1,0) [0|14] "" HUD,MHU
  SG_ ADAS_PA_AutoOn_Feed : 14|1@0+ (1,0) [0|1] "-" HUD,MHU
  SG_ ADAS_PA_AlertFRI : 17|3@0+ (1,0) [0|7] "-" HUD,MHU
  SG_ ADAS_PA_AlertFLI : 20|3@0+ (1,0) [0|7] "-" HUD,MHU
  SG_ ADAS_PA_AlertFLO : 23|3@0+ (1,0) [0|7] "-" HUD,MHU
  SG_ ADAS_PA_AlertRLO : 24|3@0+ (1,0) [0|7] "-" HUD,MHU
  SG_ ADAS_PA_AlertRLI : 27|3@0+ (1,0) [0|7] "-" HUD,MHU
  SG_ ADAS_PA_AlertFRO : 30|3@0+ (1,0) [0|7] "-" HUD,MHU
  SG_ ADAS_PA_AlertRRO : 34|3@0+ (1,0) [0|7] "-" HUD,MHU
  SG_ ADAS_PA_AlertRRI : 37|3@0+ (1,0) [0|7] "-" HUD,MHU
  SG_ ADAS_PA_state : 45|2@0+ (1,0) [0|3] "-" HUD,MHU

BO_ 850 ADAS_AHB_DOW: 8 ADAS_Info
  SG_ CHKSM_ADAS_AHB_DOW : 7|8@0+ (1,0) [0|255] "" HUD,MHU
  SG_ ALV_ADAS_AHB_DOW : 11|4@0+ (1,0) [0|14] "" HUD,MHU
  SG_ ADAS_AHB_sens_Feed : 13|2@0+ (1,0) [0|3] "-" MHU
  SG_ ADAS_AHB_Mode_Feed : 14|1@0+ (1,0) [0|1] "-" MHU
  SG_ ADAS_AHB_check : 17|2@0+ (1,0) [0|3] "-" MHU
  SG_ ADAS_AHB_state : 19|2@0+ (1,0) [0|3] "-" MHU
  SG_ ADAS_DOW_WarnRight : 21|2@0+ (1,0) [0|3] "-" MHU
  SG_ ADAS_DOW_SndWarn : 23|2@0+ (1,0) [0|3] "-" MHU
  SG_ ADAS_DOW_state : 26|3@0+ (1,0) [0|7] "-" MHU
  SG_ ADAS_DOW_check : 29|2@0+ (1,0) [0|3] "-" MHU
  SG_ ADAS_DOW_WarnLeft : 31|2@0+ (1,0) [0|3] "-" MHU
  SG_ ADAS_DOW_Mode_Feed : 33|2@0+ (1,0) [0|3] "-" MHU
  SG_ ADAS_AHB_RBPos : 36|3@0+ (1,0) [0|7] "" MHU
  SG_ ADAS_AHB_LBPos : 39|3@0+ (1,0) [0|7] "-" MHU

BO_ 851 ADAS_CMP_ACC: 8 ADAS_Info
  SG_ CHKSM_ADAS_ACC : 7|8@0+ (1,0) [0|255] "" HUD,MHU
  SG_ ALV_ADAS_ACC : 11|4@0+ (1,0) [0|14] "" HUD,MHU
  SG_ ADAS_ACC_ObjDetec : 12|1@0+ (1,0) [0|1] "-" HUD,MHU
  SG_ ADAS_ISA_check : 14|2@0+ (1,0) [0|3] "-" HUD,MHU
  SG_ ADAS_ISA_Mode_SW_Feed : 15|1@0+ (1,0) [0|1] "-" HUD,MHU
  SG_ ADAS_TagSpeed_ICON_Feed : 18|3@0+ (1,0) [0|7] "-" HUD,MHU
  SG_ ADAS_ISA_PopUp_Feed : 23|4@0+ (1,0) [0|15] "-" HUD,MHU
  SG_ ADAS_ISA_Btn_Feed : 24|1@0+ (1,0) [0|1] "-" HUD,MHU
  SG_ ADAS_ACC_DistSet_upper_Feed : 25|1@0+ (1,0) [0|1] "-" HUD,MHU
  SG_ ADAS_ACC_TimeGapSet : 28|3@0+ (1,0) [0|7] "-" HUD,MHU
  SG_ ADAS_ACC_State : 31|3@0+ (1,0) [0|7] "-" HUD,MHU
  SG_ ADAS_ACC_TagSpeed : 39|8@0+ (1,0) [0|255] "km/h" HUD,MHU
  SG_ ADAS_ACC_PopUp_Feed : 43|4@0+ (1,0) [0|15] "-" HUD,MHU
  SG_ ADAS_ACC_check : 47|2@0+ (1,0) [0|3] "-" HUD,MHU
  SG_ ADAS_ISA_ICON_Feed : 50|3@0+ (1,0) [0|7] "-" HUD,MHU
  SG_ ADAS_ACC_DistSet_lower_Feed : 51|1@0+ (1,0) [0|1] "-" HUD,MHU
  SG_ ADAS_ACC_SpdSet_upper_Feed : 52|1@0+ (1,0) [0|1] "-" HUD,MHU
  SG_ ADAS_ACC_SpdSet_lower_Feed : 53|1@0+ (1,0) [0|1] "-" HUD,MHU
  SG_ ADAS_ACC_On_Feed : 54|1@0+ (1,0) [0|1] "-" HUD,MHU
  SG_ ADAS_ACC_Set_Feed : 55|1@0+ (1,0) [0|1] "-" HUD,MHU
  SG_ ADAS_ACC_CnlBtn_Feed : 56|1@0+ (1,0) [0|1] "-" HUD,MHU
  SG_ ADAS_ACC_Res_Feed : 57|1@0+ (1,0) [0|1] "-" HUD,MHU
  SG_ ADAS_ACC_ICON_Feed : 60|3@0+ (1,0) [0|7] "-" HUD,MHU
  SG_ ADAS_ISA_Status : 63|3@0+ (1,0) [0|7] "-" HUD,MHU

BO_ 852 MHU_ADAS_req: 8 MHU
  SG_ MHU_FCW_Mode : 1|2@0+ (1,0) [0|3] "-" ADAS_Info
  SG_ MHU_FCW_sens : 3|2@0+ (1,0) [0|3] "-" ADAS_Info
  SG_ MHU_AEB_Mode : 7|2@0+ (1,0) [0|3] "-" ADAS_Info
  SG_ MHU_RAEB_Mode : 9|2@0+ (1,0) [0|3] "-" ADAS_Info
  SG_ MHU_LA_sens : 11|2@0+ (1,0) [0|3] "-" ADAS_Info
  SG_ MHU_LA_AudWarning : 15|2@0+ (1,0) [0|3] "-" ADAS_Info
  SG_ MHU_BSD_On : 17|2@0+ (1,0) [0|3] "-" ADAS_Info
  SG_ MHU_ALC_ON : 19|2@0+ (1,0) [0|3] "-" ADAS_Info
  SG_ MHU_BSD_AudWarning : 21|2@0+ (1,0) [0|3] "-" ADAS_Info
  SG_ MHU_RCTA_On : 23|2@0+ (1,0) [0|3] "-" ADAS_Info
  SG_ MHU_RCTA_sens : 25|2@0+ (1,0) [0|3] "-" ADAS_Info
  SG_ MHU_PA_On : 27|2@0+ (1,0) [0|3] "-" ADAS_Info
  SG_ MHU_AHB_On : 29|2@0+ (1,0) [0|3] "-" ADAS_Info
  SG_ MHU_IA_Mode : 31|2@0+ (1,0) [0|3] "-" ADAS_Info
  SG_ MHU_TSR_Mode : 33|2@0+ (1,0) [0|3] "-" ADAS_Info
  SG_ MHU_DOW_Mode : 35|2@0+ (1,0) [0|3] "-" ADAS_Info
  SG_ MHU_AHB_sens : 37|2@0+ (1,0) [0|3] "-" ADAS_Info
  SG_ MHU_LA_Mode : 41|3@0+ (1,0) [0|7] "-" ADAS_Info
  SG_ MHU_SET_TSR_AudWarn : 45|2@0+ (1,0) [0|3] "-" ADAS_Info
  SG_ MHU_SET_TSR_SLAert : 47|2@0+ (1,0) [0|3] "-" ADAS_Info

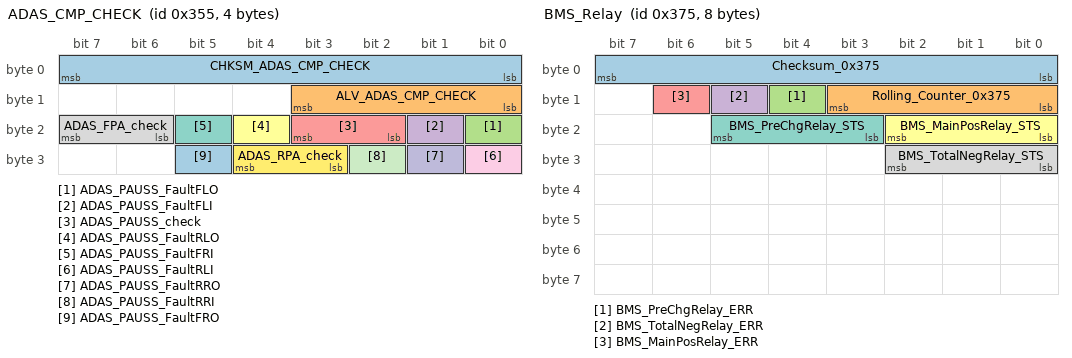
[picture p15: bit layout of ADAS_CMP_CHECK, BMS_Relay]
BO_ 853 ADAS_CMP_CHECK: 4 ADAS_Info
  SG_ CHKSM_ADAS_CMP_CHECK : 7|8@0+ (1,0) [0|255] "" MHU
  SG_ ALV_ADAS_CMP_CHECK : 11|4@0+ (1,0) [0|14] "" MHU
  SG_ ADAS_PAUSS_FaultFLO : 16|1@0+ (1,0) [0|1] "-" MHU
  SG_ ADAS_PAUSS_FaultFLI : 17|1@0+ (1,0) [0|1] "-" MHU
  SG_ ADAS_PAUSS_check : 19|2@0+ (1,0) [0|3] "-" MHU
  SG_ ADAS_PAUSS_FaultRLO : 20|1@0+ (1,0) [0|1] "-" MHU
  SG_ ADAS_PAUSS_FaultFRI : 21|1@0+ (1,0) [0|1] "-" MHU
  SG_ ADAS_FPA_check : 23|2@0+ (1,0) [0|3] "-" MHU
  SG_ ADAS_PAUSS_FaultRLI : 24|1@0+ (1,0) [0|1] "-" MHU
  SG_ ADAS_PAUSS_FaultRRO : 25|1@0+ (1,0) [0|1] "-" MHU
  SG_ ADAS_PAUSS_FaultRRI : 26|1@0+ (1,0) [0|1] "-" MHU
  SG_ ADAS_RPA_check : 28|2@0+ (1,0) [0|3] "-" MHU
  SG_ ADAS_PAUSS_FaultFRO : 29|1@0+ (1,0) [0|1] "-" MHU

BO_ 880 MHU_SBR_Status: 8 MHU
  SG_ CRC_MHU_SBR_Status : 7|8@0+ (1,0) [0|255] "" XGW_Info
  SG_ ALV_MHU_SBR_Status : 11|4@0+ (1,0) [0|14] "" XGW_Info
  SG_ SBR_STAT_Chime : 13|2@0+ (1,0) [0|3] "" XGW_Info
  SG_ SBR_STAT_Telltale : 15|2@0+ (1,0) [0|3] "" XGW_Info
  SG_ SBR_STAT_Active : 16|1@0+ (1,0) [0|1] "" XGW_Info

BO_ 885 BMS_Relay: 8 XGW_Info
  SG_ Checksum_0x375 : 7|8@0+ (1,0) [0|255] "" MHU
  SG_ Rolling_Counter_0x375 : 11|4@0+ (1,0) [0|14] "" MHU
  SG_ BMS_PreChgRelay_ERR : 12|1@0+ (1,0) [0|1] "" MHU
  SG_ BMS_TotalNegRelay_ERR : 13|1@0+ (1,0) [0|1] "" MHU
  SG_ BMS_MainPosRelay_ERR : 14|1@0+ (1,0) [0|1] "" MHU
  SG_ BMS_MainPosRelay_STS : 18|3@0+ (1,0) [0|7] "" MHU
  SG_ BMS_PreChgRelay_STS : 21|3@0+ (1,0) [0|7] "" MHU
  SG_ BMS_TotalNegRelay_STS : 26|3@0+ (1,0) [0|7] "" MHU

BO_ 896 BCM_VEHICLE_IDENT_NUMBER: 8 XGW_Info
  SG_ VIN_Byte1 : 7|8@0+ (1,0) [0|255] "" ADAS_Info,AMP,CPD,EASC,HUD,MHU
  SG_ VIN_Byte2 : 15|8@0+ (1,0) [0|255] "" ADAS_Info,AMP,CPD,EASC,HUD,MHU
  SG_ VIN_Byte3 : 23|8@0+ (1,0) [0|255] "" ADAS_Info,AMP,CPD,EASC,HUD,MHU
  SG_ VIN_Byte4 : 31|8@0+ (1,0) [0|255] "" ADAS_Info,AMP,CPD,EASC,HUD,MHU
  SG_ VIN_Byte5 : 39|8@0+ (1,0) [0|255] "" ADAS_Info,AMP,CPD,EASC,HUD,MHU
  SG_ VIN_Byte6 : 47|8@0+ (1,0) [0|255] "" ADAS_Info,AMP,CPD,EASC,HUD,MHU
  SG_ VIN_Byte7 : 55|8@0+ (1,0) [0|255] "" ADAS_Info,AMP,CPD,EASC,HUD,MHU

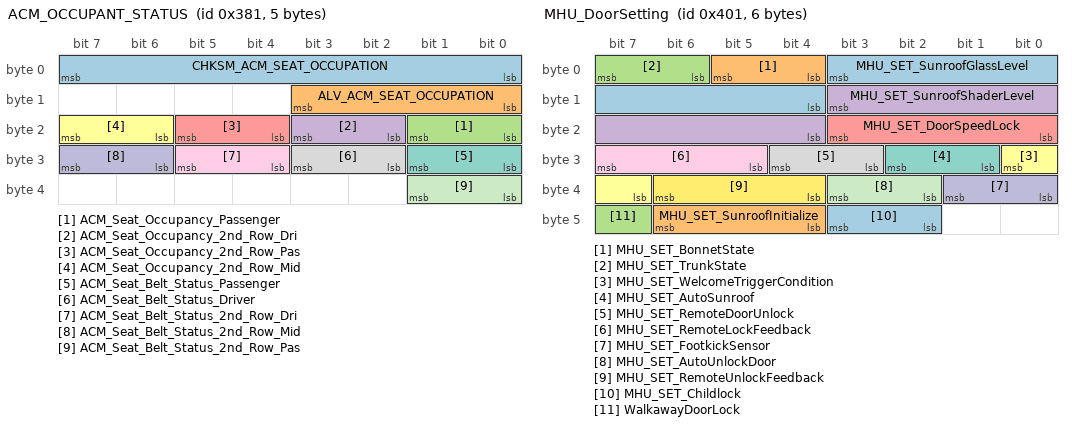
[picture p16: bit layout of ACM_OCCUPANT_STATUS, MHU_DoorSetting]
BO_ 897 ACM_OCCUPANT_STATUS: 5 XGW_Info
  SG_ CHKSM_ACM_SEAT_OCCUPATION : 7|8@0+ (1,0) [0|255] "" MHU
  SG_ ALV_ACM_SEAT_OCCUPATION : 11|4@0+ (1,0) [0|14] "" MHU
  SG_ ACM_Seat_Occupancy_Passenger : 17|2@0+ (1,0) [0|3] "" MHU
  SG_ ACM_Seat_Occupancy_2nd_Row_Dri : 19|2@0+ (1,0) [0|3] "" MHU
  SG_ ACM_Seat_Occupancy_2nd_Row_Pas : 21|2@0+ (1,0) [0|3] "-" MHU
  SG_ ACM_Seat_Occupancy_2nd_Row_Mid : 23|2@0+ (1,0) [0|3] "-" MHU
  SG_ ACM_Seat_Belt_Status_Passenger : 25|2@0+ (1,0) [0|3] "" MHU
  SG_ ACM_Seat_Belt_Status_Driver : 27|2@0+ (1,0) [0|3] "" MHU
  SG_ ACM_Seat_Belt_Status_2nd_Row_Dri : 29|2@0+ (1,0) [0|3] "-" MHU
  SG_ ACM_Seat_Belt_Status_2nd_Row_Mid : 31|2@0+ (1,0) [0|3] "" MHU
  SG_ ACM_Seat_Belt_Status_2nd_Row_Pas : 33|2@0+ (1,0) [0|3] "-" MHU

BO_ 905 VCU_Sts3: 8 XGW_Info
  SG_ VCU_IMMO_Sts : 35|2@0+ (1,0) [0|3] "" MHU
  SG_ SECCAN_VCU_IMMO_Sts : 63|8@0+ (1,0) [0|255] "" Vector__XXX

BO_ 915 MHU_HudPositionSetting: 3 MHU
  SG_ MHU_SET_HudRotateLvl : 7|4@0+ (1,0) [0|15] "-" HUD
  SG_ MHU_SET_HudHeightLvl : 15|5@0+ (1,0) [0|31] "-" HUD

BO_ 919 MHU_Auth_Immo_ADAS: 8 MHU
  SG_ MHU_Immo_ADAS_Byte_0 : 7|8@0+ (1,0) [0|255] "-" ADAS_Info
  SG_ MHU_Immo_ADAS_Byte_1 : 15|8@0+ (1,0) [0|255] "-" ADAS_Info
  SG_ MHU_Immo_ADAS_Byte_2 : 23|8@0+ (1,0) [0|255] "-" ADAS_Info
  SG_ MHU_Immo_ADAS_Byte_3 : 31|8@0+ (1,0) [0|255] "-" ADAS_Info
  SG_ MHU_Immo_ADAS_Byte_4 : 39|8@0+ (1,0) [0|255] "-" ADAS_Info
  SG_ MHU_Immo_ADAS_Byte_5 : 47|8@0+ (1,0) [0|255] "-" ADAS_Info
  SG_ MHU_Immo_ADAS_Byte_6 : 55|8@0+ (1,0) [0|255] "-" ADAS_Info
  SG_ MHU_Immo_ADAS_Byte_7 : 63|8@0+ (1,0) [0|255] "-" ADAS_Info

BO_ 922 MHU_Auth_Immo: 8 MHU
  SG_ MHU_Immo_Byte_0 : 7|8@0+ (1,0) [0|255] "-" XGW_Info
  SG_ MHU_Immo_Byte_1 : 15|8@0+ (1,0) [0|255] "-" XGW_Info
  SG_ MHU_Immo_Byte_2 : 23|8@0+ (1,0) [0|255] "" XGW_Info
  SG_ MHU_Immo_Byte_3 : 31|8@0+ (1,0) [0|255] "" XGW_Info
  SG_ MHU_Immo_Byte_4 : 39|8@0+ (1,0) [0|255] "" XGW_Info
  SG_ MHU_Immo_Byte_5 : 47|8@0+ (1,0) [0|255] "" XGW_Info
  SG_ MHU_Immo_Byte_6 : 55|8@0+ (1,0) [0|255] "" XGW_Info
  SG_ MHU_Immo_Byte_7 : 63|8@0+ (1,0) [0|255] "-" XGW_Info

BO_ 923 BCM_Immo_MHU_Byte_0: 8 XGW_Info
  SG_ BCM_Immo_MHU_Byte_0 : 7|8@0+ (1,0) [0|255] "-" MHU
  SG_ BCM_Immo_MHU_Byte_1 : 15|8@0+ (1,0) [0|255] "-" MHU
  SG_ BCM_Immo_MHU_Byte_2 : 23|8@0+ (1,0) [0|255] "-" MHU
  SG_ BCM_Immo_MHU_Byte_3 : 31|8@0+ (1,0) [0|255] "-" MHU
  SG_ BCM_Immo_MHU_Byte_4 : 39|8@0+ (1,0) [0|255] "-" MHU
  SG_ BCM_Immo_MHU_Byte_5 : 47|8@0+ (1,0) [0|255] "" MHU
  SG_ BCM_Immo_MHU_Byte_6 : 55|8@0+ (1,0) [0|255] "-" MHU
  SG_ BCM_Immo_MHU_Byte_7 : 63|8@0+ (1,0) [0|255] "-" MHU

BO_ 925 BCM_HighBeam_PosReq: 4 XGW_Info
  SG_ BCM_AHB_Override : 17|2@0+ (1,0) [0|3] "" MHU

BO_ 943 MHU_HUD_BASE: 8 MHU
  SG_ MHU_UTF8Character_Byte1 : 7|8@0+ (1,0) [0|255] "-" HUD
  SG_ MHU_UTF8Character_Byte2 : 15|8@0+ (1,0) [0|255] "-" HUD
  SG_ MHU_UTF8Character_Byte3 : 23|8@0+ (1,0) [0|255] "-" HUD
  SG_ MHU_UTF8Character_Byte4 : 31|8@0+ (1,0) [0|255] "-" HUD
  SG_ MHU_UTF8Character_Byte5 : 39|8@0+ (1,0) [0|255] "-" HUD
  SG_ MHU_UTF8Character_Byte6 : 47|8@0+ (1,0) [0|255] "-" HUD
  SG_ MHU_IPC_ID : 50|5@0+ (1,0) [0|15] "Bit" HUD
  SG_ MHU_TotalMessages : 55|5@0+ (1,0) [0|31] "-" HUD
  SG_ MHU_MessageNumber : 61|5@0+ (1,0) [0|31] "-" HUD

BO_ 964 MHU_HUD_NAV_DISP: 8 MHU
  SG_ MHU_Nav_State : 4|3@0+ (1,0) [0|7] "-" HUD
  SG_ MHU_NavSource : 7|3@0+ (1,0) [0|7] "-" HUD
  SG_ MHU_Nav_DistanceToNextTurn : 15|16@0+ (1,0) [0|65535] "-" HUD
  SG_ MHU_Nav_DistanceToNextTurnUnits : 31|3@0+ (1,0) [0|7] "-" HUD
  SG_ MHU_Nav_TBT_Icon : 39|8@0+ (1,0) [0|255] "-" HUD
  SG_ MHU_Nav_ImageChannel_Ready : 47|2@0+ (1,0) [0|3] "-" HUD
  SG_ MHU_Nav_Language : 55|8@0+ (1,0) [0|255] "" HUD
  SG_ SECCAN_NAV_DISP : 63|8@0+ (1,0) [0|255] "" HUD

BO_ 965 MHU_HUD_NAV_GuidanceCont: 8 MHU
  SG_ MHU_NavGuidance_TotalMsg : 7|5@0+ (1,0) [0|31] "-" HUD
  SG_ MHU_NavGuidance_MsgNum : 15|5@0+ (1,0) [0|31] "-" HUD
  SG_ MHU_NavGuidance_UTF8_Byte1 : 23|8@0+ (1,0) [0|255] "" HUD
  SG_ MHU_NavGuidance_UTF8_Byte2 : 31|8@0+ (1,0) [0|255] "" HUD
  SG_ MHU_NavGuidance_UTF8_Byte3 : 39|8@0+ (1,0) [0|255] "" HUD
  SG_ MHU_NavGuidance_UTF8_Byte4 : 47|8@0+ (1,0) [0|255] "" HUD
  SG_ MHU_NavGuidance_UTF8_Byte5 : 55|8@0+ (1,0) [0|255] "" HUD
  SG_ MHU_NavGuidance_UTF8_Byte6 : 63|8@0+ (1,0) [0|255] "" HUD

BO_ 966 MHU_NAV_GuidanceDist: 8 MHU
  SG_ MHU_NavDist_MsgNum : 7|5@0+ (1,0) [0|31] "" HUD
  SG_ MHU_NavDist_TotalMsg : 15|5@0+ (1,0) [0|31] "" HUD
  SG_ MHU_NavDist_UTF8_Byte1 : 23|8@0+ (1,0) [0|255] "" HUD
  SG_ MHU_NavDist_UTF8_Byte2 : 31|8@0+ (1,0) [0|255] "" HUD
  SG_ MHU_NavDist_UTF8_Byte3 : 39|8@0+ (1,0) [0|255] "" HUD
  SG_ MHU_NavDist_UTF8_Byte4 : 47|8@0+ (1,0) [0|255] "" HUD
  SG_ MHU_NavDist_UTF8_Byte5 : 55|8@0+ (1,0) [0|255] "" HUD
  SG_ MHU_NavDist_UTF8_Byte6 : 63|8@0+ (1,0) [0|255] "" HUD

BO_ 992 VCU_HVsystem_status: 8 XGW_Info
  SG_ CRC_VCU_HVsystem_status : 7|8@0+ (1,0) [0|255] "" HUD,MHU
  SG_ ALIV_VCU_HVsystem_status : 11|4@0+ (1,0) [0|14] "" HUD,MHU
  SG_ VCU_RunningRange : 23|12@0+ (0.5,0) [0|2047] "km" HUD,MHU
  SG_ VCU_RunningRange_chrg_estSts : 27|2@0+ (1,0) [0|3] "-" HUD,MHU
  SG_ VCU_RunningRange_charged : 39|12@0+ (0.5,0) [0|2047] "km" HUD,MHU
  SG_ VCU_HVbatSoc_charged : 55|10@0+ (0.1,0) [0|100] "%" HUD,MHU
  SG_ VCU_HVbatSoc_charged_estStatus : 61|2@0+ (1,0) [0|3] "-" HUD,MHU

BO_ 993 VCU_HMI_Info: 8 XGW_Info
  SG_ CRC_VCU_HMI_Info : 7|8@0+ (1,0) [0|255] "" MHU
  SG_ ALIV_VCU_HMI_Info : 11|4@0+ (1,0) [0|14] "" MHU
  SG_ VCU_MHU_Ack_ChgSche_stt : 27|2@0+ (1,0) [0|3] "" MHU
  SG_ VCU_MHU_Ack_TargetSOC : 39|7@0+ (1,0) [10|100] "%" MHU
  SG_ VCU_ValetMode_sts : 47|8@0+ (1,0) [0|255] "" MHU
  SG_ VCU_ValetMode_MaxSpeedSts : 55|8@0+ (1,0) [0|255] "km/h" MHU
  SG_ SECCAN_VCU_HMI_Info : 63|8@0+ (1,0) [0|255] "" MHU

BO_ 1015 MFS_Control_Button: 8 XGW_Info
  SG_ CHSKM_MFS_Control_Button : 7|8@0+ (1,0) [0|255] "" ADAS_Info,HUD,MHU
  SG_ ALV_MFS_Control_Button : 11|4@0+ (1,0) [0|14] "" ADAS_Info,HUD,MHU
  SG_ MFS_VoiceRecognitionOn_Off : 15|3@0+ (1,0) [0|4] "Bit" HUD,MHU
  SG_ MFS_ISAControl : 17|2@0+ (1,0) [0|3] "Bit" ADAS_Info,HUD,MHU
  SG_ MFS_CruiseSpeedIncrease : 20|3@0+ (1,0) [0|4] "Bit" ADAS_Info,HUD,MHU
  SG_ MFS_TelephoneCall_EndCall : 23|3@0+ (1,0) [0|4] "Bit" HUD,MHU
  SG_ MFS_LKAControl : 25|2@0+ (1,0) [0|3] "Bit" ADAS_Info,HUD,MHU
  SG_ MFS_CruiseGapIncrease : 28|3@0+ (1,0) [0|4] "Bit" ADAS_Info,HUD,MHU
  SG_ MFS_CruiseOn_Off : 31|3@0+ (1,0) [0|4] "Bit" ADAS_Info,HUD,MHU
  SG_ MFS_CruiseGapDecrease : 34|3@0+ (1,0) [0|4] "Bit" ADAS_Info,HUD,MHU
  SG_ MFS_CAN_RESControl : 36|2@0+ (1,0) [0|3] "-" ADAS_Info,HUD
  SG_ MFS_CruiseSpeedDecrease : 39|3@0+ (1,0) [0|4] "Bit" ADAS_Info,HUD,MHU
  SG_ MFS_M2Control : 41|2@0+ (1,0) [0|3] "Bit" ADAS_Info,HUD
  SG_ MFS_SourseControl : 44|3@0+ (1,0) [0|4] "Bit" HUD,MHU
  SG_ MFS_UpControl : 47|3@0+ (1,0) [0|4] "Bit" EASC,HUD,MHU
  SG_ MFS_DownControl : 52|3@0+ (1,0) [0|4] "Bit" EASC,HUD,MHU
  SG_ MFS_LeftControl : 55|3@0+ (1,0) [0|4] "Bit" EASC,HUD,MHU
  SG_ MFS_Failure : 57|1@0+ (1,0) [0|1] "Bit" ADAS_Info,HUD,MHU
  SG_ MFS_RightControl : 60|3@0+ (1,0) [0|4] "Bit" EASC,HUD,MHU
  SG_ MFS_OK_Control : 63|3@0+ (1,0) [0|4] "Bit" HUD,MHU

BO_ 1020 XGW_FOTA_StsConfirm: 4 XGW_Info
  SG_ CRC_XGW_FOTA_StsConfirm : 7|8@0+ (1,0) [0|255] "" MHU
  SG_ ALIV_XGW_FOTA_StsConfirm : 11|4@0+ (1,0) [0|14] "" MHU
  SG_ XGW_FOTA_StateConfirm : 15|4@0+ (1,0) [0|14] "-" MHU
  SG_ XGW_FOTA_Error_Code : 23|8@0+ (1,0) [0|255] "-" MHU

BO_ 1025 MHU_DoorSetting: 6 MHU
  SG_ MHU_SET_SunroofGlassLevel : 3|8@0+ (1,0) [0|255] "%" XGW_Info
  SG_ MHU_SET_BonnetState : 5|2@0+ (1,0) [0|3] "-" XGW_Info
  SG_ MHU_SET_TrunkState : 7|2@0+ (1,0) [0|3] "-" XGW_Info
  SG_ MHU_SET_SunroofShaderLevel : 11|8@0+ (1,0) [0|255] "%" XGW_Info
  SG_ MHU_SET_DoorSpeedLock : 19|4@0+ (1,0) [0|7] "" XGW_Info
  SG_ MHU_SET_WelcomeTriggerCondition : 24|2@0+ (1,0) [0|3] "" XGW_Info
  SG_ MHU_SET_AutoSunroof : 26|2@0+ (1,0) [0|3] "" XGW_Info
  SG_ MHU_SET_RemoteDoorUnlock : 28|2@0+ (1,0) [0|3] "-" XGW_Info
  SG_ MHU_SET_RemoteLockFeedback : 31|3@0+ (1,0) [0|7] "-" XGW_Info
  SG_ MHU_SET_FootkickSensor : 33|2@0+ (1,0) [0|3] "-" XGW_Info
  SG_ MHU_SET_AutoUnlockDoor : 35|2@0+ (1,0) [0|3] "" XGW_Info
  SG_ MHU_SET_RemoteUnlockFeedback : 38|3@0+ (1,0) [0|7] "" XGW_Info
  SG_ MHU_SET_Childlock : 43|2@0+ (1,0) [0|3] "" XGW_Info
  SG_ MHU_SET_SunroofInitialize : 46|3@0+ (1,0) [0|7] "" XGW_Info
  SG_ WalkawayDoorLock : 47|1@0+ (1,0) [0|1] "" XGW_Info

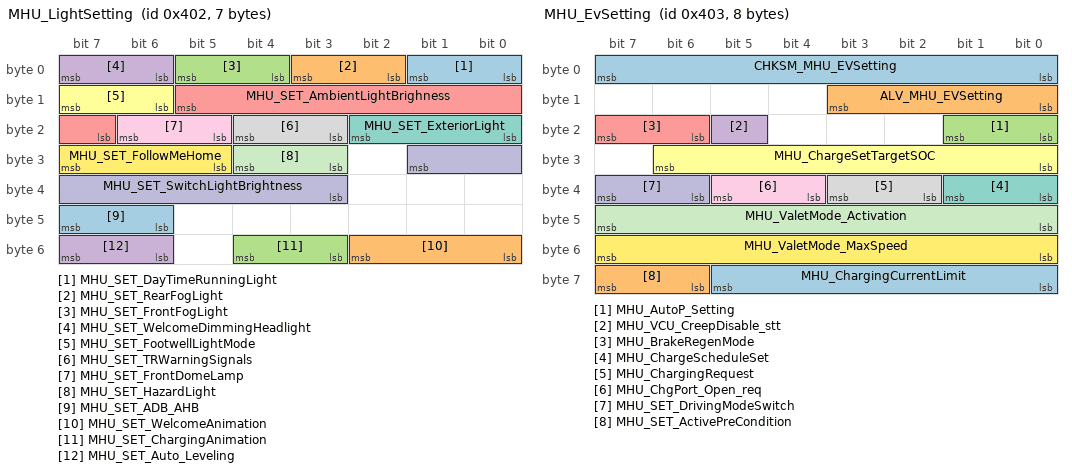
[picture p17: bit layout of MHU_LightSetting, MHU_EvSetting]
BO_ 1026 MHU_LightSetting: 7 MHU
  SG_ MHU_SET_DayTimeRunningLight : 1|2@0+ (1,0) [0|3] "-" XGW_Info
  SG_ MHU_SET_RearFogLight : 3|2@0+ (1,0) [0|3] "" XGW_Info
  SG_ MHU_SET_FrontFogLight : 5|2@0+ (1,0) [0|3] "" XGW_Info
  SG_ MHU_SET_WelcomeDimmingHeadlight : 7|2@0+ (1,0) [0|3] "" XGW_Info
  SG_ MHU_SET_AmbientLightBrighness : 13|7@0+ (1,0) [0|100] "%" XGW_Info
  SG_ MHU_SET_FootwellLightMode : 15|2@0+ (1,0) [0|3] "-" XGW_Info
  SG_ MHU_SET_ExteriorLight : 18|3@0+ (1,0) [0|7] "" XGW_Info
  SG_ MHU_SET_TRWarningSignals : 20|2@0+ (1,0) [0|3] "" XGW_Info
  SG_ MHU_SET_FrontDomeLamp : 22|2@0+ (1,0) [0|3] "" XGW_Info
  SG_ MHU_SET_SwitchLightBrightness : 25|7@0+ (1,0) [0|100] "%" XGW_Info
  SG_ MHU_SET_HazardLight : 28|2@0+ (1,0) [0|3] "" XGW_Info
  SG_ MHU_SET_FollowMeHome : 31|3@0+ (1,0) [0|7] "" XGW_Info
  SG_ MHU_SET_ADB_AHB : 47|2@0+ (1,0) [0|3] "" XGW_Info
  SG_ MHU_SET_WelcomeAnimation : 50|3@0+ (1,0) [0|5] "" XGW_Info
  SG_ MHU_SET_ChargingAnimation : 52|2@0+ (1,0) [0|3] "" XGW_Info
  SG_ MHU_SET_Auto_Leveling : 55|2@0+ (1,0) [0|3] "-" XGW_Info

BO_ 1027 MHU_EvSetting: 8 MHU
  SG_ CHKSM_MHU_EVSetting : 7|8@0+ (1,0) [0|255] "" XGW_Info
  SG_ ALV_MHU_EVSetting : 11|4@0+ (1,0) [0|14] "" XGW_Info
  SG_ MHU_AutoP_Setting : 17|2@0+ (1,0) [0|3] "" XGW_Info
  SG_ MHU_VCU_CreepDisable_stt : 21|1@0+ (1,0) [0|1] "" XGW_Info
  SG_ MHU_BrakeRegenMode : 23|2@0+ (1,0) [0|3] "" XGW_Info
  SG_ MHU_ChargeSetTargetSOC : 30|7@0+ (1,0) [10|100] "%" XGW_Info
  SG_ MHU_ChargeScheduleSet : 33|2@0+ (1,0) [0|3] "" XGW_Info
  SG_ MHU_ChargingRequest : 35|2@0+ (1,0) [0|3] "-" XGW_Info
  SG_ MHU_ChgPort_Open_req : 37|2@0+ (1,0) [0|3] "-" XGW_Info
  SG_ MHU_SET_DrivingModeSwitch : 39|2@0+ (1,0) [0|3] "-" XGW_Info
  SG_ MHU_ValetMode_Activation : 47|8@0+ (1,0) [0|255] "" ADAS_Info,XGW_Info
  SG_ MHU_ValetMode_MaxSpeed : 55|8@0+ (1,0) [0|255] "km/h" XGW_Info
  SG_ MHU_ChargingCurrentLimit : 61|6@0+ (1,0) [0|63] "A" XGW_Info
  SG_ MHU_SET_ActivePreCondition : 63|2@0+ (1,0) [0|3] "" XGW_Info

BO_ 1028 MHU_MirrorAdjust: 8 MHU
  SG_ MHU_SET_LeftMirrorPosX : 7|8@0+ (1,-15) [-15|15] "deg" XGW_Info
  SG_ MHU_SET_LeftMirrorPosY : 15|8@0+ (1,-15) [-15|15] "deg" XGW_Info
  SG_ MHU_SET_RightMirrorPosX : 23|8@0+ (1,-15) [-15|15] "deg" XGW_Info
  SG_ MHU_SET_RightMirrorPosY : 31|8@0+ (1,-15) [-15|15] "deg" XGW_Info
  SG_ MHU_SET_MirrorAdjustLeft : 39|2@0+ (1,0) [0|3] "-" XGW_Info
  SG_ MHU_SET_MirrorAdjustRight : 41|2@0+ (1,0) [0|3] "-" XGW_Info
  SG_ MHU_SET_MirrorManual : 43|2@0+ (1,0) [0|3] "" XGW_Info
  SG_ SECCAN_MirrorAdj : 63|8@0+ (1,0) [0|255] "" XGW_Info

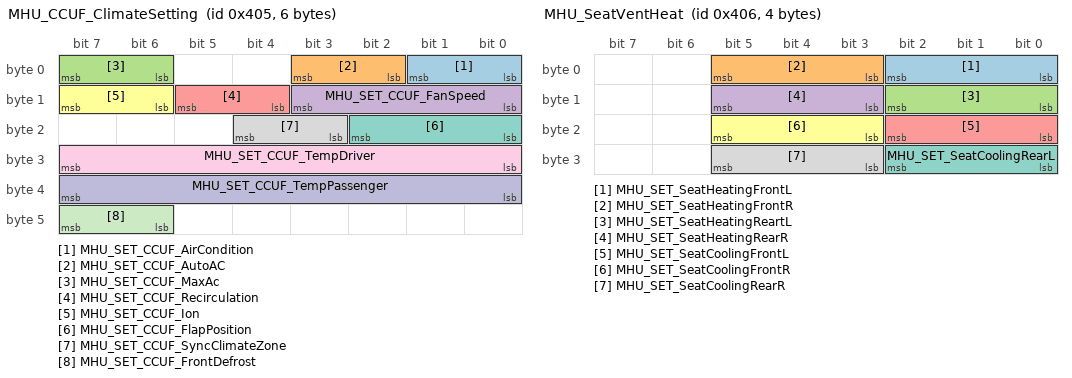
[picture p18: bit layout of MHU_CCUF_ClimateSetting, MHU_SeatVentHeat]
BO_ 1029 MHU_CCUF_ClimateSetting: 6 MHU
  SG_ MHU_SET_CCUF_AirCondition : 1|2@0+ (1,0) [0|3] "" XGW_Info
  SG_ MHU_SET_CCUF_AutoAC : 3|2@0+ (1,0) [0|3] "" XGW_Info
  SG_ MHU_SET_CCUF_MaxAc : 7|2@0+ (1,0) [0|3] "" XGW_Info
  SG_ MHU_SET_CCUF_FanSpeed : 11|4@0+ (1,0) [0|7] "-" XGW_Info
  SG_ MHU_SET_CCUF_Recirculation : 13|2@0+ (1,0) [0|3] "" XGW_Info
  SG_ MHU_SET_CCUF_Ion : 15|2@0+ (1,0) [0|3] "-" XGW_Info
  SG_ MHU_SET_CCUF_FlapPosition : 18|3@0+ (1,0) [0|7] "-" XGW_Info
  SG_ MHU_SET_CCUF_SyncClimateZone : 20|2@0+ (1,0) [0|3] "-" XGW_Info
  SG_ MHU_SET_CCUF_TempDriver : 31|8@0+ (0.5,0) [16|32] "Degree C" XGW_Info
  SG_ MHU_SET_CCUF_TempPassenger : 39|8@0+ (0.5,0) [16|32] "Degree C" XGW_Info
  SG_ MHU_SET_CCUF_FrontDefrost : 47|2@0+ (1,0) [0|3] "" XGW_Info

BO_ 1030 MHU_SeatVentHeat: 4 MHU
  SG_ MHU_SET_SeatHeatingFrontL : 2|3@0+ (1,0) [0|7] "-" XGW_Info
  SG_ MHU_SET_SeatHeatingFrontR : 5|3@0+ (1,0) [0|7] "-" XGW_Info
  SG_ MHU_SET_SeatHeatingReartL : 10|3@0+ (1,0) [0|7] "-" XGW_Info
  SG_ MHU_SET_SeatHeatingRearR : 13|3@0+ (1,0) [0|7] "-" XGW_Info
  SG_ MHU_SET_SeatCoolingFrontL : 18|3@0+ (1,0) [0|7] "-" XGW_Info
  SG_ MHU_SET_SeatCoolingFrontR : 21|3@0+ (1,0) [0|7] "" XGW_Info
  SG_ MHU_SET_SeatCoolingRearL : 26|3@0+ (1,0) [0|7] "" XGW_Info
  SG_ MHU_SET_SeatCoolingRearR : 29|3@0+ (1,0) [0|7] "-" XGW_Info

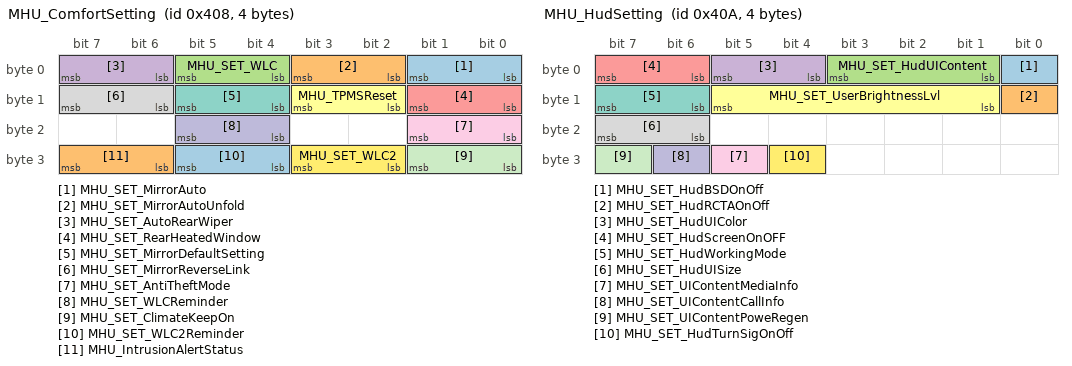
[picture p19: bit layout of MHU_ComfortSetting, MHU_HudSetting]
BO_ 1032 MHU_ComfortSetting: 4 MHU
  SG_ MHU_SET_MirrorAuto : 1|2@0+ (1,0) [0|3] "" XGW_Info
  SG_ MHU_SET_MirrorAutoUnfold : 3|2@0+ (1,0) [0|3] "" XGW_Info
  SG_ MHU_SET_WLC : 5|2@0+ (1,0) [0|3] "-" XGW_Info
  SG_ MHU_SET_AutoRearWiper : 7|2@0+ (1,0) [0|3] "-" XGW_Info
  SG_ MHU_SET_RearHeatedWindow : 9|2@0+ (1,0) [0|3] "" XGW_Info
  SG_ MHU_TPMSReset : 11|2@0+ (1,0) [0|3] "" XGW_Info
  SG_ MHU_SET_MirrorDefaultSetting : 13|2@0+ (1,0) [0|3] "" XGW_Info
  SG_ MHU_SET_MirrorReverseLink : 15|2@0+ (1,0) [0|3] "-" XGW_Info
  SG_ MHU_SET_AntiTheftMode : 17|2@0+ (1,0) [0|3] "" XGW_Info
  SG_ MHU_SET_WLCReminder : 21|2@0+ (1,0) [0|3] "" XGW_Info
  SG_ MHU_SET_ClimateKeepOn : 25|2@0+ (1,0) [0|3] "" XGW_Info
  SG_ MHU_SET_WLC2 : 27|2@0+ (1,0) [0|3] "-" XGW_Info
  SG_ MHU_SET_WLC2Reminder : 29|2@0+ (1,0) [0|3] "-" XGW_Info
  SG_ MHU_IntrusionAlertStatus : 31|2@0+ (1,0) [0|3] "-" XGW_Info

BO_ 1033 ADAS_WarnMsg: 8 ADAS_Info
  SG_ CHSKM_ADAS_WarnMsg : 7|8@0+ (1,0) [0|255] "" MHU
  SG_ ALV_ADAS_WarnMsg : 11|4@0+ (1,0) [0|14] "" MHU
  SG_ ADAS_Warning_Flag_1 : 12|1@0+ (1,0) [0|1] "" MHU
  SG_ ADAS_Warning_Flag_2 : 13|1@0+ (1,0) [0|1] "" MHU
  SG_ ADAS_Warning_Flag_3 : 14|1@0+ (1,0) [0|1] "" MHU
  SG_ ADAS_Warning_Flag_4 : 15|1@0+ (1,0) [0|1] "" MHU
  SG_ ADAS_Warning_Flag_5 : 16|1@0+ (1,0) [0|1] "" MHU
  SG_ ADAS_Warning_Flag_6 : 17|1@0+ (1,0) [0|1] "" MHU
  SG_ ADAS_Warning_Flag_7 : 18|1@0+ (1,0) [0|1] "" MHU
  SG_ ADAS_Warning_Flag_8 : 19|1@0+ (1,0) [0|1] "" MHU
  SG_ ADAS_Warning_Flag_9 : 20|1@0+ (1,0) [0|1] "" MHU
  SG_ ADAS_Warning_Flag_10 : 21|1@0+ (1,0) [0|1] "" MHU
  SG_ ADAS_Warning_Flag_11 : 22|1@0+ (1,0) [0|1] "" MHU
  SG_ ADAS_Warning_Flag_12 : 23|1@0+ (1,0) [0|1] "" MHU
  SG_ ADAS_Warning_Flag_13 : 24|1@0+ (1,0) [0|1] "" MHU
  SG_ ADAS_Warning_Flag_14 : 25|1@0+ (1,0) [0|1] "" MHU
  SG_ ADAS_Warning_Flag_15 : 26|1@0+ (1,0) [0|1] "" MHU
  SG_ ADAS_Warning_Flag_16 : 27|1@0+ (1,0) [0|1] "" MHU
  SG_ ADAS_Warning_Flag_17 : 28|1@0+ (1,0) [0|1] "" MHU
  SG_ ADAS_Warning_Flag_18 : 29|1@0+ (1,0) [0|1] "" MHU
  SG_ ADAS_Warning_Flag_19 : 30|1@0+ (1,0) [0|1] "" MHU
  SG_ ADAS_Warning_Flag_20 : 31|1@0+ (1,0) [0|1] "" MHU
  SG_ ADAS_Warning_Flag_21 : 32|1@0+ (1,0) [0|1] "" MHU
  SG_ ADAS_Warning_Flag_22 : 33|1@0+ (1,0) [0|1] "" MHU
  SG_ ADAS_Warning_Flag_23 : 34|1@0+ (1,0) [0|1] "" MHU
  SG_ ADAS_Warning_Flag_24 : 35|1@0+ (1,0) [0|1] "" MHU
  SG_ ADAS_Warning_Flag_25 : 36|1@0+ (1,0) [0|1] "" MHU
  SG_ ADAS_Warning_Flag_26 : 37|1@0+ (1,0) [0|1] "" MHU
  SG_ ADAS_Warning_Flag_27 : 38|1@0+ (1,0) [0|1] "" MHU
  SG_ ADAS_Warning_Flag_28 : 39|1@0+ (1,0) [0|1] "" MHU
  SG_ ADAS_Warning_Flag_29 : 40|1@0+ (1,0) [0|1] "" MHU
  SG_ ADAS_Warning_Flag_30 : 41|1@0+ (1,0) [0|1] "" MHU
  SG_ ADAS_Warning_Flag_31 : 42|1@0+ (1,0) [0|1] "" MHU
  SG_ ADAS_Warning_Flag_32 : 43|1@0+ (1,0) [0|1] "" MHU
  SG_ ADAS_Warning_Flag_33 : 44|1@0+ (1,0) [0|1] "" MHU
  SG_ ADAS_Warning_Flag_34 : 45|1@0+ (1,0) [0|1] "" MHU
  SG_ ADAS_Warning_Flag_35 : 46|1@0+ (1,0) [0|1] "" MHU
  SG_ ADAS_Warning_Flag_36 : 47|1@0+ (1,0) [0|1] "" MHU
  SG_ ADAS_Warning_Flag_37 : 48|1@0+ (1,0) [0|1] "" MHU
  SG_ ADAS_Warning_Flag_38 : 49|1@0+ (1,0) [0|1] "" MHU
  SG_ ADAS_Warning_Flag_39 : 50|1@0+ (1,0) [0|1] "" MHU
  SG_ ADAS_Warning_Flag_40 : 51|1@0+ (1,0) [0|1] "" MHU
  SG_ ADAS_Warning_Flag_41 : 52|1@0+ (1,0) [0|1] "" MHU
  SG_ ADAS_Warning_Flag_42 : 53|1@0+ (1,0) [0|1] "" MHU
  SG_ ADAS_Warning_Flag_43 : 54|1@0+ (1,0) [0|1] "" MHU
  SG_ ADAS_Warning_Flag_44 : 55|1@0+ (1,0) [0|1] "" MHU
  SG_ ADAS_Warning_Flag_45 : 56|1@0+ (1,0) [0|1] "" MHU
  SG_ ADAS_Warning_Flag_46 : 57|1@0+ (1,0) [0|1] "" MHU
  SG_ ADAS_Warning_Flag_47 : 58|1@0+ (1,0) [0|1] "" MHU
  SG_ ADAS_Warning_Flag_48 : 59|1@0+ (1,0) [0|1] "" MHU
  SG_ ADAS_Warning_Flag_49 : 60|1@0+ (1,0) [0|1] "" MHU
  SG_ ADAS_Warning_Flag_50 : 61|1@0+ (1,0) [0|1] "" MHU
  SG_ ADAS_Warning_Flag_51 : 62|1@0+ (1,0) [0|1] "" MHU
  SG_ ADAS_Warning_Flag_52 : 63|1@0+ (1,0) [0|1] "" MHU

BO_ 1034 MHU_HudSetting: 4 MHU
  SG_ MHU_SET_HudBSDOnOff : 0|1@0+ (1,0) [0|1] "" HUD
  SG_ MHU_SET_HudRCTAOnOff : 8|1@0+ (1,0) [0|1] "" HUD
  SG_ MHU_SET_HudUIContent : 3|3@0+ (1,0) [0|7] "-" HUD
  SG_ MHU_SET_HudUIColor : 5|2@0+ (1,0) [0|3] "-" HUD
  SG_ MHU_SET_HudScreenOnOFF : 7|2@0+ (1,0) [0|3] "-" HUD
  SG_ MHU_SET_UserBrightnessLvl : 13|5@0+ (1,0) [0|31] "-" HUD
  SG_ MHU_SET_HudWorkingMode : 15|2@0+ (1,0) [0|3] "-" HUD
  SG_ MHU_SET_HudUISize : 23|2@0+ (1,0) [0|3] "-" HUD
  SG_ MHU_SET_UIContentMediaInfo : 29|1@0+ (1,0) [0|1] "" HUD
  SG_ MHU_SET_UIContentCallInfo : 30|1@0+ (1,0) [0|1] "" HUD
  SG_ MHU_SET_UIContentPoweRegen : 31|1@0+ (1,0) [0|1] "" HUD
  SG_ MHU_SET_HudTurnSigOnOff : 28|1@0+ (1,0) [0|1] "" HUD

BO_ 1035 MHU_Avas_Setting: 1 MHU
  SG_ MHU_SET_AvasSound : 1|2@0+ (1,0) [0|3] "-" XGW_Info

BO_ 1036 MHU_SEAT_CONTROL: 8 MHU
  SG_ CHSKM_MHU_SEAT_CONTROL : 7|8@0+ (1,0) [0|255] "" XGW_Info
  SG_ ALV_MHU_SEAT_CONTROL : 11|4@0+ (1,0) [0|14] "" XGW_Info
  SG_ MHU_DrvSeat_Control_Status : 15|3@0+ (1,0) [0|7] "-" XGW_Info
  SG_ MHU_ExpDrvReclinerPos : 23|7@0+ (1,0) [0|127] "degree" XGW_Info
  SG_ MHU_ExpDrvTiltPos : 31|5@0+ (1,0) [0|31] "mm" XGW_Info
  SG_ MHU_ExpDrvTrackPos : 39|8@0+ (1,0) [0|255] "mm" XGW_Info
  SG_ MHU_ExpDrvHeightPos : 47|6@0+ (1,0) [0|63] "mm" XGW_Info

BO_ 1037 MHU_DIGIT_SPEED: 5 MHU
  SG_ CHKSM_MHU_DIGIT_SPEED : 7|8@0+ (1,0) [0|255] "" ADAS_Info,HUD,XGW_Info
  SG_ ALV_MHU_DIGIT_SPEED : 11|4@0+ (1,0) [0|14] "" ADAS_Info,HUD,XGW_Info
  SG_ MHU_DigitSpeed : 23|9@0+ (1,0) [0|300] "km/h" ADAS_Info,HUD,XGW_Info

BO_ 1038 IC_BORD_COMP_TRIP_A: 8 MHU
  SG_ AveragePwrConsumpTripA : 7|4@0+ (1,0) [0|10] "km/kWh" DUMMY_DEBUG,XGW_Info
  SG_ AverageFuelConsumpTripA : 15|6@0+ (1,0) [0|51] "l/100Km" DUMMY_DEBUG,XGW_Info
  SG_ AvarageSpeedTripA : 23|9@0+ (1,0) [0|300] "kmh" DUMMY_DEBUG,XGW_Info
  SG_ TripA : 39|17@0+ (0.1,0) [0|9999.9] "km" DUMMY_DEBUG,XGW_Info

BO_ 1039 IC_BORD_COMP_TRIP_B: 8 MHU
  SG_ AveragePwrConsumpTripB : 7|4@0+ (1,0) [0|10] "km/kWh" DUMMY_DEBUG,XGW_Info
  SG_ AverageFuelConsumpTripB : 15|6@0+ (1,0) [0|51] "l/100Km" DUMMY_DEBUG,XGW_Info
  SG_ AvarageSpeedTripB : 23|9@0+ (1,0) [0|300] "kmh" DUMMY_DEBUG,XGW_Info
  SG_ TripB : 39|17@0+ (0.1,0) [0|9999.9] "km" DUMMY_DEBUG,XGW_Info

BO_ 1040 IC_BORD_COMP_TRIP_Auto: 8 MHU
  SG_ AveragePwrConsumpTripAuto : 7|4@0+ (1,0) [0|10] "km/kWh" DUMMY_DEBUG,XGW_Info
  SG_ AverageFuelConsumpTripAuto : 15|6@0+ (1,0) [0|51] "l/100Km" DUMMY_DEBUG,XGW_Info
  SG_ AvarageSpeedTripAuto : 23|9@0+ (1,0) [0|300] "kmh" DUMMY_DEBUG,XGW_Info
  SG_ TripAuto : 39|17@0+ (0.1,0) [0|9999.9] "km" DUMMY_DEBUG,XGW_Info

BO_ 1046 BCM_Mirror_Confirm_sts: 8 XGW_Info
  SG_ BCM_STAT_LeftMirrorPosX : 7|8@0+ (1,-15) [-15|15] "deg" MHU
  SG_ BCM_STAT_LeftMirrorPosY : 15|8@0+ (1,-15) [-15|15] "deg" MHU
  SG_ BCM_STAT_RightMirrorPosX : 23|8@0+ (1,-15) [-15|15] "deg" MHU
  SG_ BCM_STAT_RightMirrorPosY : 31|8@0+ (1,-15) [-15|15] "deg" MHU
  SG_ BCM_STAT_Mirror : 37|2@0+ (1,0) [0|3] "" MHU
  SG_ BCM_STAT_MirrorAdjustLeft : 39|2@0+ (1,0) [0|3] "-" MHU
  SG_ BCM_STAT_MirrorAdjustRight : 41|2@0+ (1,0) [0|3] "" MHU

BO_ 1049 SHVU_F_Confirm_Sts: 2 XGW_Info
  SG_ SHVU_STAT_SeatHeatingFrontL : 2|3@0+ (1,0) [0|7] "-" MHU
  SG_ SHVU_STAT_SeatHeatingFrontR : 5|3@0+ (1,0) [0|7] "-" MHU
  SG_ SHVU_STAT_SeatCoolingFrontL : 10|3@0+ (1,0) [0|7] "-" MHU
  SG_ SHVU_STAT_SeatCoolingFrontR : 13|3@0+ (1,0) [0|7] "" MHU
  SG_ SHVU_STAT_FrontSeatVentSts : 15|2@0+ (1,0) [0|3] "" MHU

BO_ 1050 SHVU_R_Confirm_Sts: 2 XGW_Info
  SG_ SHVU_STAT_SeatCoolingRearL : 2|3@0+ (1,0) [0|7] "-" MHU
  SG_ SHVU_STAT_SeatCoolingRearR : 5|3@0+ (1,0) [0|7] "" MHU
  SG_ SHVU_STAT_SeatHeatingReartL : 10|3@0+ (1,0) [0|7] "" MHU
  SG_ SHVU_STAT_SeatHeatingRearR : 13|3@0+ (1,0) [0|7] "" MHU
  SG_ SHVU_STAT_RearSeatVentSts : 15|2@0+ (1,0) [0|3] "" MHU

BO_ 1052 PSM_SEAT_POSITION: 3 XGW_Info
  SG_ CHKSM_PSM_SEAT_POSITION : 7|8@0+ (1,0) [0|255] "" MHU
  SG_ AVL_PSM_SEAT_POSITION : 11|4@0+ (1,0) [0|14] "-" MHU
  SG_ PSM_Seat_track_pos_Dri : 19|2@0+ (1,0) [0|3] "" MHU
  SG_ PSM_Seat_track_posPas : 21|2@0+ (1,0) [0|3] "" MHU

BO_ 1053 BCM_Comfort_Confirm_sts: 8 XGW_Info
  SG_ BCM_STAT_AutoRearWiper : 1|2@0+ (1,0) [0|3] "-" MHU
  SG_ BCM_STAT_MirrorFoldSetting : 3|2@0+ (1,0) [0|3] "" MHU
  SG_ BCM_STAT_IMMO_KeyfobID2 : 7|3@0+ (1,0) [0|7] "" MHU
  SG_ BCM_STAT_MirrorAutoUnfold : 9|2@0+ (1,0) [0|3] "-" MHU
  SG_ BCM_STAT_MirrorReverseLink : 11|2@0+ (1,0) [0|3] "" MHU
  SG_ BCM_STAT_MirrorDefaultSTATting : 13|2@0+ (1,0) [0|3] "-" MHU
  SG_ BCM_STAT_WelcomeTriggerCondition : 15|2@0+ (1,0) [0|3] "" MHU
  SG_ BCM_STAT_FrontDomeLamp : 17|2@0+ (1,0) [0|3] "-" MHU
  SG_ BCM_STAT_FollowMeHome : 20|3@0+ (1,0) [0|7] "-" MHU
  SG_ BCM_STAT_ExteriorLight : 23|3@0+ (1,0) [0|7] "-" MHU
  SG_ BCM_STAT_RemoteLockFeedback : 26|3@0+ (1,0) [0|7] "-" MHU
  SG_ BCM_STAT_RemoteDoorUnlock : 28|2@0+ (1,0) [0|3] "" MHU
  SG_ BCM_STAT_AutoDoorUnlock : 30|2@0+ (1,0) [0|3] "" MHU
  SG_ BCM_STAT_WalkawayDoorLock : 31|1@0+ (1,0) [0|1] "" MHU
  SG_ BCM_STAT_AmbientLightBrighness : 39|7@0+ (1,0) [0|100] "%" MHU
  SG_ BCM_STAT_WiperServiceMode : 42|2@0+ (1,0) [0|3] "" MHU
  SG_ BCM_STAT_IMMO_KeyfobID : 45|2@0+ (1,0) [0|3] "" MHU
  SG_ BCM_STAT_RearHeatedWindowMirror : 47|2@0+ (1,0) [0|3] "" MHU
  SG_ BCM_STAT_AntiTheftMode : 50|3@0+ (1,0) [0|7] "-" MHU
  SG_ BCM_STAT_ClimateKeepOnSts : 53|2@0+ (1,0) [0|3] "" MHU
  SG_ BCM_STAT_FKSfeedback : 55|2@0+ (1,0) [0|3] "" MHU
  SG_ SECCAN_CmftCnfrm : 63|8@0+ (1,0) [0|255] "" MHU

BO_ 1054 HUD_State: 8 HUD
  SG_ HUD_BSDOnOff_Feed : 0|1@0+ (1,0) [0|1] "-" MHU
  SG_ HUD_RCTAOnOff_Feed : 8|1@0+ (1,0) [0|1] "-" MHU
  SG_ HUD_UIColor : 2|2@0+ (1,0) [0|3] "-" MHU
  SG_ HUD_UIContent : 5|3@0+ (1,0) [0|7] "-" MHU
  SG_ HUD_OperationState : 7|2@0+ (1,0) [0|3] "-" MHU
  SG_ HUD_HeightLvl : 13|5@0+ (1,0) [0|31] "-" MHU
  SG_ HUD_UI_Size : 15|2@0+ (1,0) [0|3] "-" MHU
  SG_ HUD_UIContentMediaInfo : 16|1@0+ (1,0) [0|1] "" MHU
  SG_ HUD_UIContentCallInfor : 17|1@0+ (1,0) [0|1] "" MHU
  SG_ HUD_UIContentPowerRegen : 18|1@0+ (1,0) [0|1] "" MHU
  SG_ HUD_UIModeSignal : 21|3@0+ (1,0) [0|7] "-" MHU
  SG_ HUD_WorkingMode : 23|2@0+ (1,0) [0|3] "-" MHU
  SG_ HUD_ActualBrightnes : 31|14@0+ (1,0) [0|12000] "cd/m2" MHU
  SG_ HUD_RotateAngleLvl : 42|4@0+ (1,0) [0|15] "-" MHU
  SG_ HUD_UserSetBrightnessLvl : 47|5@0+ (1,0) [0|31] "-" MHU
  SG_ HUD_Language : 54|5@0+ (1,0) [0|31] "-" MHU
  SG_ HUD_TurnSigOnOff_Feed : 56|1@0+ (1,0) [0|1] "-" MHU
  SG_ HUD_Mileage_Unit : 57|1@0+ (1,0) [0|1] "-" MHU
  SG_ HUD_UserProfileId : 61|4@0+ (1,0) [0|15] "-" MHU
  SG_ HUD_DimmingDelayTime : 63|2@0+ (1,0) [0|3] "-" MHU

BO_ 1055 Sensor_Fault: 8 ADAS_Info
  SG_ CHKSM_SensorFault : 7|8@0+ (1,0) [0|255] "" MHU
  SG_ ALV_Sensor_Fault : 11|4@0+ (1,0) [0|14] "" MHU
  SG_ ADAS_SVM_LCamera_Fault : 17|2@0+ (1,0) [0|3] "-" MHU
  SG_ ADAS_USS_Front_Fault : 19|2@0+ (1,0) [0|3] "-" MHU
  SG_ ADAS_SVM_FCamera_Fault : 21|2@0+ (1,0) [0|3] "-" MHU
  SG_ ADAS_SRR_RR_Fault : 23|2@0+ (1,0) [0|3] "-" MHU
  SG_ ADAS_SRR_FR_Fault : 25|2@0+ (1,0) [0|3] "-" MHU
  SG_ ADAS_SVM_RCamera_Fault : 27|2@0+ (1,0) [0|3] "-" MHU
  SG_ ADAS_USS_Rear_Fault : 29|2@0+ (1,0) [0|3] "-" MHU
  SG_ ADAS_SCAM_Fault : 31|2@0+ (1,0) [0|3] "-" MHU
  SG_ ADAS_MRR_Fault : 33|2@0+ (1,0) [0|3] "-" MHU
  SG_ ADAS_SRR_RL_Fault : 35|2@0+ (1,0) [0|3] "-" MHU
  SG_ ADAS_SVM_RightCamera_Fault : 39|2@0+ (1,0) [0|3] "-" MHU
  SG_ ADAS_ECU_Fault : 41|2@0+ (1,0) [0|3] "-" MHU
  SG_ ADAS_SRR_FL_Fault : 43|2@0+ (1,0) [0|3] "-" MHU
  SG_ ADAS_APAUSS_Rear_Fault : 45|2@0+ (1,0) [0|3] "-" MHU
  SG_ ADAS_APAUSS_Front_Fault : 47|2@0+ (1,0) [0|3] "-" MHU
  SG_ SECCAN_SensorFault : 63|8@0+ (1,0) [0|255] "" MHU
